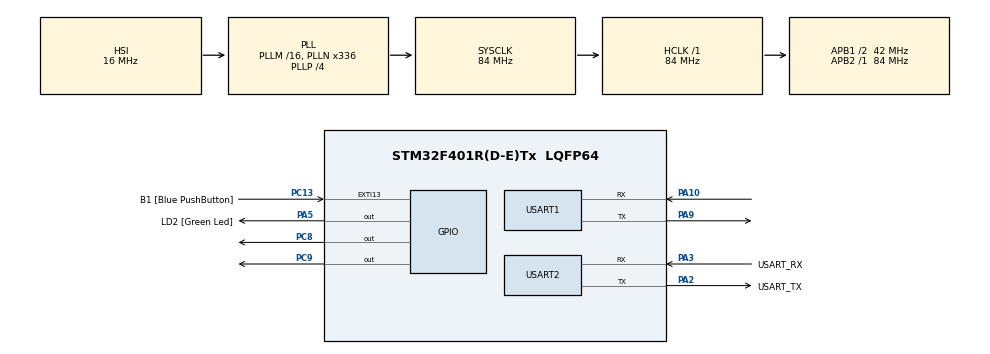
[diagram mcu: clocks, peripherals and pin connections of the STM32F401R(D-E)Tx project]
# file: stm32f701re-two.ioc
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Mcu.Family=STM32F4
Mcu.Name=STM32F401R(D-E)Tx
Mcu.Package=LQFP64
NVIC.PriorityGroup=NVIC_PRIORITYGROUP_0
PA10.Mode=Asynchronous
PA10.Signal=USART1_RX
PA13.GPIO_Label=TMS
PA13.Signal=SYS_JTMS-SWDIO
PA14.GPIO_Label=TCK
PA14.Signal=SYS_JTCK-SWCLK
PA2.GPIO_Label=USART_TX
PA2.GPIO_Mode=GPIO_MODE_AF_PP
PA2.GPIO_PuPd=GPIO_NOPULL
PA2.GPIO_Speed=GPIO_SPEED_FREQ_LOW
PA2.Mode=Asynchronous
PA2.Signal=USART2_TX
PA3.GPIO_Label=USART_RX
PA3.GPIO_Mode=GPIO_MODE_AF_PP
PA3.GPIO_PuPd=GPIO_NOPULL
PA3.GPIO_Speed=GPIO_SPEED_FREQ_LOW
PA3.Mode=Asynchronous
PA3.Signal=USART2_RX
PA5.GPIO_Label=LD2 [Green Led]
PA5.GPIO_Mode=GPIO_MODE_OUTPUT_PP
PA5.GPIO_PuPd=GPIO_NOPULL
PA5.GPIO_Speed=GPIO_SPEED_FREQ_LOW
PA5.Signal=GPIO_Output
PA9.Mode=Asynchronous
PA9.Signal=USART1_TX
PB3.GPIO_Label=SWO
PB3.Signal=SYS_JTDO-SWO
PC13-ANTI_TAMP.GPIO_Label=B1 [Blue PushButton]
PC13-ANTI_TAMP.GPIO_ModeDefaultEXTI=GPIO_MODE_IT_FALLING
PC13-ANTI_TAMP.GPIO_PuPd=GPIO_NOPULL
PC13-ANTI_TAMP.Signal=GPXTI13
PC14-OSC32_IN.Signal=RCC_OSC32_IN
PC15-OSC32_OUT.Signal=RCC_OSC32_OUT
PC8.Signal=GPIO_Output
PC9.Signal=GPIO_Output
PH0\ -\ OSC_IN.Signal=RCC_OSC_IN
PH1\ -\ OSC_OUT.Signal=RCC_OSC_OUT
ProjectManager.HeapSize=0x200
ProjectManager.StackSize=0x400
ProjectManager.TargetToolchain=STM32CubeIDE
RCC.AHBFreq_Value=84000000
RCC.APB1CLKDivider=RCC_HCLK_DIV2
RCC.APB1Freq_Value=42000000
RCC.APB1TimFreq_Value=84000000
RCC.APB2Freq_Value=84000000
RCC.APB2TimFreq_Value=84000000
RCC.CortexFreq_Value=84000000
RCC.HCLKFreq_Value=84000000
RCC.HSE_VALUE=8000000
RCC.HSI_VALUE=16000000
RCC.LSE_VALUE=32768
RCC.PLLN=336
RCC.PLLP=RCC_PLLP_DIV4
RCC.PLLQ=7
RCC.SYSCLKFreq_VALUE=84000000
RCC.SYSCLKSource=RCC_SYSCLKSOURCE_PLLCLK
RCC.VCOOutputFreq_Value=336000000
USART1.Parity=PARITY_EVEN
USART1.VirtualMode=VM_ASYNC
USART1.WordLength=WORDLENGTH_9B
USART2.VirtualMode=VM_ASYNC
board=NUCLEO-F401RE

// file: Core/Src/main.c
/* USER CODE BEGIN Header */
/**
  ******************************************************************************
  * @file           : main.c
  * @brief          : Main program body
  ******************************************************************************
  * @attention
  *
  * Copyright (c) 2022 STMicroelectronics.
  * All rights reserved.
  *
  * This software is licensed under terms that can be found in the LICENSE file
  * in the root directory of this software component.
  * If no LICENSE file comes with this software, it is provided AS-IS.
  *
  ******************************************************************************
  */
/* USER CODE END Header */
#include "main.h"

/* USER CODE BEGIN Includes */
#include "bootloader.h"
#include <string.h>
/* USER CODE END Includes */

UART_HandleTypeDef huart1;
UART_HandleTypeDef huart2;

/* USER CODE BEGIN PV */
uint8_t rcv_mul[10] = {0};
uint8_t receive_cmd_response_main = {0};
uint8_t it_response = {0};
//uint8_t invoke_uart = 0x7f;
uint8_t get_cmd[2] = {0x00, 0x00^0xff};
uint8_t bl_ver[2] = {0x01, 0x01^0xff};
uint8_t get_id_cmd[2] = {0x02, 0x02^0xff};
uint8_t read_memory_cmd[2] = {0x11, 0x11^0xff};
uint8_t write_memory_cmd[2] = {0x31, 0x31^0xff};
uint8_t clear_memory_cmd[2] = {0x44, 0x44^0xff};
uint8_t go_cmd[2] = {0x21, 0x21^0xff};

//binary(hex) to flash to target device
uint8_t bin_to_flash[] = {0x00, 0x00, 0x10, 0x24, 0x1D, 0x0C, 0x00, 0x08, 0xD9, 0x0A, 0x00, 0x08, 0xDF, 0x0A, 0x00, 0x08,
		  0xE5, 0x0A, 0x00, 0x08, 0xEB, 0x0A, 0x00, 0x08, 0xF1, 0x0A, 0x00, 0x08, 0x00, 0x00, 0x00, 0x00,
		  0x00, 0x00, 0x00, 0x00, 0x00, 0x00, 0x00, 0x00, 0x00, 0x00, 0x00, 0x00, 0xF7, 0x0A, 0x00, 0x08,
		  0x05, 0x0B, 0x00, 0x08, 0x00, 0x00, 0x00, 0x00, 0x13, 0x0B, 0x00, 0x08, 0x21, 0x0B, 0x00, 0x08,
		  0x6D, 0x0C, 0x00, 0x08, 0x6D, 0x0C, 0x00, 0x08, 0x6D, 0x0C, 0x00, 0x08, 0x6D, 0x0C, 0x00, 0x08,
		  0x6D, 0x0C, 0x00, 0x08, 0x6D, 0x0C, 0x00, 0x08, 0x6D, 0x0C, 0x00, 0x08, 0x6D, 0x0C, 0x00, 0x08,
		  0x6D, 0x0C, 0x00, 0x08, 0x6D, 0x0C, 0x00, 0x08, 0x6D, 0x0C, 0x00, 0x08, 0x6D, 0x0C, 0x00, 0x08,
		  0x6D, 0x0C, 0x00, 0x08, 0x6D, 0x0C, 0x00, 0x08, 0x6D, 0x0C, 0x00, 0x08, 0x6D, 0x0C, 0x00, 0x08,
		  0x6D, 0x0C, 0x00, 0x08, 0x6D, 0x0C, 0x00, 0x08, 0x6D, 0x0C, 0x00, 0x08, 0x6D, 0x0C, 0x00, 0x08,
		  0x6D, 0x0C, 0x00, 0x08, 0x6D, 0x0C, 0x00, 0x08, 0x6D, 0x0C, 0x00, 0x08, 0x6D, 0x0C, 0x00, 0x08,
		  0x6D, 0x0C, 0x00, 0x08, 0x6D, 0x0C, 0x00, 0x08, 0x6D, 0x0C, 0x00, 0x08, 0x6D, 0x0C, 0x00, 0x08,
		  0x6D, 0x0C, 0x00, 0x08, 0x6D, 0x0C, 0x00, 0x08, 0x6D, 0x0C, 0x00, 0x08, 0x6D, 0x0C, 0x00, 0x08,
		  0x6D, 0x0C, 0x00, 0x08, 0x6D, 0x0C, 0x00, 0x08, 0x6D, 0x0C, 0x00, 0x08, 0x6D, 0x0C, 0x00, 0x08,
		  0x6D, 0x0C, 0x00, 0x08, 0x6D, 0x0C, 0x00, 0x08, 0x6D, 0x0C, 0x00, 0x08, 0x6D, 0x0C, 0x00, 0x08,
		  0x6D, 0x0C, 0x00, 0x08, 0x6D, 0x0C, 0x00, 0x08, 0x6D, 0x0C, 0x00, 0x08, 0x6D, 0x0C, 0x00, 0x08,
		  0x6D, 0x0C, 0x00, 0x08, 0x6D, 0x0C, 0x00, 0x08, 0x6D, 0x0C, 0x00, 0x08, 0x6D, 0x0C, 0x00, 0x08,
		  0x6D, 0x0C, 0x00, 0x08, 0x6D, 0x0C, 0x00, 0x08, 0x6D, 0x0C, 0x00, 0x08, 0x6D, 0x0C, 0x00, 0x08,
		  0x6D, 0x0C, 0x00, 0x08, 0x6D, 0x0C, 0x00, 0x08, 0x6D, 0x0C, 0x00, 0x08, 0x6D, 0x0C, 0x00, 0x08,
		  0x6D, 0x0C, 0x00, 0x08, 0x6D, 0x0C, 0x00, 0x08, 0x6D, 0x0C, 0x00, 0x08, 0x6D, 0x0C, 0x00, 0x08,
		  0x6D, 0x0C, 0x00, 0x08, 0x00, 0x00, 0x00, 0x00, 0x00, 0x00, 0x00, 0x00, 0x6D, 0x0C, 0x00, 0x08,
		  0x6D, 0x0C, 0x00, 0x08, 0x6D, 0x0C, 0x00, 0x08, 0x6D, 0x0C, 0x00, 0x08, 0x6D, 0x0C, 0x00, 0x08,
		  0x6D, 0x0C, 0x00, 0x08, 0x6D, 0x0C, 0x00, 0x08, 0x6D, 0x0C, 0x00, 0x08, 0x6D, 0x0C, 0x00, 0x08,
		  0x6D, 0x0C, 0x00, 0x08, 0x6D, 0x0C, 0x00, 0x08, 0x6D, 0x0C, 0x00, 0x08, 0x6D, 0x0C, 0x00, 0x08,
		  0x6D, 0x0C, 0x00, 0x08, 0x6D, 0x0C, 0x00, 0x08, 0x6D, 0x0C, 0x00, 0x08, 0x00, 0x00, 0x00, 0x00,
		  0x6D, 0x0C, 0x00, 0x08, 0x6D, 0x0C, 0x00, 0x08, 0x6D, 0x0C, 0x00, 0x08, 0x6D, 0x0C, 0x00, 0x08,
		  0x6D, 0x0C, 0x00, 0x08, 0x6D, 0x0C, 0x00, 0x08, 0x6D, 0x0C, 0x00, 0x08, 0x6D, 0x0C, 0x00, 0x08,
		  0x6D, 0x0C, 0x00, 0x08, 0x6D, 0x0C, 0x00, 0x08, 0x6D, 0x0C, 0x00, 0x08, 0x6D, 0x0C, 0x00, 0x08,
		  0x6D, 0x0C, 0x00, 0x08, 0x6D, 0x0C, 0x00, 0x08, 0x6D, 0x0C, 0x00, 0x08, 0x6D, 0x0C, 0x00, 0x08,
		  0x6D, 0x0C, 0x00, 0x08, 0x6D, 0x0C, 0x00, 0x08, 0x00, 0x00, 0x00, 0x00, 0x00, 0x00, 0x00, 0x00,
		  0x00, 0x00, 0x00, 0x00, 0x00, 0x00, 0x00, 0x00, 0x6D, 0x0C, 0x00, 0x08, 0x00, 0x00, 0x00, 0x00,
		  0x00, 0x00, 0x00, 0x00, 0x00, 0x00, 0x00, 0x00, 0x00, 0x00, 0x00, 0x00, 0x00, 0x00, 0x00, 0x00,
		  0x00, 0x00, 0x00, 0x00, 0x00, 0x00, 0x00, 0x00, 0x6D, 0x0C, 0x00, 0x08, 0x6D, 0x0C, 0x00, 0x08,
		  0x6D, 0x0C, 0x00, 0x08, 0x6D, 0x0C, 0x00, 0x08, 0x00, 0x00, 0x00, 0x00, 0x6D, 0x0C, 0x00, 0x08,
		  0x6D, 0x0C, 0x00, 0x08, 0x6D, 0x0C, 0x00, 0x08, 0x6D, 0x0C, 0x00, 0x08, 0x6D, 0x0C, 0x00, 0x08,
		  0x6D, 0x0C, 0x00, 0x08, 0x6D, 0x0C, 0x00, 0x08, 0x6D, 0x0C, 0x00, 0x08, 0x00, 0x00, 0x00, 0x00,
		  0x6D, 0x0C, 0x00, 0x08, 0x6D, 0x0C, 0x00, 0x08, 0x00, 0x00, 0x00, 0x00, 0x6D, 0x0C, 0x00, 0x08,
		  0x6D, 0x0C, 0x00, 0x08, 0x6D, 0x0C, 0x00, 0x08, 0x6D, 0x0C, 0x00, 0x08, 0x6D, 0x0C, 0x00, 0x08,
		  0x6D, 0x0C, 0x00, 0x08, 0x6D, 0x0C, 0x00, 0x08, 0x6D, 0x0C, 0x00, 0x08, 0x6D, 0x0C, 0x00, 0x08,
		  0x6D, 0x0C, 0x00, 0x08, 0x6D, 0x0C, 0x00, 0x08, 0x6D, 0x0C, 0x00, 0x08, 0x6D, 0x0C, 0x00, 0x08,
		  0x6D, 0x0C, 0x00, 0x08, 0x6D, 0x0C, 0x00, 0x08, 0x6D, 0x0C, 0x00, 0x08, 0x00, 0x00, 0x00, 0x00,
		  0x6D, 0x0C, 0x00, 0x08, 0x6D, 0x0C, 0x00, 0x08, 0x00, 0x00, 0x00, 0x00, 0x6D, 0x0C, 0x00, 0x08,
		  0x00, 0x00, 0x00, 0x00, 0x6D, 0x0C, 0x00, 0x08, 0x6D, 0x0C, 0x00, 0x08, 0x00, 0x00, 0x00, 0x00,
		  0x00, 0x00, 0x00, 0x00, 0x6D, 0x0C, 0x00, 0x08, 0x6D, 0x0C, 0x00, 0x08, 0x10, 0xB5, 0x05, 0x4C,
		  0x23, 0x78, 0x33, 0xB9, 0x04, 0x4B, 0x13, 0xB1, 0x04, 0x48, 0xAF, 0xF3, 0x00, 0x80, 0x01, 0x23,
		  0x23, 0x70, 0x10, 0xBD, 0x10, 0x00, 0x00, 0x24, 0x00, 0x00, 0x00, 0x00, 0xC0, 0x4C, 0x00, 0x08,
		  0x08, 0xB5, 0x03, 0x4B, 0x1B, 0xB1, 0x03, 0x49, 0x03, 0x48, 0xAF, 0xF3, 0x00, 0x80, 0x08, 0xBD,
		  0x00, 0x00, 0x00, 0x00, 0x14, 0x00, 0x00, 0x24, 0xC0, 0x4C, 0x00, 0x08, 0x53, 0xB9, 0x4A, 0xB9,
		  0x00, 0x29, 0x08, 0xBF, 0x00, 0x28, 0x1C, 0xBF, 0x4F, 0xF0, 0xFF, 0x31, 0x4F, 0xF0, 0xFF, 0x30,
		  0x00, 0xF0, 0x6E, 0xB9, 0xAD, 0xF1, 0x08, 0x0C, 0x6D, 0xE9, 0x04, 0xCE, 0x00, 0xF0, 0x06, 0xF8,
		  0xDD, 0xF8, 0x04, 0xE0, 0xDD, 0xE9, 0x02, 0x23, 0x04, 0xB0, 0x70, 0x47, 0x2D, 0xE9, 0xF0, 0x47,
		  0x08, 0x9D, 0x04, 0x46, 0x8C, 0x46, 0x00, 0x2B, 0x40, 0xF0, 0x83, 0x80, 0x8A, 0x42, 0x17, 0x46,
		  0x47, 0xD9, 0xB2, 0xFA, 0x82, 0xF2, 0x42, 0xB1, 0xC2, 0xF1, 0x20, 0x00, 0x24, 0xFA, 0x00, 0xF0,
		  0x91, 0x40, 0x97, 0x40, 0x40, 0xEA, 0x01, 0x0C, 0x94, 0x40, 0x4F, 0xEA, 0x17, 0x48, 0x23, 0x0C,
		  0xBC, 0xFB, 0xF8, 0xF6, 0x1F, 0xFA, 0x87, 0xFE, 0x08, 0xFB, 0x16, 0xC1, 0x43, 0xEA, 0x01, 0x43,
		  0x06, 0xFB, 0x0E, 0xF1, 0x99, 0x42, 0x09, 0xD9, 0xFB, 0x18, 0x06, 0xF1, 0xFF, 0x30, 0x80, 0xF0,
		  0x19, 0x81, 0x99, 0x42, 0x40, 0xF2, 0x16, 0x81, 0x02, 0x3E, 0x3B, 0x44, 0x5B, 0x1A, 0xA4, 0xB2,
		  0xB3, 0xFB, 0xF8, 0xF0, 0x08, 0xFB, 0x10, 0x33, 0x44, 0xEA, 0x03, 0x44, 0x00, 0xFB, 0x0E, 0xFE,
		  0xA6, 0x45, 0x09, 0xD9, 0x3C, 0x19, 0x00, 0xF1, 0xFF, 0x33, 0x80, 0xF0, 0x05, 0x81, 0xA6, 0x45,
		  0x40, 0xF2, 0x02, 0x81, 0x02, 0x38, 0x3C, 0x44, 0x40, 0xEA, 0x06, 0x40, 0xA4, 0xEB, 0x0E, 0x04,
		  0x00, 0x26, 0x1D, 0xB1, 0xD4, 0x40, 0x00, 0x23, 0xC5, 0xE9, 0x00, 0x43, 0x31, 0x46, 0xBD, 0xE8,
		  0xF0, 0x87, 0x02, 0xB9, 0xFF, 0xDE, 0xB2, 0xFA, 0x82, 0xF2, 0x00, 0x2A, 0x50, 0xD1, 0xCB, 0x1B,
		  0x4F, 0xEA, 0x17, 0x4E, 0x1F, 0xFA, 0x87, 0xF8, 0x01, 0x26, 0xB3, 0xFB, 0xFE, 0xFC, 0x21, 0x0C,
		  0x0E, 0xFB, 0x1C, 0x33, 0x41, 0xEA, 0x03, 0x41, 0x08, 0xFB, 0x0C, 0xF3, 0x8B, 0x42, 0x07, 0xD9,
		  0x79, 0x18, 0x0C, 0xF1, 0xFF, 0x30, 0x02, 0xD2, 0x8B, 0x42, 0x00, 0xF2, 0xE9, 0x80, 0x84, 0x46,
		  0xC9, 0x1A, 0xA3, 0xB2, 0xB1, 0xFB, 0xFE, 0xF0, 0x0E, 0xFB, 0x10, 0x11, 0x43, 0xEA, 0x01, 0x44,
		  0x08, 0xFB, 0x00, 0xF8, 0xA0, 0x45, 0x07, 0xD9, 0x3C, 0x19, 0x00, 0xF1, 0xFF, 0x33, 0x02, 0xD2,
		  0xA0, 0x45, 0x00, 0xF2, 0xD9, 0x80, 0x18, 0x46, 0xA4, 0xEB, 0x08, 0x04, 0x40, 0xEA, 0x0C, 0x40,
		  0xBF, 0xE7, 0x8B, 0x42, 0x09, 0xD9, 0x00, 0x2D, 0x00, 0xF0, 0xB1, 0x80, 0x00, 0x26, 0xC5, 0xE9,
		  0x00, 0x01, 0x30, 0x46, 0x31, 0x46, 0xBD, 0xE8, 0xF0, 0x87, 0xB3, 0xFA, 0x83, 0xF6, 0x00, 0x2E,
		  0x4A, 0xD1, 0x8B, 0x42, 0x02, 0xD3, 0x82, 0x42, 0x00, 0xF2, 0xB8, 0x80, 0x84, 0x1A, 0x61, 0xEB,
		  0x03, 0x01, 0x01, 0x20, 0x8C, 0x46, 0x00, 0x2D, 0xA8, 0xD0, 0xC5, 0xE9, 0x00, 0x4C, 0xA5, 0xE7,
		  0xC2, 0xF1, 0x20, 0x03, 0x20, 0xFA, 0x03, 0xF6, 0x97, 0x40, 0x01, 0xFA, 0x02, 0xF0, 0x4F, 0xEA,
		  0x17, 0x4E, 0xD9, 0x40, 0x30, 0x43, 0x03, 0x0C, 0xB1, 0xFB, 0xFE, 0xF6, 0x1F, 0xFA, 0x87, 0xF8,
		  0x0E, 0xFB, 0x16, 0x11, 0x43, 0xEA, 0x01, 0x43, 0x06, 0xFB, 0x08, 0xF1, 0x99, 0x42, 0x04, 0xFA,
		  0x02, 0xF4, 0x09, 0xD9, 0xFB, 0x18, 0x06, 0xF1, 0xFF, 0x3C, 0x80, 0xF0, 0x8D, 0x80, 0x99, 0x42,
		  0x40, 0xF2, 0x8A, 0x80, 0x02, 0x3E, 0x3B, 0x44, 0x5B, 0x1A, 0x81, 0xB2, 0xB3, 0xFB, 0xFE, 0xF0,
		  0x0E, 0xFB, 0x10, 0x33, 0x41, 0xEA, 0x03, 0x41, 0x00, 0xFB, 0x08, 0xF3, 0x8B, 0x42, 0x07, 0xD9,
		  0x79, 0x18, 0x00, 0xF1, 0xFF, 0x3C, 0x73, 0xD2, 0x8B, 0x42, 0x71, 0xD9, 0x02, 0x38, 0x39, 0x44,
		  0xCB, 0x1A, 0x40, 0xEA, 0x06, 0x46, 0x78, 0xE7, 0xC6, 0xF1, 0x20, 0x0C, 0x03, 0xFA, 0x06, 0xF4,
		  0x22, 0xFA, 0x0C, 0xF3, 0x1C, 0x43, 0x20, 0xFA, 0x0C, 0xF7, 0x01, 0xFA, 0x06, 0xF3, 0x4F, 0xEA,
		  0x14, 0x4E, 0x21, 0xFA, 0x0C, 0xF1, 0x1F, 0x43, 0x3B, 0x0C, 0xB1, 0xFB, 0xFE, 0xF9, 0x1F, 0xFA,
		  0x84, 0xF8, 0x0E, 0xFB, 0x19, 0x11, 0x43, 0xEA, 0x01, 0x41, 0x09, 0xFB, 0x08, 0xFA, 0x8A, 0x45,
		  0x02, 0xFA, 0x06, 0xF2, 0x00, 0xFA, 0x06, 0xF3, 0x08, 0xD9, 0x61, 0x18, 0x09, 0xF1, 0xFF, 0x30,
		  0x48, 0xD2, 0x8A, 0x45, 0x46, 0xD9, 0xA9, 0xF1, 0x02, 0x09, 0x21, 0x44, 0xA1, 0xEB, 0x0A, 0x01,
		  0xBF, 0xB2, 0xB1, 0xFB, 0xFE, 0xF0, 0x0E, 0xFB, 0x10, 0x11, 0x47, 0xEA, 0x01, 0x47, 0x00, 0xFB,
		  0x08, 0xF8, 0xB8, 0x45, 0x07, 0xD9, 0xE7, 0x19, 0x00, 0xF1, 0xFF, 0x31, 0x2E, 0xD2, 0xB8, 0x45,
		  0x2C, 0xD9, 0x02, 0x38, 0x27, 0x44, 0x40, 0xEA, 0x09, 0x40, 0xA7, 0xEB, 0x08, 0x07, 0xA0, 0xFB,
		  0x02, 0x89, 0x4F, 0x45, 0xC6, 0x46, 0x49, 0x46, 0x1A, 0xD3, 0x17, 0xD0, 0x5D, 0xB1, 0xB3, 0xEB,
		  0x0E, 0x02, 0x67, 0xEB, 0x01, 0x07, 0x07, 0xFA, 0x0C, 0xFC, 0xF2, 0x40, 0x4C, 0xEA, 0x02, 0x02,
		  0xF7, 0x40, 0xC5, 0xE9, 0x00, 0x27, 0x00, 0x26, 0x31, 0x46, 0xBD, 0xE8, 0xF0, 0x87, 0x2E, 0x46,
		  0x28, 0x46, 0x0B, 0xE7, 0x06, 0x46, 0xE9, 0xE6, 0x18, 0x46, 0xFD, 0xE6, 0x43, 0x45, 0xE5, 0xD2,
		  0xB8, 0xEB, 0x02, 0x0E, 0x69, 0xEB, 0x04, 0x01, 0x01, 0x38, 0xDF, 0xE7, 0x08, 0x46, 0xD2, 0xE7,
		  0x60, 0x46, 0x8D, 0xE7, 0x81, 0x46, 0xB9, 0xE7, 0x66, 0x46, 0x75, 0xE7, 0x30, 0x46, 0x4A, 0xE7,
		  0xAC, 0xF1, 0x02, 0x0C, 0x39, 0x44, 0x13, 0xE7, 0x02, 0x38, 0x3C, 0x44, 0x24, 0xE7, 0x00, 0xBF,
		  0x70, 0x47, 0x00, 0xBF, 0x80, 0xB5, 0x00, 0xAF, 0x00, 0xF0, 0x42, 0xFB, 0x00, 0xF0, 0x10, 0xF8,
		  0x00, 0xF0, 0xCE, 0xF8, 0x00, 0xF0, 0x80, 0xF8, 0x4F, 0xF4, 0x80, 0x41, 0x03, 0x48, 0x00, 0xF0,
		  0x9A, 0xFE, 0x4F, 0xF4, 0x7A, 0x70, 0x00, 0xF0, 0xC5, 0xFB, 0xF5, 0xE7, 0x00, 0x04, 0x02, 0x58,
		  0x80, 0xB5, 0x9C, 0xB0, 0x00, 0xAF, 0x07, 0xF1, 0x24, 0x03, 0x4C, 0x22, 0x00, 0x21, 0x18, 0x46,
		  0x04, 0xF0, 0x46, 0xFB, 0x3B, 0x1D, 0x20, 0x22, 0x00, 0x21, 0x18, 0x46, 0x04, 0xF0, 0x40, 0xFB,
		  0x2F, 0x4B, 0x4F, 0xF0, 0xFF, 0x32, 0xC3, 0xF8, 0xB0, 0x20, 0x04, 0x20, 0x00, 0xF0, 0x96, 0xFE,
		  0x00, 0x23, 0x3B, 0x60, 0x2B, 0x4B, 0x9B, 0x69, 0x2A, 0x4A, 0x43, 0xF4, 0x40, 0x43, 0x93, 0x61,
		  0x28, 0x4B, 0x9B, 0x69, 0x03, 0xF4, 0x40, 0x43, 0x3B, 0x60, 0x3B, 0x68, 0x00, 0xBF, 0x25, 0x4B,
		  0x9B, 0x69, 0x03, 0xF4, 0x00, 0x53, 0xB3, 0xF5, 0x00, 0x5F, 0xF8, 0xD1, 0x02, 0x23, 0x7B, 0x62,
		  0x01, 0x23, 0x3B, 0x63, 0x40, 0x23, 0x7B, 0x63, 0x02, 0x23, 0xBB, 0x64, 0x00, 0x23, 0xFB, 0x64,
		  0x04, 0x23, 0x3B, 0x65, 0x08, 0x23, 0x7B, 0x65, 0x02, 0x23, 0xBB, 0x65, 0x04, 0x23, 0xFB, 0x65,
		  0x02, 0x23, 0x3B, 0x66, 0x0C, 0x23, 0x7B, 0x66, 0x00, 0x23, 0xBB, 0x66, 0x00, 0x23, 0xFB, 0x66,
		  0x07, 0xF1, 0x24, 0x03, 0x18, 0x46, 0x00, 0xF0, 0xBB, 0xFE, 0x03, 0x46, 0x00, 0x2B, 0x01, 0xD0,
		  0x00, 0xF0, 0x8E, 0xF9, 0x3F, 0x23, 0x7B, 0x60, 0x03, 0x23, 0xBB, 0x60, 0x00, 0x23, 0xFB, 0x60,
		  0x00, 0x23, 0x3B, 0x61, 0x00, 0x23, 0x7B, 0x61, 0x00, 0x23, 0xBB, 0x61, 0x00, 0x23, 0xFB, 0x61,
		  0x00, 0x23, 0x3B, 0x62, 0x3B, 0x1D, 0x01, 0x21, 0x18, 0x46, 0x01, 0xF0, 0xA5, 0xFA, 0x03, 0x46,
		  0x00, 0x2B, 0x01, 0xD0, 0x00, 0xF0, 0x74, 0xF9, 0x00, 0xBF, 0x70, 0x37, 0xBD, 0x46, 0x80, 0xBD,
		  0x00, 0x44, 0x02, 0x58, 0x00, 0x48, 0x02, 0x58, 0x80, 0xB5, 0x00, 0xAF, 0x22, 0x4B, 0x23, 0x4A,
		  0x1A, 0x60, 0x21, 0x4B, 0x4F, 0xF4, 0xE1, 0x32, 0x5A, 0x60, 0x1F, 0x4B, 0x00, 0x22, 0x9A, 0x60,
		  0x1D, 0x4B, 0x00, 0x22, 0xDA, 0x60, 0x1C, 0x4B, 0x00, 0x22, 0x1A, 0x61, 0x1A, 0x4B, 0x0C, 0x22,
		  0x5A, 0x61, 0x19, 0x4B, 0x00, 0x22, 0x9A, 0x61, 0x17, 0x4B, 0x00, 0x22, 0xDA, 0x61, 0x16, 0x4B,
		  0x00, 0x22, 0x1A, 0x62, 0x14, 0x4B, 0x00, 0x22, 0x5A, 0x62, 0x13, 0x4B, 0x00, 0x22, 0x9A, 0x62,
		  0x11, 0x48, 0x03, 0xF0, 0x2B, 0xF9, 0x03, 0x46, 0x00, 0x2B, 0x01, 0xD0, 0x00, 0xF0, 0x40, 0xF9,
		  0x00, 0x21, 0x0D, 0x48, 0x04, 0xF0, 0xBE, 0xF9, 0x03, 0x46, 0x00, 0x2B, 0x01, 0xD0, 0x00, 0xF0,
		  0x37, 0xF9, 0x00, 0x21, 0x08, 0x48, 0x04, 0xF0, 0xF3, 0xF9, 0x03, 0x46, 0x00, 0x2B, 0x01, 0xD0,
		  0x00, 0xF0, 0x2E, 0xF9, 0x04, 0x48, 0x04, 0xF0, 0x74, 0xF9, 0x03, 0x46, 0x00, 0x2B, 0x01, 0xD0,
		  0x00, 0xF0, 0x26, 0xF9, 0x00, 0xBF, 0x80, 0xBD, 0x2C, 0x00, 0x00, 0x24, 0x00, 0x4C, 0x00, 0x40,
		  0x80, 0xB5, 0x8E, 0xB0, 0x00, 0xAF, 0x07, 0xF1, 0x24, 0x03, 0x00, 0x22, 0x1A, 0x60, 0x5A, 0x60,
		  0x9A, 0x60, 0xDA, 0x60, 0x1A, 0x61, 0x82, 0x4B, 0xD3, 0xF8, 0x40, 0x31, 0x80, 0x4A, 0x43, 0xF0,
		  0x04, 0x03, 0xC2, 0xF8, 0x40, 0x31, 0x7E, 0x4B, 0xD3, 0xF8, 0x40, 0x31, 0x03, 0xF0, 0x04, 0x03,
		  0x3B, 0x62, 0x3B, 0x6A, 0x7A, 0x4B, 0xD3, 0xF8, 0x40, 0x31, 0x79, 0x4A, 0x43, 0xF0, 0x20, 0x03,
		  0xC2, 0xF8, 0x40, 0x31, 0x76, 0x4B, 0xD3, 0xF8, 0x40, 0x31, 0x03, 0xF0, 0x20, 0x03, 0xFB, 0x61,
		  0xFB, 0x69, 0x73, 0x4B, 0xD3, 0xF8, 0x40, 0x31, 0x71, 0x4A, 0x43, 0xF0, 0x80, 0x03, 0xC2, 0xF8,
		  0x40, 0x31, 0x6F, 0x4B, 0xD3, 0xF8, 0x40, 0x31, 0x03, 0xF0, 0x80, 0x03, 0xBB, 0x61, 0xBB, 0x69,
		  0x6B, 0x4B, 0xD3, 0xF8, 0x40, 0x31, 0x6A, 0x4A, 0x43, 0xF0, 0x01, 0x03, 0xC2, 0xF8, 0x40, 0x31,
		  0x67, 0x4B, 0xD3, 0xF8, 0x40, 0x31, 0x03, 0xF0, 0x01, 0x03, 0x7B, 0x61, 0x7B, 0x69, 0x64, 0x4B,
		  0xD3, 0xF8, 0x40, 0x31, 0x62, 0x4A, 0x43, 0xF0, 0x02, 0x03, 0xC2, 0xF8, 0x40, 0x31, 0x60, 0x4B,
		  0xD3, 0xF8, 0x40, 0x31, 0x03, 0xF0, 0x02, 0x03, 0x3B, 0x61, 0x3B, 0x69, 0x5C, 0x4B, 0xD3, 0xF8,
		  0x40, 0x31, 0x5B, 0x4A, 0x43, 0xF0, 0x08, 0x03, 0xC2, 0xF8, 0x40, 0x31, 0x58, 0x4B, 0xD3, 0xF8,
		  0x40, 0x31, 0x03, 0xF0, 0x08, 0x03, 0xFB, 0x60, 0xFB, 0x68, 0x55, 0x4B, 0xD3, 0xF8, 0x40, 0x31,
		  0x53, 0x4A, 0x43, 0xF0, 0x40, 0x03, 0xC2, 0xF8, 0x40, 0x31, 0x51, 0x4B, 0xD3, 0xF8, 0x40, 0x31,
		  0x03, 0xF0, 0x40, 0x03, 0xBB, 0x60, 0xBB, 0x68, 0x4D, 0x4B, 0xD3, 0xF8, 0x40, 0x31, 0x4C, 0x4A,
		  0x43, 0xF0, 0x10, 0x03, 0xC2, 0xF8, 0x40, 0x31, 0x49, 0x4B, 0xD3, 0xF8, 0x40, 0x31, 0x03, 0xF0,
		  0x10, 0x03, 0x7B, 0x60, 0x7B, 0x68, 0x00, 0x22, 0x4F, 0xF4, 0x80, 0x61, 0x45, 0x48, 0x00, 0xF0,
		  0x31, 0xFD, 0x00, 0x22, 0x44, 0xF2, 0x01, 0x01, 0x43, 0x48, 0x00, 0xF0, 0x2B, 0xFD, 0x00, 0x22,
		  0x02, 0x21, 0x42, 0x48, 0x00, 0xF0, 0x26, 0xFD, 0x4F, 0xF4, 0x00, 0x53, 0x7B, 0x62, 0x00, 0x23,
		  0xBB, 0x62, 0x00, 0x23, 0xFB, 0x62, 0x07, 0xF1, 0x24, 0x03, 0x19, 0x46, 0x3C, 0x48, 0x00, 0xF0,
		  0x69, 0xFB, 0x4F, 0xF4, 0x80, 0x63, 0x7B, 0x62, 0x01, 0x23, 0xBB, 0x62, 0x00, 0x23, 0xFB, 0x62,
		  0x00, 0x23, 0x3B, 0x63, 0x07, 0xF1, 0x24, 0x03, 0x19, 0x46, 0x32, 0x48, 0x00, 0xF0, 0x5A, 0xFB,
		  0x44, 0xF2, 0x01, 0x03, 0x7B, 0x62, 0x01, 0x23, 0xBB, 0x62, 0x00, 0x23, 0xFB, 0x62, 0x00, 0x23,
		  0x3B, 0x63, 0x07, 0xF1, 0x24, 0x03, 0x19, 0x46, 0x2B, 0x48, 0x00, 0xF0, 0x4B, 0xFB, 0x4F, 0xF4,
		  0x40, 0x73, 0x7B, 0x62, 0x02, 0x23, 0xBB, 0x62, 0x00, 0x23, 0xFB, 0x62, 0x00, 0x23, 0x3B, 0x63,
		  0x07, 0x23, 0x7B, 0x63, 0x07, 0xF1, 0x24, 0x03, 0x19, 0x46, 0x26, 0x48, 0x00, 0xF0, 0x3A, 0xFB,
		  0x80, 0x23, 0x7B, 0x62, 0x4F, 0xF4, 0x88, 0x13, 0xBB, 0x62, 0x00, 0x23, 0xFB, 0x62, 0x07, 0xF1,
		  0x24, 0x03, 0x19, 0x46, 0x20, 0x48, 0x00, 0xF0, 0x2D, 0xFB, 0x4F, 0xF4, 0x80, 0x63, 0x7B, 0x62,
		  0x02, 0x23, 0xBB, 0x62, 0x00, 0x23, 0xFB, 0x62, 0x00, 0x23, 0x3B, 0x63, 0x0A, 0x23, 0x7B, 0x63,
		  0x07, 0xF1, 0x24, 0x03, 0x19, 0x46, 0x19, 0x48, 0x00, 0xF0, 0x1C, 0xFB, 0x4F, 0xF4, 0xC0, 0x53,
		  0x7B, 0x62, 0x02, 0x23, 0xBB, 0x62, 0x00, 0x23, 0xFB, 0x62, 0x00, 0x23, 0x3B, 0x63, 0x07, 0xF1,
		  0x24, 0x03, 0x19, 0x46, 0x11, 0x48, 0x00, 0xF0, 0x0D, 0xFB, 0x02, 0x23, 0x7B, 0x62, 0x01, 0x23,
		  0xBB, 0x62, 0x00, 0x23, 0xFB, 0x62, 0x00, 0x23, 0x3B, 0x63, 0x07, 0xF1, 0x24, 0x03, 0x19, 0x46,
		  0x06, 0x48, 0x00, 0xF0, 0xFF, 0xFA, 0x00, 0xBF, 0x38, 0x37, 0xBD, 0x46, 0x80, 0xBD, 0x00, 0xBF,
		  0x00, 0x44, 0x02, 0x58, 0x00, 0x14, 0x02, 0x58, 0x00, 0x04, 0x02, 0x58, 0x00, 0x10, 0x02, 0x58,
		  0x00, 0x08, 0x02, 0x58, 0x00, 0x0C, 0x02, 0x58, 0x00, 0x18, 0x02, 0x58, 0x00, 0x00, 0x02, 0x58,
		  0x80, 0xB4, 0x00, 0xAF, 0x72, 0xB6, 0x00, 0xBF, 0xFE, 0xE7, 0x00, 0x00, 0x80, 0xB4, 0x83, 0xB0,
		  0x00, 0xAF, 0x0A, 0x4B, 0xD3, 0xF8, 0x54, 0x31, 0x08, 0x4A, 0x43, 0xF0, 0x02, 0x03, 0xC2, 0xF8,
		  0x54, 0x31, 0x06, 0x4B, 0xD3, 0xF8, 0x54, 0x31, 0x03, 0xF0, 0x02, 0x03, 0x7B, 0x60, 0x7B, 0x68,
		  0x00, 0xBF, 0x0C, 0x37, 0xBD, 0x46, 0x5D, 0xF8, 0x04, 0x7B, 0x70, 0x47, 0x00, 0x44, 0x02, 0x58,
		  0x80, 0xB5, 0xB8, 0xB0, 0x00, 0xAF, 0x78, 0x60, 0x07, 0xF1, 0xCC, 0x03, 0x00, 0x22, 0x1A, 0x60,
		  0x5A, 0x60, 0x9A, 0x60, 0xDA, 0x60, 0x1A, 0x61, 0x07, 0xF1, 0x14, 0x03, 0xB8, 0x22, 0x00, 0x21,
		  0x18, 0x46, 0x04, 0xF0, 0x3D, 0xF9, 0x7B, 0x68, 0x1B, 0x68, 0x24, 0x4A, 0x93, 0x42, 0x41, 0xD1,
		  0x02, 0x23, 0x7B, 0x61, 0x00, 0x23, 0xC7, 0xF8, 0x90, 0x30, 0x07, 0xF1, 0x14, 0x03, 0x18, 0x46,
		  0x01, 0xF0, 0x76, 0xFC, 0x03, 0x46, 0x00, 0x2B, 0x01, 0xD0, 0xFF, 0xF7, 0xB9, 0xFF, 0x1C, 0x4B,
		  0xD3, 0xF8, 0x48, 0x31, 0x1A, 0x4A, 0x43, 0xF4, 0x00, 0x23, 0xC2, 0xF8, 0x48, 0x31, 0x18, 0x4B,
		  0xD3, 0xF8, 0x48, 0x31, 0x03, 0xF4, 0x00, 0x23, 0x3B, 0x61, 0x3B, 0x69, 0x14, 0x4B, 0xD3, 0xF8,
		  0x40, 0x31, 0x13, 0x4A, 0x43, 0xF0, 0x01, 0x03, 0xC2, 0xF8, 0x40, 0x31, 0x10, 0x4B, 0xD3, 0xF8,
		  0x40, 0x31, 0x03, 0xF0, 0x01, 0x03, 0xFB, 0x60, 0xFB, 0x68, 0x03, 0x23, 0xC7, 0xF8, 0xCC, 0x30,
		  0x02, 0x23, 0xC7, 0xF8, 0xD0, 0x30, 0x00, 0x23, 0xC7, 0xF8, 0xD4, 0x30, 0x00, 0x23, 0xC7, 0xF8,
		  0xD8, 0x30, 0x08, 0x23, 0xC7, 0xF8, 0xDC, 0x30, 0x07, 0xF1, 0xCC, 0x03, 0x19, 0x46, 0x05, 0x48,
		  0x00, 0xF0, 0x70, 0xFA, 0x00, 0xBF, 0xE0, 0x37, 0xBD, 0x46, 0x80, 0xBD, 0x00, 0x4C, 0x00, 0x40,
		  0x00, 0x44, 0x02, 0x58, 0x00, 0x00, 0x02, 0x58, 0x80, 0xB4, 0x00, 0xAF, 0xFE, 0xE7, 0x80, 0xB4,
		  0x00, 0xAF, 0xFE, 0xE7, 0x80, 0xB4, 0x00, 0xAF, 0xFE, 0xE7, 0x80, 0xB4, 0x00, 0xAF, 0xFE, 0xE7,
		  0x80, 0xB4, 0x00, 0xAF, 0xFE, 0xE7, 0x80, 0xB4, 0x00, 0xAF, 0x00, 0xBF, 0xBD, 0x46, 0x5D, 0xF8,
		  0x04, 0x7B, 0x70, 0x47, 0x80, 0xB4, 0x00, 0xAF, 0x00, 0xBF, 0xBD, 0x46, 0x5D, 0xF8, 0x04, 0x7B,
		  0x70, 0x47, 0x80, 0xB4, 0x00, 0xAF, 0x00, 0xBF, 0xBD, 0x46, 0x5D, 0xF8, 0x04, 0x7B, 0x70, 0x47,
		  0x80, 0xB5, 0x00, 0xAF, 0x00, 0xF0, 0x16, 0xF9, 0x00, 0xBF, 0x80, 0xBD, 0x80, 0xB4, 0x00, 0xAF,
		  0x32, 0x4B, 0xD3, 0xF8, 0x88, 0x30, 0x31, 0x4A, 0x43, 0xF4, 0x70, 0x03, 0xC2, 0xF8, 0x88, 0x30,
		  0x2F, 0x4B, 0x1B, 0x68, 0x03, 0xF0, 0x0F, 0x03, 0x02, 0x2B, 0x07, 0xD8, 0x2C, 0x4B, 0x1B, 0x68,
		  0x23, 0xF0, 0x0F, 0x03, 0x2A, 0x4A, 0x43, 0xF0, 0x03, 0x03, 0x13, 0x60, 0x29, 0x4B, 0x1B, 0x68,
		  0x28, 0x4A, 0x43, 0xF0, 0x01, 0x03, 0x13, 0x60, 0x26, 0x4B, 0x00, 0x22, 0x1A, 0x61, 0x25, 0x4B,
		  0x1A, 0x68, 0x24, 0x49, 0x24, 0x4B, 0x13, 0x40, 0x0B, 0x60, 0x21, 0x4B, 0x1B, 0x68, 0x03, 0xF0,
		  0x0C, 0x03, 0x00, 0x2B, 0x07, 0xD0, 0x1E, 0x4B, 0x1B, 0x68, 0x23, 0xF0, 0x0F, 0x03, 0x1C, 0x4A,
		  0x43, 0xF0, 0x03, 0x03, 0x13, 0x60, 0x1B, 0x4B, 0x00, 0x22, 0x9A, 0x61, 0x19, 0x4B, 0x00, 0x22,
		  0xDA, 0x61, 0x18, 0x4B, 0x00, 0x22, 0x1A, 0x62, 0x16, 0x4B, 0x18, 0x4A, 0x9A, 0x62, 0x15, 0x4B,
		  0x17, 0x4A, 0xDA, 0x62, 0x13, 0x4B, 0x17, 0x4A, 0x1A, 0x63, 0x12, 0x4B, 0x00, 0x22, 0x5A, 0x63,
		  0x10, 0x4B, 0x14, 0x4A, 0x9A, 0x63, 0x0F, 0x4B, 0x00, 0x22, 0xDA, 0x63, 0x0D, 0x4B, 0x11, 0x4A,
		  0x1A, 0x64, 0x0C, 0x4B, 0x00, 0x22, 0x5A, 0x64, 0x0A, 0x4B, 0x1B, 0x68, 0x09, 0x4A, 0x23, 0xF4,
		  0x80, 0x23, 0x13, 0x60, 0x07, 0x4B, 0x00, 0x22, 0x1A, 0x66, 0x0B, 0x4B, 0x43, 0xF2, 0xD2, 0x02,
		  0x1A, 0x60, 0x00, 0xBF, 0xBD, 0x46, 0x5D, 0xF8, 0x04, 0x7B, 0x70, 0x47, 0x00, 0xED, 0x00, 0xE0,
		  0x00, 0x20, 0x00, 0x52, 0x00, 0x44, 0x02, 0x58, 0x7F, 0xED, 0xF6, 0xEA, 0x00, 0x02, 0x02, 0x02,
		  0x00, 0x00, 0xFF, 0x01, 0x80, 0x02, 0x01, 0x01, 0x00, 0x40, 0x00, 0x52, 0xDF, 0xF8, 0x34, 0xD0,
		  0xFF, 0xF7, 0x84, 0xFF, 0x0C, 0x48, 0x0D, 0x49, 0x0D, 0x4A, 0x00, 0x23, 0x02, 0xE0, 0xD4, 0x58,
		  0xC4, 0x50, 0x04, 0x33, 0xC4, 0x18, 0x8C, 0x42, 0xF9, 0xD3, 0x0A, 0x4A, 0x0A, 0x4C, 0x00, 0x23,
		  0x01, 0xE0, 0x13, 0x60, 0x04, 0x32, 0xA2, 0x42, 0xFB, 0xD3, 0x04, 0xF0, 0x0D, 0xF8, 0xFF, 0xF7,
		  0xC9, 0xFC, 0x70, 0x47, 0x00, 0x00, 0x10, 0x24, 0x00, 0x00, 0x00, 0x24, 0x10, 0x00, 0x00, 0x24,
		  0x20, 0x4D, 0x00, 0x08, 0x10, 0x00, 0x00, 0x24, 0xC0, 0x00, 0x00, 0x24, 0xFE, 0xE7, 0x00, 0x00,
		  0x80, 0xB5, 0x82, 0xB0, 0x00, 0xAF, 0x03, 0x20, 0x00, 0xF0, 0x62, 0xF9, 0x01, 0xF0, 0x8A, 0xF9,
		  0x02, 0x46, 0x15, 0x4B, 0x9B, 0x69, 0x1B, 0x0A, 0x03, 0xF0, 0x0F, 0x03, 0x13, 0x49, 0xCB, 0x5C,
		  0x03, 0xF0, 0x1F, 0x03, 0x22, 0xFA, 0x03, 0xF3, 0x7B, 0x60, 0x0F, 0x4B, 0x9B, 0x69, 0x03, 0xF0,
		  0x0F, 0x03, 0x0E, 0x4A, 0xD3, 0x5C, 0x03, 0xF0, 0x1F, 0x03, 0x7A, 0x68, 0x22, 0xFA, 0x03, 0xF3,
		  0x0B, 0x4A, 0x13, 0x60, 0x0B, 0x4A, 0x7B, 0x68, 0x13, 0x60, 0x00, 0x20, 0x00, 0xF0, 0x14, 0xF8,
		  0x03, 0x46, 0x00, 0x2B, 0x01, 0xD0, 0x01, 0x23, 0x02, 0xE0, 0xFF, 0xF7, 0x87, 0xFE, 0x00, 0x23,
		  0x18, 0x46, 0x08, 0x37, 0xBD, 0x46, 0x80, 0xBD, 0x00, 0x44, 0x02, 0x58, 0xD8, 0x4C, 0x00, 0x08,
		  0x04, 0x00, 0x00, 0x24, 0x00, 0x00, 0x00, 0x24, 0x80, 0xB5, 0x82, 0xB0, 0x00, 0xAF, 0x78, 0x60,
		  0x15, 0x4B, 0x1B, 0x78, 0x00, 0x2B, 0x01, 0xD1, 0x01, 0x23, 0x21, 0xE0, 0x13, 0x4B, 0x1A, 0x68,
		  0x11, 0x4B, 0x1B, 0x78, 0x19, 0x46, 0x4F, 0xF4, 0x7A, 0x73, 0xB3, 0xFB, 0xF1, 0xF3, 0xB2, 0xFB,
		  0xF3, 0xF3, 0x18, 0x46, 0x00, 0xF0, 0x39, 0xF9, 0x03, 0x46, 0x00, 0x2B, 0x01, 0xD0, 0x01, 0x23,
		  0x0E, 0xE0, 0x7B, 0x68, 0x0F, 0x2B, 0x0A, 0xD8, 0x00, 0x22, 0x79, 0x68, 0x4F, 0xF0, 0xFF, 0x30,
		  0x00, 0xF0, 0x11, 0xF9, 0x06, 0x4A, 0x7B, 0x68, 0x13, 0x60, 0x00, 0x23, 0x00, 0xE0, 0x01, 0x23,
		  0x18, 0x46, 0x08, 0x37, 0xBD, 0x46, 0x80, 0xBD, 0x0C, 0x00, 0x00, 0x24, 0x00, 0x00, 0x00, 0x24,
		  0x08, 0x00, 0x00, 0x24, 0x80, 0xB4, 0x00, 0xAF, 0x06, 0x4B, 0x1B, 0x78, 0x1A, 0x46, 0x06, 0x4B,
		  0x1B, 0x68, 0x13, 0x44, 0x04, 0x4A, 0x13, 0x60, 0x00, 0xBF, 0xBD, 0x46, 0x5D, 0xF8, 0x04, 0x7B,
		  0x70, 0x47, 0x00, 0xBF, 0x0C, 0x00, 0x00, 0x24, 0xBC, 0x00, 0x00, 0x24, 0x80, 0xB4, 0x00, 0xAF,
		  0x03, 0x4B, 0x1B, 0x68, 0x18, 0x46, 0xBD, 0x46, 0x5D, 0xF8, 0x04, 0x7B, 0x70, 0x47, 0x00, 0xBF,
		  0xBC, 0x00, 0x00, 0x24, 0x80, 0xB5, 0x84, 0xB0, 0x00, 0xAF, 0x78, 0x60, 0xFF, 0xF7, 0xEE, 0xFF,
		  0xB8, 0x60, 0x7B, 0x68, 0xFB, 0x60, 0xFB, 0x68, 0xB3, 0xF1, 0xFF, 0x3F, 0x05, 0xD0, 0x0A, 0x4B,
		  0x1B, 0x78, 0x1A, 0x46, 0xFB, 0x68, 0x13, 0x44, 0xFB, 0x60, 0x00, 0xBF, 0xFF, 0xF7, 0xDE, 0xFF,
		  0x02, 0x46, 0xBB, 0x68, 0xD3, 0x1A, 0xFA, 0x68, 0x9A, 0x42, 0xF7, 0xD8, 0x00, 0xBF, 0x00, 0xBF,
		  0x10, 0x37, 0xBD, 0x46, 0x80, 0xBD, 0x00, 0xBF, 0x0C, 0x00, 0x00, 0x24, 0x80, 0xB4, 0x85, 0xB0,
		  0x00, 0xAF, 0x78, 0x60, 0x7B, 0x68, 0x03, 0xF0, 0x07, 0x03, 0xFB, 0x60, 0x0B, 0x4B, 0xDB, 0x68,
		  0xBB, 0x60, 0xBA, 0x68, 0x4F, 0xF6, 0xFF, 0x03, 0x13, 0x40, 0xBB, 0x60, 0xFB, 0x68, 0x1A, 0x02,
		  0xBB, 0x68, 0x1A, 0x43, 0x06, 0x4B, 0x13, 0x43, 0xBB, 0x60, 0x04, 0x4A, 0xBB, 0x68, 0xD3, 0x60,
		  0x00, 0xBF, 0x14, 0x37, 0xBD, 0x46, 0x5D, 0xF8, 0x04, 0x7B, 0x70, 0x47, 0x00, 0xED, 0x00, 0xE0,
		  0x00, 0x00, 0xFA, 0x05, 0x80, 0xB4, 0x00, 0xAF, 0x04, 0x4B, 0xDB, 0x68, 0x1B, 0x0A, 0x03, 0xF0,
		  0x07, 0x03, 0x18, 0x46, 0xBD, 0x46, 0x5D, 0xF8, 0x04, 0x7B, 0x70, 0x47, 0x00, 0xED, 0x00, 0xE0,
		  0x80, 0xB4, 0x83, 0xB0, 0x00, 0xAF, 0x03, 0x46, 0x39, 0x60, 0xFB, 0x80, 0xB7, 0xF9, 0x06, 0x30,
		  0x00, 0x2B, 0x0A, 0xDB, 0x3B, 0x68, 0xDA, 0xB2, 0x0C, 0x49, 0xB7, 0xF9, 0x06, 0x30, 0x12, 0x01,
		  0xD2, 0xB2, 0x0B, 0x44, 0x83, 0xF8, 0x00, 0x23, 0x0A, 0xE0, 0x3B, 0x68, 0xDA, 0xB2, 0x08, 0x49,
		  0xFB, 0x88, 0x03, 0xF0, 0x0F, 0x03, 0x04, 0x3B, 0x12, 0x01, 0xD2, 0xB2, 0x0B, 0x44, 0x1A, 0x76,
		  0x00, 0xBF, 0x0C, 0x37, 0xBD, 0x46, 0x5D, 0xF8, 0x04, 0x7B, 0x70, 0x47, 0x00, 0xE1, 0x00, 0xE0,
		  0x00, 0xED, 0x00, 0xE0, 0x80, 0xB4, 0x89, 0xB0, 0x00, 0xAF, 0xF8, 0x60, 0xB9, 0x60, 0x7A, 0x60,
		  0xFB, 0x68, 0x03, 0xF0, 0x07, 0x03, 0xFB, 0x61, 0xFB, 0x69, 0xC3, 0xF1, 0x07, 0x03, 0x04, 0x2B,
		  0x28, 0xBF, 0x04, 0x23, 0xBB, 0x61, 0xFB, 0x69, 0x04, 0x33, 0x06, 0x2B, 0x02, 0xD9, 0xFB, 0x69,
		  0x03, 0x3B, 0x00, 0xE0, 0x00, 0x23, 0x7B, 0x61, 0x4F, 0xF0, 0xFF, 0x32, 0xBB, 0x69, 0x02, 0xFA,
		  0x03, 0xF3, 0xDA, 0x43, 0xBB, 0x68, 0x1A, 0x40, 0x7B, 0x69, 0x9A, 0x40, 0x4F, 0xF0, 0xFF, 0x31,
		  0x7B, 0x69, 0x01, 0xFA, 0x03, 0xF3, 0xD9, 0x43, 0x7B, 0x68, 0x0B, 0x40, 0x13, 0x43, 0x18, 0x46,
		  0x24, 0x37, 0xBD, 0x46, 0x5D, 0xF8, 0x04, 0x7B, 0x70, 0x47, 0x00, 0x00, 0x80, 0xB5, 0x82, 0xB0,
		  0x00, 0xAF, 0x78, 0x60, 0x7B, 0x68, 0x01, 0x3B, 0xB3, 0xF1, 0x80, 0x7F, 0x01, 0xD3, 0x01, 0x23,
		  0x0F, 0xE0, 0x0A, 0x4A, 0x7B, 0x68, 0x01, 0x3B, 0x53, 0x60, 0x0F, 0x21, 0x4F, 0xF0, 0xFF, 0x30,
		  0xFF, 0xF7, 0x8E, 0xFF, 0x05, 0x4B, 0x00, 0x22, 0x9A, 0x60, 0x04, 0x4B, 0x07, 0x22, 0x1A, 0x60,
		  0x00, 0x23, 0x18, 0x46, 0x08, 0x37, 0xBD, 0x46, 0x80, 0xBD, 0x00, 0xBF, 0x10, 0xE0, 0x00, 0xE0,
		  0x80, 0xB5, 0x82, 0xB0, 0x00, 0xAF, 0x78, 0x60, 0x78, 0x68, 0xFF, 0xF7, 0x47, 0xFF, 0x00, 0xBF,
		  0x08, 0x37, 0xBD, 0x46, 0x80, 0xBD, 0x80, 0xB5, 0x86, 0xB0, 0x00, 0xAF, 0x03, 0x46, 0xB9, 0x60,
		  0x7A, 0x60, 0xFB, 0x81, 0xFF, 0xF7, 0x5E, 0xFF, 0x78, 0x61, 0x7A, 0x68, 0xB9, 0x68, 0x78, 0x69,
		  0xFF, 0xF7, 0x90, 0xFF, 0x02, 0x46, 0xB7, 0xF9, 0x0E, 0x30, 0x11, 0x46, 0x18, 0x46, 0xFF, 0xF7,
		  0x5F, 0xFF, 0x00, 0xBF, 0x18, 0x37, 0xBD, 0x46, 0x80, 0xBD, 0x80, 0xB5, 0x82, 0xB0, 0x00, 0xAF,
		  0x78, 0x60, 0x78, 0x68, 0xFF, 0xF7, 0xB2, 0xFF, 0x03, 0x46, 0x18, 0x46, 0x08, 0x37, 0xBD, 0x46,
		  0x80, 0xBD, 0x00, 0x00, 0x80, 0xB4, 0x89, 0xB0, 0x00, 0xAF, 0x78, 0x60, 0x39, 0x60, 0x00, 0x23,
		  0xFB, 0x61, 0x89, 0x4B, 0x7B, 0x61, 0x94, 0xE1, 0x3B, 0x68, 0x1A, 0x68, 0x01, 0x21, 0xFB, 0x69,
		  0x01, 0xFA, 0x03, 0xF3, 0x13, 0x40, 0x3B, 0x61, 0x3B, 0x69, 0x00, 0x2B, 0x00, 0xF0, 0x86, 0x81,
		  0x3B, 0x68, 0x5B, 0x68, 0x03, 0xF0, 0x03, 0x03, 0x01, 0x2B, 0x05, 0xD0, 0x3B, 0x68, 0x5B, 0x68,
		  0x03, 0xF0, 0x03, 0x03, 0x02, 0x2B, 0x30, 0xD1, 0x7B, 0x68, 0x9B, 0x68, 0xBB, 0x61, 0xFB, 0x69,
		  0x5B, 0x00, 0x03, 0x22, 0x02, 0xFA, 0x03, 0xF3, 0xDB, 0x43, 0xBA, 0x69, 0x13, 0x40, 0xBB, 0x61,
		  0x3B, 0x68, 0xDA, 0x68, 0xFB, 0x69, 0x5B, 0x00, 0x02, 0xFA, 0x03, 0xF3, 0xBA, 0x69, 0x13, 0x43,
		  0xBB, 0x61, 0x7B, 0x68, 0xBA, 0x69, 0x9A, 0x60, 0x7B, 0x68, 0x5B, 0x68, 0xBB, 0x61, 0x01, 0x22,
		  0xFB, 0x69, 0x02, 0xFA, 0x03, 0xF3, 0xDB, 0x43, 0xBA, 0x69, 0x13, 0x40, 0xBB, 0x61, 0x3B, 0x68,
		  0x5B, 0x68, 0x1B, 0x09, 0x03, 0xF0, 0x01, 0x02, 0xFB, 0x69, 0x02, 0xFA, 0x03, 0xF3, 0xBA, 0x69,
		  0x13, 0x43, 0xBB, 0x61, 0x7B, 0x68, 0xBA, 0x69, 0x5A, 0x60, 0x3B, 0x68, 0x5B, 0x68, 0x03, 0xF0,
		  0x03, 0x03, 0x03, 0x2B, 0x17, 0xD0, 0x7B, 0x68, 0xDB, 0x68, 0xBB, 0x61, 0xFB, 0x69, 0x5B, 0x00,
		  0x03, 0x22, 0x02, 0xFA, 0x03, 0xF3, 0xDB, 0x43, 0xBA, 0x69, 0x13, 0x40, 0xBB, 0x61, 0x3B, 0x68,
		  0x9A, 0x68, 0xFB, 0x69, 0x5B, 0x00, 0x02, 0xFA, 0x03, 0xF3, 0xBA, 0x69, 0x13, 0x43, 0xBB, 0x61,
		  0x7B, 0x68, 0xBA, 0x69, 0xDA, 0x60, 0x3B, 0x68, 0x5B, 0x68, 0x03, 0xF0, 0x03, 0x03, 0x02, 0x2B,
		  0x23, 0xD1, 0xFB, 0x69, 0xDA, 0x08, 0x7B, 0x68, 0x08, 0x32, 0x53, 0xF8, 0x22, 0x30, 0xBB, 0x61,
		  0xFB, 0x69, 0x03, 0xF0, 0x07, 0x03, 0x9B, 0x00, 0x0F, 0x22, 0x02, 0xFA, 0x03, 0xF3, 0xDB, 0x43,
		  0xBA, 0x69, 0x13, 0x40, 0xBB, 0x61, 0x3B, 0x68, 0x1A, 0x69, 0xFB, 0x69, 0x03, 0xF0, 0x07, 0x03,
		  0x9B, 0x00, 0x02, 0xFA, 0x03, 0xF3, 0xBA, 0x69, 0x13, 0x43, 0xBB, 0x61, 0xFB, 0x69, 0xDA, 0x08,
		  0x7B, 0x68, 0x08, 0x32, 0xB9, 0x69, 0x43, 0xF8, 0x22, 0x10, 0x7B, 0x68, 0x1B, 0x68, 0xBB, 0x61,
		  0xFB, 0x69, 0x5B, 0x00, 0x03, 0x22, 0x02, 0xFA, 0x03, 0xF3, 0xDB, 0x43, 0xBA, 0x69, 0x13, 0x40,
		  0xBB, 0x61, 0x3B, 0x68, 0x5B, 0x68, 0x03, 0xF0, 0x03, 0x02, 0xFB, 0x69, 0x5B, 0x00, 0x02, 0xFA,
		  0x03, 0xF3, 0xBA, 0x69, 0x13, 0x43, 0xBB, 0x61, 0x7B, 0x68, 0xBA, 0x69, 0x1A, 0x60, 0x3B, 0x68,
		  0x5B, 0x68, 0x03, 0xF4, 0x40, 0x33, 0x00, 0x2B, 0x00, 0xF0, 0xE0, 0x80, 0x2F, 0x4B, 0xD3, 0xF8,
		  0x54, 0x31, 0x2E, 0x4A, 0x43, 0xF0, 0x02, 0x03, 0xC2, 0xF8, 0x54, 0x31, 0x2B, 0x4B, 0xD3, 0xF8,
		  0x54, 0x31, 0x03, 0xF0, 0x02, 0x03, 0xFB, 0x60, 0xFB, 0x68, 0x29, 0x4A, 0xFB, 0x69, 0x9B, 0x08,
		  0x02, 0x33, 0x52, 0xF8, 0x23, 0x30, 0xBB, 0x61, 0xFB, 0x69, 0x03, 0xF0, 0x03, 0x03, 0x9B, 0x00,
		  0x0F, 0x22, 0x02, 0xFA, 0x03, 0xF3, 0xDB, 0x43, 0xBA, 0x69, 0x13, 0x40, 0xBB, 0x61, 0x7B, 0x68,
		  0x20, 0x4A, 0x93, 0x42, 0x52, 0xD0, 0x7B, 0x68, 0x1F, 0x4A, 0x93, 0x42, 0x31, 0xD0, 0x7B, 0x68,
		  0x1E, 0x4A, 0x93, 0x42, 0x2B, 0xD0, 0x7B, 0x68, 0x1D, 0x4A, 0x93, 0x42, 0x25, 0xD0, 0x7B, 0x68,
		  0x1C, 0x4A, 0x93, 0x42, 0x1F, 0xD0, 0x7B, 0x68, 0x1B, 0x4A, 0x93, 0x42, 0x19, 0xD0, 0x7B, 0x68,
		  0x1A, 0x4A, 0x93, 0x42, 0x13, 0xD0, 0x7B, 0x68, 0x19, 0x4A, 0x93, 0x42, 0x0D, 0xD0, 0x7B, 0x68,
		  0x18, 0x4A, 0x93, 0x42, 0x07, 0xD0, 0x7B, 0x68, 0x17, 0x4A, 0x93, 0x42, 0x01, 0xD1, 0x09, 0x23,
		  0x2D, 0xE0, 0x0A, 0x23, 0x2B, 0xE0, 0x08, 0x23, 0x29, 0xE0, 0x07, 0x23, 0x27, 0xE0, 0x06, 0x23,
		  0x25, 0xE0, 0x05, 0x23, 0x23, 0xE0, 0x04, 0x23, 0x21, 0xE0, 0x03, 0x23, 0x1F, 0xE0, 0x02, 0x23,
		  0x1D, 0xE0, 0x01, 0x23, 0x1B, 0xE0, 0x00, 0xBF, 0x80, 0x00, 0x00, 0x58, 0x00, 0x44, 0x02, 0x58,
		  0x00, 0x04, 0x00, 0x58, 0x00, 0x00, 0x02, 0x58, 0x00, 0x04, 0x02, 0x58, 0x00, 0x08, 0x02, 0x58,
		  0x00, 0x0C, 0x02, 0x58, 0x00, 0x10, 0x02, 0x58, 0x00, 0x14, 0x02, 0x58, 0x00, 0x18, 0x02, 0x58,
		  0x00, 0x1C, 0x02, 0x58, 0x00, 0x20, 0x02, 0x58, 0x00, 0x24, 0x02, 0x58, 0x00, 0x23, 0xFA, 0x69,
		  0x02, 0xF0, 0x03, 0x02, 0x92, 0x00, 0x93, 0x40, 0xBA, 0x69, 0x13, 0x43, 0xBB, 0x61, 0x38, 0x49,
		  0xFB, 0x69, 0x9B, 0x08, 0x02, 0x33, 0xBA, 0x69, 0x41, 0xF8, 0x23, 0x20, 0x4F, 0xF0, 0xB0, 0x43,
		  0x1B, 0x68, 0xBB, 0x61, 0x3B, 0x69, 0xDB, 0x43, 0xBA, 0x69, 0x13, 0x40, 0xBB, 0x61, 0x3B, 0x68,
		  0x5B, 0x68, 0x03, 0xF4, 0x80, 0x13, 0x00, 0x2B, 0x03, 0xD0, 0xBA, 0x69, 0x3B, 0x69, 0x13, 0x43,
		  0xBB, 0x61, 0x4F, 0xF0, 0xB0, 0x42, 0xBB, 0x69, 0x13, 0x60, 0x4F, 0xF0, 0xB0, 0x43, 0x5B, 0x68,
		  0xBB, 0x61, 0x3B, 0x69, 0xDB, 0x43, 0xBA, 0x69, 0x13, 0x40, 0xBB, 0x61, 0x3B, 0x68, 0x5B, 0x68,
		  0x03, 0xF4, 0x00, 0x13, 0x00, 0x2B, 0x03, 0xD0, 0xBA, 0x69, 0x3B, 0x69, 0x13, 0x43, 0xBB, 0x61,
		  0x4F, 0xF0, 0xB0, 0x42, 0xBB, 0x69, 0x53, 0x60, 0x7B, 0x69, 0x5B, 0x68, 0xBB, 0x61, 0x3B, 0x69,
		  0xDB, 0x43, 0xBA, 0x69, 0x13, 0x40, 0xBB, 0x61, 0x3B, 0x68, 0x5B, 0x68, 0x03, 0xF4, 0x00, 0x33,
		  0x00, 0x2B, 0x03, 0xD0, 0xBA, 0x69, 0x3B, 0x69, 0x13, 0x43, 0xBB, 0x61, 0x7B, 0x69, 0xBA, 0x69,
		  0x5A, 0x60, 0x7B, 0x69, 0x1B, 0x68, 0xBB, 0x61, 0x3B, 0x69, 0xDB, 0x43, 0xBA, 0x69, 0x13, 0x40,
		  0xBB, 0x61, 0x3B, 0x68, 0x5B, 0x68, 0x03, 0xF4, 0x80, 0x33, 0x00, 0x2B, 0x03, 0xD0, 0xBA, 0x69,
		  0x3B, 0x69, 0x13, 0x43, 0xBB, 0x61, 0x7B, 0x69, 0xBA, 0x69, 0x1A, 0x60, 0xFB, 0x69, 0x01, 0x33,
		  0xFB, 0x61, 0x3B, 0x68, 0x1A, 0x68, 0xFB, 0x69, 0x22, 0xFA, 0x03, 0xF3, 0x00, 0x2B, 0x7F, 0xF4,
		  0x63, 0xAE, 0x00, 0xBF, 0x00, 0xBF, 0x24, 0x37, 0xBD, 0x46, 0x5D, 0xF8, 0x04, 0x7B, 0x70, 0x47,
		  0x00, 0x04, 0x00, 0x58, 0x80, 0xB4, 0x83, 0xB0, 0x00, 0xAF, 0x78, 0x60, 0x0B, 0x46, 0x7B, 0x80,
		  0x13, 0x46, 0x7B, 0x70, 0x7B, 0x78, 0x00, 0x2B, 0x03, 0xD0, 0x7A, 0x88, 0x7B, 0x68, 0x9A, 0x61,
		  0x03, 0xE0, 0x7B, 0x88, 0x1A, 0x04, 0x7B, 0x68, 0x9A, 0x61, 0x00, 0xBF, 0x0C, 0x37, 0xBD, 0x46,
		  0x5D, 0xF8, 0x04, 0x7B, 0x70, 0x47, 0x80, 0xB4, 0x85, 0xB0, 0x00, 0xAF, 0x78, 0x60, 0x0B, 0x46,
		  0x7B, 0x80, 0x7B, 0x68, 0x5B, 0x69, 0xFB, 0x60, 0x7A, 0x88, 0xFB, 0x68, 0x13, 0x40, 0x1A, 0x04,
		  0xFB, 0x68, 0xD9, 0x43, 0x7B, 0x88, 0x0B, 0x40, 0x1A, 0x43, 0x7B, 0x68, 0x9A, 0x61, 0x00, 0xBF,
		  0x14, 0x37, 0xBD, 0x46, 0x5D, 0xF8, 0x04, 0x7B, 0x70, 0x47, 0x00, 0x00, 0x80, 0xB5, 0x84, 0xB0,
		  0x00, 0xAF, 0x78, 0x60, 0x29, 0x4B, 0xDB, 0x68, 0x03, 0xF0, 0x07, 0x03, 0x06, 0x2B, 0x0A, 0xD0,
		  0x26, 0x4B, 0xDB, 0x68, 0x03, 0xF0, 0x3F, 0x03, 0x7A, 0x68, 0x9A, 0x42, 0x01, 0xD0, 0x01, 0x23,
		  0x40, 0xE0, 0x00, 0x23, 0x3E, 0xE0, 0x21, 0x4B, 0xDB, 0x68, 0x23, 0xF0, 0x3F, 0x02, 0x1F, 0x49,
		  0x7B, 0x68, 0x13, 0x43, 0xCB, 0x60, 0xFF, 0xF7, 0xE9, 0xFC, 0xF8, 0x60, 0x09, 0xE0, 0xFF, 0xF7,
		  0xE5, 0xFC, 0x02, 0x46, 0xFB, 0x68, 0xD3, 0x1A, 0xB3, 0xF5, 0x7A, 0x7F, 0x01, 0xD9, 0x01, 0x23,
		  0x28, 0xE0, 0x16, 0x4B, 0x5B, 0x68, 0x03, 0xF4, 0x00, 0x53, 0xB3, 0xF5, 0x00, 0x5F, 0xEE, 0xD1,
		  0x7B, 0x68, 0x1E, 0x2B, 0x08, 0xD0, 0x7B, 0x68, 0x2E, 0x2B, 0x05, 0xD0, 0x7B, 0x68, 0x1D, 0x2B,
		  0x02, 0xD0, 0x7B, 0x68, 0x2D, 0x2B, 0x14, 0xD1, 0xFF, 0xF7, 0xC8, 0xFC, 0xF8, 0x60, 0x09, 0xE0,
		  0xFF, 0xF7, 0xC4, 0xFC, 0x02, 0x46, 0xFB, 0x68, 0xD3, 0x1A, 0xB3, 0xF5, 0x7A, 0x7F, 0x01, 0xD9,
		  0x01, 0x23, 0x07, 0xE0, 0x05, 0x4B, 0xDB, 0x68, 0x03, 0xF4, 0x80, 0x33, 0xB3, 0xF5, 0x80, 0x3F,
		  0xEE, 0xD1, 0x00, 0x23, 0x18, 0x46, 0x10, 0x37, 0xBD, 0x46, 0x80, 0xBD, 0x00, 0x48, 0x02, 0x58,
		  0x80, 0xB5, 0x8C, 0xB0, 0x00, 0xAF, 0x78, 0x60, 0x7B, 0x68, 0x00, 0x2B, 0x01, 0xD1, 0x01, 0x23,
		  0xF3, 0xE3, 0x7B, 0x68, 0x1B, 0x68, 0x03, 0xF0, 0x01, 0x03, 0x00, 0x2B, 0x00, 0xF0, 0xB3, 0x80,
		  0x9E, 0x4B, 0x1B, 0x69, 0x03, 0xF0, 0x38, 0x03, 0xFB, 0x62, 0x9C, 0x4B, 0x9B, 0x6A, 0xBB, 0x62,
		  0xFB, 0x6A, 0x10, 0x2B, 0x07, 0xD0, 0xFB, 0x6A, 0x18, 0x2B, 0x12, 0xD1, 0xBB, 0x6A, 0x03, 0xF0,
		  0x03, 0x03, 0x02, 0x2B, 0x0D, 0xD1, 0x95, 0x4B, 0x1B, 0x68, 0x03, 0xF4, 0x00, 0x33, 0x00, 0x2B,
		  0x00, 0xF0, 0x98, 0x80, 0x7B, 0x68, 0x5B, 0x68, 0x00, 0x2B, 0x40, 0xF0, 0x93, 0x80, 0x01, 0x23,
		  0xCB, 0xE3, 0x7B, 0x68, 0x5B, 0x68, 0xB3, 0xF5, 0x80, 0x3F, 0x06, 0xD1, 0x8B, 0x4B, 0x1B, 0x68,
		  0x8A, 0x4A, 0x43, 0xF4, 0x80, 0x33, 0x13, 0x60, 0x58, 0xE0, 0x7B, 0x68, 0x5B, 0x68, 0x00, 0x2B,
		  0x12, 0xD1, 0x86, 0x4B, 0x1B, 0x68, 0x85, 0x4A, 0x23, 0xF4, 0x80, 0x33, 0x13, 0x60, 0x83, 0x4B,
		  0x1B, 0x68, 0x82, 0x4A, 0x23, 0xF4, 0x80, 0x13, 0x13, 0x60, 0x80, 0x4B, 0x1B, 0x68, 0x7F, 0x4A,
		  0x23, 0xF4, 0x80, 0x23, 0x13, 0x60, 0x41, 0xE0, 0x7B, 0x68, 0x5B, 0x68, 0xB3, 0xF5, 0xA0, 0x2F,
		  0x12, 0xD1, 0x7A, 0x4B, 0x1B, 0x68, 0x79, 0x4A, 0x43, 0xF4, 0x80, 0x23, 0x13, 0x60, 0x77, 0x4B,
		  0x1B, 0x68, 0x76, 0x4A, 0x23, 0xF4, 0x80, 0x13, 0x13, 0x60, 0x74, 0x4B, 0x1B, 0x68, 0x73, 0x4A,
		  0x43, 0xF4, 0x80, 0x33, 0x13, 0x60, 0x29, 0xE0, 0x7B, 0x68, 0x5B, 0x68, 0xB3, 0xF5, 0xA8, 0x1F,
		  0x12, 0xD1, 0x6E, 0x4B, 0x1B, 0x68, 0x6D, 0x4A, 0x43, 0xF4, 0x80, 0x23, 0x13, 0x60, 0x6B, 0x4B,
		  0x1B, 0x68, 0x6A, 0x4A, 0x43, 0xF4, 0x80, 0x13, 0x13, 0x60, 0x68, 0x4B, 0x1B, 0x68, 0x67, 0x4A,
		  0x43, 0xF4, 0x80, 0x33, 0x13, 0x60, 0x11, 0xE0, 0x64, 0x4B, 0x1B, 0x68, 0x63, 0x4A, 0x23, 0xF4,
		  0x80, 0x33, 0x13, 0x60, 0x61, 0x4B, 0x1B, 0x68, 0x60, 0x4A, 0x23, 0xF4, 0x80, 0x23, 0x13, 0x60,
		  0x5E, 0x4B, 0x1B, 0x68, 0x5D, 0x4A, 0x23, 0xF4, 0x80, 0x13, 0x13, 0x60, 0x7B, 0x68, 0x5B, 0x68,
		  0x00, 0x2B, 0x13, 0xD0, 0xFF, 0xF7, 0x12, 0xFC, 0x78, 0x62, 0x08, 0xE0, 0xFF, 0xF7, 0x0E, 0xFC,
		  0x02, 0x46, 0x7B, 0x6A, 0xD3, 0x1A, 0x64, 0x2B, 0x01, 0xD9, 0x03, 0x23, 0x55, 0xE3, 0x53, 0x4B,
		  0x1B, 0x68, 0x03, 0xF4, 0x00, 0x33, 0x00, 0x2B, 0xF0, 0xD0, 0x14, 0xE0, 0xFF, 0xF7, 0xFE, 0xFB,
		  0x78, 0x62, 0x08, 0xE0, 0xFF, 0xF7, 0xFA, 0xFB, 0x02, 0x46, 0x7B, 0x6A, 0xD3, 0x1A, 0x64, 0x2B,
		  0x01, 0xD9, 0x03, 0x23, 0x41, 0xE3, 0x49, 0x4B, 0x1B, 0x68, 0x03, 0xF4, 0x00, 0x33, 0x00, 0x2B,
		  0xF0, 0xD1, 0x00, 0xE0, 0x00, 0xBF, 0x7B, 0x68, 0x1B, 0x68, 0x03, 0xF0, 0x02, 0x03, 0x00, 0x2B,
		  0x00, 0xF0, 0x8C, 0x80, 0x41, 0x4B, 0x1B, 0x69, 0x03, 0xF0, 0x38, 0x03, 0x3B, 0x62, 0x3F, 0x4B,
		  0x9B, 0x6A, 0xFB, 0x61, 0x3B, 0x6A, 0x00, 0x2B, 0x07, 0xD0, 0x3B, 0x6A, 0x18, 0x2B, 0x37, 0xD1,
		  0xFB, 0x69, 0x03, 0xF0, 0x03, 0x03, 0x00, 0x2B, 0x32, 0xD1, 0x38, 0x4B, 0x1B, 0x68, 0x03, 0xF0,
		  0x04, 0x03, 0x00, 0x2B, 0x05, 0xD0, 0x7B, 0x68, 0xDB, 0x68, 0x00, 0x2B, 0x01, 0xD1, 0x01, 0x23,
		  0x13, 0xE3, 0x32, 0x4B, 0x1B, 0x68, 0x23, 0xF0, 0x19, 0x02, 0x7B, 0x68, 0xDB, 0x68, 0x2F, 0x49,
		  0x13, 0x43, 0x0B, 0x60, 0xFF, 0xF7, 0xBA, 0xFB, 0x78, 0x62, 0x08, 0xE0, 0xFF, 0xF7, 0xB6, 0xFB,
		  0x02, 0x46, 0x7B, 0x6A, 0xD3, 0x1A, 0x02, 0x2B, 0x01, 0xD9, 0x03, 0x23, 0xFD, 0xE2, 0x27, 0x4B,
		  0x1B, 0x68, 0x03, 0xF0, 0x04, 0x03, 0x00, 0x2B, 0xF0, 0xD0, 0x24, 0x4B, 0x5B, 0x68, 0x23, 0xF0,
		  0xFE, 0x42, 0x7B, 0x68, 0x1B, 0x69, 0x1B, 0x06, 0x20, 0x49, 0x13, 0x43, 0x4B, 0x60, 0x45, 0xE0,
		  0x7B, 0x68, 0xDB, 0x68, 0x00, 0x2B, 0x26, 0xD0, 0x1C, 0x4B, 0x1B, 0x68, 0x23, 0xF0, 0x19, 0x02,
		  0x7B, 0x68, 0xDB, 0x68, 0x19, 0x49, 0x13, 0x43, 0x0B, 0x60, 0xFF, 0xF7, 0x8F, 0xFB, 0x78, 0x62,
		  0x08, 0xE0, 0xFF, 0xF7, 0x8B, 0xFB, 0x02, 0x46, 0x7B, 0x6A, 0xD3, 0x1A, 0x02, 0x2B, 0x01, 0xD9,
		  0x03, 0x23, 0xD2, 0xE2, 0x11, 0x4B, 0x1B, 0x68, 0x03, 0xF0, 0x04, 0x03, 0x00, 0x2B, 0xF0, 0xD0,
		  0x0E, 0x4B, 0x5B, 0x68, 0x23, 0xF0, 0xFE, 0x42, 0x7B, 0x68, 0x1B, 0x69, 0x1B, 0x06, 0x0B, 0x49,
		  0x13, 0x43, 0x4B, 0x60, 0x1A, 0xE0, 0x09, 0x4B, 0x1B, 0x68, 0x08, 0x4A, 0x23, 0xF0, 0x01, 0x03,
		  0x13, 0x60, 0xFF, 0xF7, 0x6B, 0xFB, 0x78, 0x62, 0x0A, 0xE0, 0xFF, 0xF7, 0x67, 0xFB, 0x02, 0x46,
		  0x7B, 0x6A, 0xD3, 0x1A, 0x02, 0x2B, 0x03, 0xD9, 0x03, 0x23, 0xAE, 0xE2, 0x00, 0x44, 0x02, 0x58,
		  0x99, 0x4B, 0x1B, 0x68, 0x03, 0xF0, 0x04, 0x03, 0x00, 0x2B, 0xEE, 0xD1, 0x7B, 0x68, 0x1B, 0x68,
		  0x03, 0xF0, 0x10, 0x03, 0x00, 0x2B, 0x6A, 0xD0, 0x93, 0x4B, 0x1B, 0x69, 0x03, 0xF0, 0x38, 0x03,
		  0xBB, 0x61, 0x91, 0x4B, 0x9B, 0x6A, 0x7B, 0x61, 0xBB, 0x69, 0x08, 0x2B, 0x07, 0xD0, 0xBB, 0x69,
		  0x18, 0x2B, 0x1B, 0xD1, 0x7B, 0x69, 0x03, 0xF0, 0x03, 0x03, 0x01, 0x2B, 0x16, 0xD1, 0x8A, 0x4B,
		  0x1B, 0x68, 0x03, 0xF4, 0x80, 0x73, 0x00, 0x2B, 0x05, 0xD0, 0x7B, 0x68, 0xDB, 0x69, 0x80, 0x2B,
		  0x01, 0xD0, 0x01, 0x23, 0x81, 0xE2, 0x84, 0x4B, 0xDB, 0x68, 0x23, 0xF0, 0x7C, 0x52, 0x7B, 0x68,
		  0x1B, 0x6A, 0x1B, 0x06, 0x80, 0x49, 0x13, 0x43, 0xCB, 0x60, 0x40, 0xE0, 0x7B, 0x68, 0xDB, 0x69,
		  0x00, 0x2B, 0x23, 0xD0, 0x7C, 0x4B, 0x1B, 0x68, 0x7B, 0x4A, 0x43, 0xF0, 0x80, 0x03, 0x13, 0x60,
		  0xFF, 0xF7, 0x1C, 0xFB, 0x78, 0x62, 0x08, 0xE0, 0xFF, 0xF7, 0x18, 0xFB, 0x02, 0x46, 0x7B, 0x6A,
		  0xD3, 0x1A, 0x02, 0x2B, 0x01, 0xD9, 0x03, 0x23, 0x5F, 0xE2, 0x73, 0x4B, 0x1B, 0x68, 0x03, 0xF4,
		  0x80, 0x73, 0x00, 0x2B, 0xF0, 0xD0, 0x70, 0x4B, 0xDB, 0x68, 0x23, 0xF0, 0x7C, 0x52, 0x7B, 0x68,
		  0x1B, 0x6A, 0x1B, 0x06, 0x6C, 0x49, 0x13, 0x43, 0xCB, 0x60, 0x18, 0xE0, 0x6A, 0x4B, 0x1B, 0x68,
		  0x69, 0x4A, 0x23, 0xF0, 0x80, 0x03, 0x13, 0x60, 0xFF, 0xF7, 0xF8, 0xFA, 0x78, 0x62, 0x08, 0xE0,
		  0xFF, 0xF7, 0xF4, 0xFA, 0x02, 0x46, 0x7B, 0x6A, 0xD3, 0x1A, 0x02, 0x2B, 0x01, 0xD9, 0x03, 0x23,
		  0x3B, 0xE2, 0x61, 0x4B, 0x1B, 0x68, 0x03, 0xF4, 0x80, 0x73, 0x00, 0x2B, 0xF0, 0xD1, 0x7B, 0x68,
		  0x1B, 0x68, 0x03, 0xF0, 0x08, 0x03, 0x00, 0x2B, 0x36, 0xD0, 0x7B, 0x68, 0x5B, 0x69, 0x00, 0x2B,
		  0x19, 0xD0, 0x59, 0x4B, 0x5B, 0x6F, 0x58, 0x4A, 0x43, 0xF0, 0x01, 0x03, 0x53, 0x67, 0xFF, 0xF7,
		  0xD5, 0xFA, 0x78, 0x62, 0x08, 0xE0, 0xFF, 0xF7, 0xD1, 0xFA, 0x02, 0x46, 0x7B, 0x6A, 0xD3, 0x1A,
		  0x02, 0x2B, 0x01, 0xD9, 0x03, 0x23, 0x18, 0xE2, 0x4F, 0x4B, 0x5B, 0x6F, 0x03, 0xF0, 0x02, 0x03,
		  0x00, 0x2B, 0xF0, 0xD0, 0x18, 0xE0, 0x4C, 0x4B, 0x5B, 0x6F, 0x4B, 0x4A, 0x23, 0xF0, 0x01, 0x03,
		  0x53, 0x67, 0xFF, 0xF7, 0xBB, 0xFA, 0x78, 0x62, 0x08, 0xE0, 0xFF, 0xF7, 0xB7, 0xFA, 0x02, 0x46,
		  0x7B, 0x6A, 0xD3, 0x1A, 0x02, 0x2B, 0x01, 0xD9, 0x03, 0x23, 0xFE, 0xE1, 0x42, 0x4B, 0x5B, 0x6F,
		  0x03, 0xF0, 0x02, 0x03, 0x00, 0x2B, 0xF0, 0xD1, 0x7B, 0x68, 0x1B, 0x68, 0x03, 0xF0, 0x20, 0x03,
		  0x00, 0x2B, 0x36, 0xD0, 0x7B, 0x68, 0x9B, 0x69, 0x00, 0x2B, 0x19, 0xD0, 0x3A, 0x4B, 0x1B, 0x68,
		  0x39, 0x4A, 0x43, 0xF4, 0x80, 0x53, 0x13, 0x60, 0xFF, 0xF7, 0x98, 0xFA, 0x78, 0x62, 0x08, 0xE0,
		  0xFF, 0xF7, 0x94, 0xFA, 0x02, 0x46, 0x7B, 0x6A, 0xD3, 0x1A, 0x02, 0x2B, 0x01, 0xD9, 0x03, 0x23,
		  0xDB, 0xE1, 0x31, 0x4B, 0x1B, 0x68, 0x03, 0xF4, 0x00, 0x53, 0x00, 0x2B, 0xF0, 0xD0, 0x18, 0xE0,
		  0x2D, 0x4B, 0x1B, 0x68, 0x2C, 0x4A, 0x23, 0xF4, 0x80, 0x53, 0x13, 0x60, 0xFF, 0xF7, 0x7E, 0xFA,
		  0x78, 0x62, 0x08, 0xE0, 0xFF, 0xF7, 0x7A, 0xFA, 0x02, 0x46, 0x7B, 0x6A, 0xD3, 0x1A, 0x02, 0x2B,
		  0x01, 0xD9, 0x03, 0x23, 0xC1, 0xE1, 0x24, 0x4B, 0x1B, 0x68, 0x03, 0xF4, 0x00, 0x53, 0x00, 0x2B,
		  0xF0, 0xD1, 0x7B, 0x68, 0x1B, 0x68, 0x03, 0xF0, 0x04, 0x03, 0x00, 0x2B, 0x00, 0xF0, 0xAF, 0x80,
		  0x1E, 0x4B, 0x1B, 0x68, 0x1D, 0x4A, 0x43, 0xF4, 0x80, 0x73, 0x13, 0x60, 0xFF, 0xF7, 0x5E, 0xFA,
		  0x78, 0x62, 0x08, 0xE0, 0xFF, 0xF7, 0x5A, 0xFA, 0x02, 0x46, 0x7B, 0x6A, 0xD3, 0x1A, 0x64, 0x2B,
		  0x01, 0xD9, 0x03, 0x23, 0xA1, 0xE1, 0x15, 0x4B, 0x1B, 0x68, 0x03, 0xF4, 0x80, 0x73, 0x00, 0x2B,
		  0xF0, 0xD0, 0x7B, 0x68, 0x9B, 0x68, 0x01, 0x2B, 0x06, 0xD1, 0x0F, 0x4B, 0x1B, 0x6F, 0x0E, 0x4A,
		  0x43, 0xF0, 0x01, 0x03, 0x13, 0x67, 0x5B, 0xE0, 0x7B, 0x68, 0x9B, 0x68, 0x00, 0x2B, 0x17, 0xD1,
		  0x09, 0x4B, 0x1B, 0x6F, 0x08, 0x4A, 0x23, 0xF0, 0x01, 0x03, 0x13, 0x67, 0x06, 0x4B, 0x1B, 0x6F,
		  0x05, 0x4A, 0x23, 0xF0, 0x80, 0x03, 0x13, 0x67, 0x03, 0x4B, 0x1B, 0x6F, 0x02, 0x4A, 0x23, 0xF0,
		  0x04, 0x03, 0x13, 0x67, 0x44, 0xE0, 0x00, 0xBF, 0x00, 0x44, 0x02, 0x58, 0x00, 0x48, 0x02, 0x58,
		  0x7B, 0x68, 0x9B, 0x68, 0x05, 0x2B, 0x12, 0xD1, 0x95, 0x4B, 0x1B, 0x6F, 0x94, 0x4A, 0x43, 0xF0,
		  0x04, 0x03, 0x13, 0x67, 0x92, 0x4B, 0x1B, 0x6F, 0x91, 0x4A, 0x23, 0xF0, 0x80, 0x03, 0x13, 0x67,
		  0x8F, 0x4B, 0x1B, 0x6F, 0x8E, 0x4A, 0x43, 0xF0, 0x01, 0x03, 0x13, 0x67, 0x28, 0xE0, 0x7B, 0x68,
		  0x9B, 0x68, 0x85, 0x2B, 0x12, 0xD1, 0x8A, 0x4B, 0x1B, 0x6F, 0x89, 0x4A, 0x43, 0xF0, 0x04, 0x03,
		  0x13, 0x67, 0x87, 0x4B, 0x1B, 0x6F, 0x86, 0x4A, 0x43, 0xF0, 0x80, 0x03, 0x13, 0x67, 0x84, 0x4B,
		  0x1B, 0x6F, 0x83, 0x4A, 0x43, 0xF0, 0x01, 0x03, 0x13, 0x67, 0x11, 0xE0, 0x80, 0x4B, 0x1B, 0x6F,
		  0x7F, 0x4A, 0x23, 0xF0, 0x01, 0x03, 0x13, 0x67, 0x7D, 0x4B, 0x1B, 0x6F, 0x7C, 0x4A, 0x23, 0xF0,
		  0x04, 0x03, 0x13, 0x67, 0x7A, 0x4B, 0x1B, 0x6F, 0x79, 0x4A, 0x23, 0xF0, 0x80, 0x03, 0x13, 0x67,
		  0x7B, 0x68, 0x9B, 0x68, 0x00, 0x2B, 0x15, 0xD0, 0xFF, 0xF7, 0xE0, 0xF9, 0x78, 0x62, 0x0A, 0xE0,
		  0xFF, 0xF7, 0xDC, 0xF9, 0x02, 0x46, 0x7B, 0x6A, 0xD3, 0x1A, 0x41, 0xF2, 0x88, 0x32, 0x93, 0x42,
		  0x01, 0xD9, 0x03, 0x23, 0x21, 0xE1, 0x6E, 0x4B, 0x1B, 0x6F, 0x03, 0xF0, 0x02, 0x03, 0x00, 0x2B,
		  0xEE, 0xD0, 0x14, 0xE0, 0xFF, 0xF7, 0xCA, 0xF9, 0x78, 0x62, 0x0A, 0xE0, 0xFF, 0xF7, 0xC6, 0xF9,
		  0x02, 0x46, 0x7B, 0x6A, 0xD3, 0x1A, 0x41, 0xF2, 0x88, 0x32, 0x93, 0x42, 0x01, 0xD9, 0x03, 0x23,
		  0x0B, 0xE1, 0x63, 0x4B, 0x1B, 0x6F, 0x03, 0xF0, 0x02, 0x03, 0x00, 0x2B, 0xEE, 0xD1, 0x7B, 0x68,
		  0x5B, 0x6A, 0x00, 0x2B, 0x00, 0xF0, 0x00, 0x81, 0x5D, 0x4B, 0x1B, 0x69, 0x03, 0xF0, 0x38, 0x03,
		  0x18, 0x2B, 0x00, 0xF0, 0xBB, 0x80, 0x7B, 0x68, 0x5B, 0x6A, 0x02, 0x2B, 0x40, 0xF0, 0x95, 0x80,
		  0x57, 0x4B, 0x1B, 0x68, 0x56, 0x4A, 0x23, 0xF0, 0x80, 0x73, 0x13, 0x60, 0xFF, 0xF7, 0x9E, 0xF9,
		  0x78, 0x62, 0x08, 0xE0, 0xFF, 0xF7, 0x9A, 0xF9, 0x02, 0x46, 0x7B, 0x6A, 0xD3, 0x1A, 0x02, 0x2B,
		  0x01, 0xD9, 0x03, 0x23, 0xE1, 0xE0, 0x4E, 0x4B, 0x1B, 0x68, 0x03, 0xF0, 0x00, 0x73, 0x00, 0x2B,
		  0xF0, 0xD1, 0x4B, 0x4B, 0x9A, 0x6A, 0x4B, 0x4B, 0x13, 0x40, 0x7A, 0x68, 0x91, 0x6A, 0x7A, 0x68,
		  0xD2, 0x6A, 0x12, 0x01, 0x0A, 0x43, 0x46, 0x49, 0x13, 0x43, 0x8B, 0x62, 0x7B, 0x68, 0x1B, 0x6B,
		  0x01, 0x3B, 0xC3, 0xF3, 0x08, 0x02, 0x7B, 0x68, 0x5B, 0x6B, 0x01, 0x3B, 0x5B, 0x02, 0x9B, 0xB2,
		  0x1A, 0x43, 0x7B, 0x68, 0x9B, 0x6B, 0x01, 0x3B, 0x1B, 0x04, 0x03, 0xF4, 0xFE, 0x03, 0x1A, 0x43,
		  0x7B, 0x68, 0xDB, 0x6B, 0x01, 0x3B, 0x1B, 0x06, 0x03, 0xF0, 0xFE, 0x43, 0x38, 0x49, 0x13, 0x43,
		  0x0B, 0x63, 0x37, 0x4B, 0xDB, 0x6A, 0x36, 0x4A, 0x23, 0xF0, 0x01, 0x03, 0xD3, 0x62, 0x34, 0x4B,
		  0x5A, 0x6B, 0x35, 0x4B, 0x13, 0x40, 0x7A, 0x68, 0x92, 0x6C, 0xD2, 0x00, 0x30, 0x49, 0x13, 0x43,
		  0x4B, 0x63, 0x2F, 0x4B, 0xDB, 0x6A, 0x23, 0xF0, 0x0C, 0x02, 0x7B, 0x68, 0x1B, 0x6C, 0x2C, 0x49,
		  0x13, 0x43, 0xCB, 0x62, 0x2A, 0x4B, 0xDB, 0x6A, 0x23, 0xF0, 0x02, 0x02, 0x7B, 0x68, 0x5B, 0x6C,
		  0x27, 0x49, 0x13, 0x43, 0xCB, 0x62, 0x26, 0x4B, 0xDB, 0x6A, 0x25, 0x4A, 0x43, 0xF4, 0x80, 0x33,
		  0xD3, 0x62, 0x23, 0x4B, 0xDB, 0x6A, 0x22, 0x4A, 0x43, 0xF4, 0x00, 0x33, 0xD3, 0x62, 0x20, 0x4B,
		  0xDB, 0x6A, 0x1F, 0x4A, 0x43, 0xF4, 0x80, 0x23, 0xD3, 0x62, 0x1D, 0x4B, 0xDB, 0x6A, 0x1C, 0x4A,
		  0x43, 0xF0, 0x01, 0x03, 0xD3, 0x62, 0x1A, 0x4B, 0x1B, 0x68, 0x19, 0x4A, 0x43, 0xF0, 0x80, 0x73,
		  0x13, 0x60, 0xFF, 0xF7, 0x23, 0xF9, 0x78, 0x62, 0x08, 0xE0, 0xFF, 0xF7, 0x1F, 0xF9, 0x02, 0x46,
		  0x7B, 0x6A, 0xD3, 0x1A, 0x02, 0x2B, 0x01, 0xD9, 0x03, 0x23, 0x66, 0xE0, 0x10, 0x4B, 0x1B, 0x68,
		  0x03, 0xF0, 0x00, 0x73, 0x00, 0x2B, 0xF0, 0xD0, 0x5E, 0xE0, 0x0D, 0x4B, 0x1B, 0x68, 0x0C, 0x4A,
		  0x23, 0xF0, 0x80, 0x73, 0x13, 0x60, 0xFF, 0xF7, 0x09, 0xF9, 0x78, 0x62, 0x08, 0xE0, 0xFF, 0xF7,
		  0x05, 0xF9, 0x02, 0x46, 0x7B, 0x6A, 0xD3, 0x1A, 0x02, 0x2B, 0x01, 0xD9, 0x03, 0x23, 0x4C, 0xE0,
		  0x03, 0x4B, 0x1B, 0x68, 0x03, 0xF0, 0x00, 0x73, 0x00, 0x2B, 0xF0, 0xD1, 0x44, 0xE0, 0x00, 0xBF,
		  0x00, 0x44, 0x02, 0x58, 0x0C, 0xFC, 0xFF, 0xFF, 0x07, 0x00, 0xFF, 0xFF, 0x21, 0x4B, 0x9B, 0x6A,
		  0x3B, 0x61, 0x20, 0x4B, 0x1B, 0x6B, 0xFB, 0x60, 0x7B, 0x68, 0x5B, 0x6A, 0x01, 0x2B, 0x31, 0xD0,
		  0x3B, 0x69, 0x03, 0xF0, 0x03, 0x02, 0x7B, 0x68, 0x9B, 0x6A, 0x9A, 0x42, 0x2A, 0xD1, 0x3B, 0x69,
		  0x1B, 0x09, 0x03, 0xF0, 0x3F, 0x02, 0x7B, 0x68, 0xDB, 0x6A, 0x9A, 0x42, 0x22, 0xD1, 0xFB, 0x68,
		  0xC3, 0xF3, 0x08, 0x02, 0x7B, 0x68, 0x1B, 0x6B, 0x01, 0x3B, 0x9A, 0x42, 0x1A, 0xD1, 0xFB, 0x68,
		  0x5B, 0x0A, 0x03, 0xF0, 0x7F, 0x02, 0x7B, 0x68, 0x5B, 0x6B, 0x01, 0x3B, 0x9A, 0x42, 0x11, 0xD1,
		  0xFB, 0x68, 0x1B, 0x0C, 0x03, 0xF0, 0x7F, 0x02, 0x7B, 0x68, 0x9B, 0x6B, 0x01, 0x3B, 0x9A, 0x42,
		  0x08, 0xD1, 0xFB, 0x68, 0x1B, 0x0E, 0x03, 0xF0, 0x7F, 0x02, 0x7B, 0x68, 0xDB, 0x6B, 0x01, 0x3B,
		  0x9A, 0x42, 0x01, 0xD0, 0x01, 0x23, 0x00, 0xE0, 0x00, 0x23, 0x18, 0x46, 0x30, 0x37, 0xBD, 0x46,
		  0x80, 0xBD, 0x00, 0xBF, 0x00, 0x44, 0x02, 0x58, 0x80, 0xB5, 0x86, 0xB0, 0x00, 0xAF, 0x78, 0x60,
		  0x39, 0x60, 0x7B, 0x68, 0x00, 0x2B, 0x01, 0xD1, 0x01, 0x23, 0x9C, 0xE1, 0x8A, 0x4B, 0x1B, 0x68,
		  0x03, 0xF0, 0x0F, 0x03, 0x3A, 0x68, 0x9A, 0x42, 0x10, 0xD9, 0x87, 0x4B, 0x1B, 0x68, 0x23, 0xF0,
		  0x0F, 0x02, 0x85, 0x49, 0x3B, 0x68, 0x13, 0x43, 0x0B, 0x60, 0x83, 0x4B, 0x1B, 0x68, 0x03, 0xF0,
		  0x0F, 0x03, 0x3A, 0x68, 0x9A, 0x42, 0x01, 0xD0, 0x01, 0x23, 0x84, 0xE1, 0x7B, 0x68, 0x1B, 0x68,
		  0x03, 0xF0, 0x04, 0x03, 0x00, 0x2B, 0x10, 0xD0, 0x7B, 0x68, 0x1A, 0x69, 0x7B, 0x4B, 0x9B, 0x69,
		  0x03, 0xF0, 0x70, 0x03, 0x9A, 0x42, 0x08, 0xD9, 0x78, 0x4B, 0x9B, 0x69, 0x23, 0xF0, 0x70, 0x02,
		  0x7B, 0x68, 0x1B, 0x69, 0x75, 0x49, 0x13, 0x43, 0x8B, 0x61, 0x7B, 0x68, 0x1B, 0x68, 0x03, 0xF0,
		  0x08, 0x03, 0x00, 0x2B, 0x10, 0xD0, 0x7B, 0x68, 0x5A, 0x69, 0x70, 0x4B, 0xDB, 0x69, 0x03, 0xF0,
		  0x70, 0x03, 0x9A, 0x42, 0x08, 0xD9, 0x6D, 0x4B, 0xDB, 0x69, 0x23, 0xF0, 0x70, 0x02, 0x7B, 0x68,
		  0x5B, 0x69, 0x6A, 0x49, 0x13, 0x43, 0xCB, 0x61, 0x7B, 0x68, 0x1B, 0x68, 0x03, 0xF0, 0x10, 0x03,
		  0x00, 0x2B, 0x10, 0xD0, 0x7B, 0x68, 0x9A, 0x69, 0x64, 0x4B, 0xDB, 0x69, 0x03, 0xF4, 0xE0, 0x63,
		  0x9A, 0x42, 0x08, 0xD9, 0x61, 0x4B, 0xDB, 0x69, 0x23, 0xF4, 0xE0, 0x62, 0x7B, 0x68, 0x9B, 0x69,
		  0x5E, 0x49, 0x13, 0x43, 0xCB, 0x61, 0x7B, 0x68, 0x1B, 0x68, 0x03, 0xF0, 0x20, 0x03, 0x00, 0x2B,
		  0x10, 0xD0, 0x7B, 0x68, 0xDA, 0x69, 0x59, 0x4B, 0x1B, 0x6A, 0x03, 0xF0, 0x70, 0x03, 0x9A, 0x42,
		  0x08, 0xD9, 0x56, 0x4B, 0x1B, 0x6A, 0x23, 0xF0, 0x70, 0x02, 0x7B, 0x68, 0xDB, 0x69, 0x53, 0x49,
		  0x13, 0x43, 0x0B, 0x62, 0x7B, 0x68, 0x1B, 0x68, 0x03, 0xF0, 0x02, 0x03, 0x00, 0x2B, 0x10, 0xD0,
		  0x7B, 0x68, 0xDA, 0x68, 0x4D, 0x4B, 0x9B, 0x69, 0x03, 0xF0, 0x0F, 0x03, 0x9A, 0x42, 0x08, 0xD9,
		  0x4A, 0x4B, 0x9B, 0x69, 0x23, 0xF0, 0x0F, 0x02, 0x7B, 0x68, 0xDB, 0x68, 0x47, 0x49, 0x13, 0x43,
		  0x8B, 0x61, 0x7B, 0x68, 0x1B, 0x68, 0x03, 0xF0, 0x01, 0x03, 0x00, 0x2B, 0x55, 0xD0, 0x43, 0x4B,
		  0x9B, 0x69, 0x23, 0xF4, 0x70, 0x62, 0x7B, 0x68, 0x9B, 0x68, 0x40, 0x49, 0x13, 0x43, 0x8B, 0x61,
		  0x7B, 0x68, 0x5B, 0x68, 0x02, 0x2B, 0x07, 0xD1, 0x3C, 0x4B, 0x1B, 0x68, 0x03, 0xF4, 0x00, 0x33,
		  0x00, 0x2B, 0x21, 0xD1, 0x01, 0x23, 0xF6, 0xE0, 0x7B, 0x68, 0x5B, 0x68, 0x03, 0x2B, 0x07, 0xD1,
		  0x36, 0x4B, 0x1B, 0x68, 0x03, 0xF0, 0x00, 0x73, 0x00, 0x2B, 0x15, 0xD1, 0x01, 0x23, 0xEA, 0xE0,
		  0x7B, 0x68, 0x5B, 0x68, 0x01, 0x2B, 0x07, 0xD1, 0x30, 0x4B, 0x1B, 0x68, 0x03, 0xF4, 0x80, 0x73,
		  0x00, 0x2B, 0x09, 0xD1, 0x01, 0x23, 0xDE, 0xE0, 0x2C, 0x4B, 0x1B, 0x68, 0x03, 0xF0, 0x04, 0x03,
		  0x00, 0x2B, 0x01, 0xD1, 0x01, 0x23, 0xD6, 0xE0, 0x28, 0x4B, 0x1B, 0x69, 0x23, 0xF0, 0x07, 0x02,
		  0x7B, 0x68, 0x5B, 0x68, 0x25, 0x49, 0x13, 0x43, 0x0B, 0x61, 0xFE, 0xF7, 0xCF, 0xFF, 0x78, 0x61,
		  0x0A, 0xE0, 0xFE, 0xF7, 0xCB, 0xFF, 0x02, 0x46, 0x7B, 0x69, 0xD3, 0x1A, 0x41, 0xF2, 0x88, 0x32,
		  0x93, 0x42, 0x01, 0xD9, 0x03, 0x23, 0xBE, 0xE0, 0x1C, 0x4B, 0x1B, 0x69, 0x03, 0xF0, 0x38, 0x02,
		  0x7B, 0x68, 0x5B, 0x68, 0xDB, 0x00, 0x9A, 0x42, 0xEB, 0xD1, 0x7B, 0x68, 0x1B, 0x68, 0x03, 0xF0,
		  0x02, 0x03, 0x00, 0x2B, 0x10, 0xD0, 0x7B, 0x68, 0xDA, 0x68, 0x14, 0x4B, 0x9B, 0x69, 0x03, 0xF0,
		  0x0F, 0x03, 0x9A, 0x42, 0x08, 0xD2, 0x11, 0x4B, 0x9B, 0x69, 0x23, 0xF0, 0x0F, 0x02, 0x7B, 0x68,
		  0xDB, 0x68, 0x0E, 0x49, 0x13, 0x43, 0x8B, 0x61, 0x0B, 0x4B, 0x1B, 0x68, 0x03, 0xF0, 0x0F, 0x03,
		  0x3A, 0x68, 0x9A, 0x42, 0x14, 0xD2, 0x08, 0x4B, 0x1B, 0x68, 0x23, 0xF0, 0x0F, 0x02, 0x06, 0x49,
		  0x3B, 0x68, 0x13, 0x43, 0x0B, 0x60, 0x04, 0x4B, 0x1B, 0x68, 0x03, 0xF0, 0x0F, 0x03, 0x3A, 0x68,
		  0x9A, 0x42, 0x05, 0xD0, 0x01, 0x23, 0x86, 0xE0, 0x00, 0x20, 0x00, 0x52, 0x00, 0x44, 0x02, 0x58,
		  0x7B, 0x68, 0x1B, 0x68, 0x03, 0xF0, 0x04, 0x03, 0x00, 0x2B, 0x10, 0xD0, 0x7B, 0x68, 0x1A, 0x69,
		  0x3F, 0x4B, 0x9B, 0x69, 0x03, 0xF0, 0x70, 0x03, 0x9A, 0x42, 0x08, 0xD2, 0x3C, 0x4B, 0x9B, 0x69,
		  0x23, 0xF0, 0x70, 0x02, 0x7B, 0x68, 0x1B, 0x69, 0x39, 0x49, 0x13, 0x43, 0x8B, 0x61, 0x7B, 0x68,
		  0x1B, 0x68, 0x03, 0xF0, 0x08, 0x03, 0x00, 0x2B, 0x10, 0xD0, 0x7B, 0x68, 0x5A, 0x69, 0x34, 0x4B,
		  0xDB, 0x69, 0x03, 0xF0, 0x70, 0x03, 0x9A, 0x42, 0x08, 0xD2, 0x31, 0x4B, 0xDB, 0x69, 0x23, 0xF0,
		  0x70, 0x02, 0x7B, 0x68, 0x5B, 0x69, 0x2E, 0x49, 0x13, 0x43, 0xCB, 0x61, 0x7B, 0x68, 0x1B, 0x68,
		  0x03, 0xF0, 0x10, 0x03, 0x00, 0x2B, 0x10, 0xD0, 0x7B, 0x68, 0x9A, 0x69, 0x28, 0x4B, 0xDB, 0x69,
		  0x03, 0xF4, 0xE0, 0x63, 0x9A, 0x42, 0x08, 0xD2, 0x25, 0x4B, 0xDB, 0x69, 0x23, 0xF4, 0xE0, 0x62,
		  0x7B, 0x68, 0x9B, 0x69, 0x22, 0x49, 0x13, 0x43, 0xCB, 0x61, 0x7B, 0x68, 0x1B, 0x68, 0x03, 0xF0,
		  0x20, 0x03, 0x00, 0x2B, 0x10, 0xD0, 0x7B, 0x68, 0xDA, 0x69, 0x1D, 0x4B, 0x1B, 0x6A, 0x03, 0xF0,
		  0x70, 0x03, 0x9A, 0x42, 0x08, 0xD2, 0x1A, 0x4B, 0x1B, 0x6A, 0x23, 0xF0, 0x70, 0x02, 0x7B, 0x68,
		  0xDB, 0x69, 0x17, 0x49, 0x13, 0x43, 0x0B, 0x62, 0x00, 0xF0, 0x34, 0xF8, 0x02, 0x46, 0x14, 0x4B,
		  0x9B, 0x69, 0x1B, 0x0A, 0x03, 0xF0, 0x0F, 0x03, 0x12, 0x49, 0xCB, 0x5C, 0x03, 0xF0, 0x1F, 0x03,
		  0x22, 0xFA, 0x03, 0xF3, 0x3B, 0x61, 0x0E, 0x4B, 0x9B, 0x69, 0x03, 0xF0, 0x0F, 0x03, 0x0D, 0x4A,
		  0xD3, 0x5C, 0x03, 0xF0, 0x1F, 0x03, 0x3A, 0x69, 0x22, 0xFA, 0x03, 0xF3, 0x0A, 0x4A, 0x13, 0x60,
		  0x0A, 0x4A, 0x3B, 0x69, 0x13, 0x60, 0x0A, 0x4B, 0x1B, 0x68, 0x18, 0x46, 0xFE, 0xF7, 0xBC, 0xFE,
		  0x03, 0x46, 0xFB, 0x73, 0xFB, 0x7B, 0x18, 0x46, 0x18, 0x37, 0xBD, 0x46, 0x80, 0xBD, 0x00, 0xBF,
		  0x00, 0x44, 0x02, 0x58, 0xD8, 0x4C, 0x00, 0x08, 0x04, 0x00, 0x00, 0x24, 0x00, 0x00, 0x00, 0x24,
		  0x08, 0x00, 0x00, 0x24, 0x80, 0xB4, 0x89, 0xB0, 0x00, 0xAF, 0xB3, 0x4B, 0x1B, 0x69, 0x03, 0xF0,
		  0x38, 0x03, 0x18, 0x2B, 0x00, 0xF2, 0x55, 0x81, 0x01, 0xA2, 0x52, 0xF8, 0x23, 0xF0, 0x00, 0xBF,
		  0x15, 0x20, 0x00, 0x08, 0x53, 0x22, 0x00, 0x08, 0x53, 0x22, 0x00, 0x08, 0x53, 0x22, 0x00, 0x08,
		  0x53, 0x22, 0x00, 0x08, 0x53, 0x22, 0x00, 0x08, 0x53, 0x22, 0x00, 0x08, 0x53, 0x22, 0x00, 0x08,
		  0x3B, 0x20, 0x00, 0x08, 0x53, 0x22, 0x00, 0x08, 0x53, 0x22, 0x00, 0x08, 0x53, 0x22, 0x00, 0x08,
		  0x53, 0x22, 0x00, 0x08, 0x53, 0x22, 0x00, 0x08, 0x53, 0x22, 0x00, 0x08, 0x53, 0x22, 0x00, 0x08,
		  0x41, 0x20, 0x00, 0x08, 0x53, 0x22, 0x00, 0x08, 0x53, 0x22, 0x00, 0x08, 0x53, 0x22, 0x00, 0x08,
		  0x53, 0x22, 0x00, 0x08, 0x53, 0x22, 0x00, 0x08, 0x53, 0x22, 0x00, 0x08, 0x53, 0x22, 0x00, 0x08,
		  0x47, 0x20, 0x00, 0x08, 0x94, 0x4B, 0x1B, 0x68, 0x03, 0xF0, 0x20, 0x03, 0x00, 0x2B, 0x09, 0xD0,
		  0x91, 0x4B, 0x1B, 0x68, 0xDB, 0x08, 0x03, 0xF0, 0x03, 0x03, 0x90, 0x4A, 0x22, 0xFA, 0x03, 0xF3,
		  0xBB, 0x61, 0x11, 0xE1, 0x8D, 0x4B, 0xBB, 0x61, 0x0E, 0xE1, 0x8D, 0x4B, 0xBB, 0x61, 0x0B, 0xE1,
		  0x8C, 0x4B, 0xBB, 0x61, 0x08, 0xE1, 0x88, 0x4B, 0x9B, 0x6A, 0x03, 0xF0, 0x03, 0x03, 0x7B, 0x61,
		  0x85, 0x4B, 0x9B, 0x6A, 0x1B, 0x09, 0x03, 0xF0, 0x3F, 0x03, 0x3B, 0x61, 0x82, 0x4B, 0xDB, 0x6A,
		  0x03, 0xF0, 0x01, 0x03, 0xFB, 0x60, 0x80, 0x4B, 0x5B, 0x6B, 0xDB, 0x08, 0xC3, 0xF3, 0x0C, 0x03,
		  0xFA, 0x68, 0x02, 0xFB, 0x03, 0xF3, 0x07, 0xEE, 0x90, 0x3A, 0xF8, 0xEE, 0x67, 0x7A, 0xC7, 0xED,
		  0x02, 0x7A, 0x3B, 0x69, 0x00, 0x2B, 0x00, 0xF0, 0xE1, 0x80, 0x7B, 0x69, 0x02, 0x2B, 0x00, 0xF0,
		  0x83, 0x80, 0x7B, 0x69, 0x02, 0x2B, 0x00, 0xF2, 0xA1, 0x80, 0x7B, 0x69, 0x00, 0x2B, 0x03, 0xD0,
		  0x7B, 0x69, 0x01, 0x2B, 0x56, 0xD0, 0x99, 0xE0, 0x6F, 0x4B, 0x1B, 0x68, 0x03, 0xF0, 0x20, 0x03,
		  0x00, 0x2B, 0x2D, 0xD0, 0x6C, 0x4B, 0x1B, 0x68, 0xDB, 0x08, 0x03, 0xF0, 0x03, 0x03, 0x6B, 0x4A,
		  0x22, 0xFA, 0x03, 0xF3, 0x7B, 0x60, 0x7B, 0x68, 0x07, 0xEE, 0x90, 0x3A, 0xF8, 0xEE, 0x67, 0x6A,
		  0x3B, 0x69, 0x07, 0xEE, 0x90, 0x3A, 0xF8, 0xEE, 0x67, 0x7A, 0x86, 0xEE, 0xA7, 0x7A, 0x62, 0x4B,
		  0x1B, 0x6B, 0xC3, 0xF3, 0x08, 0x03, 0x07, 0xEE, 0x90, 0x3A, 0xF8, 0xEE, 0x67, 0x6A, 0x97, 0xED,
		  0x02, 0x6A, 0xDF, 0xED, 0x61, 0x5A, 0xC6, 0xEE, 0x25, 0x7A, 0x76, 0xEE, 0xA7, 0x7A, 0xF7, 0xEE,
		  0x00, 0x6A, 0x77, 0xEE, 0xA6, 0x7A, 0x67, 0xEE, 0x27, 0x7A, 0xC7, 0xED, 0x07, 0x7A, 0x87, 0xE0,
		  0x3B, 0x69, 0x07, 0xEE, 0x90, 0x3A, 0xF8, 0xEE, 0x67, 0x7A, 0xDF, 0xED, 0x58, 0x6A, 0x86, 0xEE,
		  0xA7, 0x7A, 0x51, 0x4B, 0x1B, 0x6B, 0xC3, 0xF3, 0x08, 0x03, 0x07, 0xEE, 0x90, 0x3A, 0xF8, 0xEE,
		  0x67, 0x6A, 0x97, 0xED, 0x02, 0x6A, 0xDF, 0xED, 0x50, 0x5A, 0xC6, 0xEE, 0x25, 0x7A, 0x76, 0xEE,
		  0xA7, 0x7A, 0xF7, 0xEE, 0x00, 0x6A, 0x77, 0xEE, 0xA6, 0x7A, 0x67, 0xEE, 0x27, 0x7A, 0xC7, 0xED,
		  0x07, 0x7A, 0x65, 0xE0, 0x3B, 0x69, 0x07, 0xEE, 0x90, 0x3A, 0xF8, 0xEE, 0x67, 0x7A, 0xDF, 0xED,
		  0x48, 0x6A, 0x86, 0xEE, 0xA7, 0x7A, 0x40, 0x4B, 0x1B, 0x6B, 0xC3, 0xF3, 0x08, 0x03, 0x07, 0xEE,
		  0x90, 0x3A, 0xF8, 0xEE, 0x67, 0x6A, 0x97, 0xED, 0x02, 0x6A, 0xDF, 0xED, 0x3F, 0x5A, 0xC6, 0xEE,
		  0x25, 0x7A, 0x76, 0xEE, 0xA7, 0x7A, 0xF7, 0xEE, 0x00, 0x6A, 0x77, 0xEE, 0xA6, 0x7A, 0x67, 0xEE,
		  0x27, 0x7A, 0xC7, 0xED, 0x07, 0x7A, 0x43, 0xE0, 0x3B, 0x69, 0x07, 0xEE, 0x90, 0x3A, 0xF8, 0xEE,
		  0x67, 0x7A, 0xDF, 0xED, 0x38, 0x6A, 0x86, 0xEE, 0xA7, 0x7A, 0x2F, 0x4B, 0x1B, 0x6B, 0xC3, 0xF3,
		  0x08, 0x03, 0x07, 0xEE, 0x90, 0x3A, 0xF8, 0xEE, 0x67, 0x6A, 0x97, 0xED, 0x02, 0x6A, 0xDF, 0xED,
		  0x2E, 0x5A, 0xC6, 0xEE, 0x25, 0x7A, 0x76, 0xEE, 0xA7, 0x7A, 0xF7, 0xEE, 0x00, 0x6A, 0x77, 0xEE,
		  0xA6, 0x7A, 0x67, 0xEE, 0x27, 0x7A, 0xC7, 0xED, 0x07, 0x7A, 0x21, 0xE0, 0x3B, 0x69, 0x07, 0xEE,
		  0x90, 0x3A, 0xF8, 0xEE, 0x67, 0x7A, 0xDF, 0xED, 0x26, 0x6A, 0x86, 0xEE, 0xA7, 0x7A, 0x1E, 0x4B,
		  0x1B, 0x6B, 0xC3, 0xF3, 0x08, 0x03, 0x07, 0xEE, 0x90, 0x3A, 0xF8, 0xEE, 0x67, 0x6A, 0x97, 0xED,
		  0x02, 0x6A, 0xDF, 0xED, 0x1D, 0x5A, 0xC6, 0xEE, 0x25, 0x7A, 0x76, 0xEE, 0xA7, 0x7A, 0xF7, 0xEE,
		  0x00, 0x6A, 0x77, 0xEE, 0xA6, 0x7A, 0x67, 0xEE, 0x27, 0x7A, 0xC7, 0xED, 0x07, 0x7A, 0x00, 0xBF,
		  0x11, 0x4B, 0x1B, 0x6B, 0x5B, 0x0A, 0x03, 0xF0, 0x7F, 0x03, 0x01, 0x33, 0x3B, 0x60, 0x3B, 0x68,
		  0x07, 0xEE, 0x90, 0x3A, 0xB8, 0xEE, 0x67, 0x7A, 0xD7, 0xED, 0x07, 0x6A, 0xC6, 0xEE, 0x87, 0x7A,
		  0xFC, 0xEE, 0xE7, 0x7A, 0x17, 0xEE, 0x90, 0x3A, 0xBB, 0x61, 0x05, 0xE0, 0x00, 0x23, 0xBB, 0x61,
		  0x02, 0xE0, 0x07, 0x4B, 0xBB, 0x61, 0x00, 0xBF, 0xBB, 0x69, 0x18, 0x46, 0x24, 0x37, 0xBD, 0x46,
		  0x5D, 0xF8, 0x04, 0x7B, 0x70, 0x47, 0x00, 0xBF, 0x00, 0x44, 0x02, 0x58, 0x00, 0x90, 0xD0, 0x03,
		  0x00, 0x09, 0x3D, 0x00, 0x00, 0x12, 0x7A, 0x00, 0x00, 0x00, 0x00, 0x46, 0x00, 0x24, 0x74, 0x4C,
		  0x00, 0x24, 0x74, 0x4A, 0x00, 0x24, 0xF4, 0x4A, 0x80, 0xB5, 0x82, 0xB0, 0x00, 0xAF, 0xFF, 0xF7,
		  0x81, 0xFE, 0x02, 0x46, 0x10, 0x4B, 0x9B, 0x69, 0x1B, 0x0A, 0x03, 0xF0, 0x0F, 0x03, 0x0F, 0x49,
		  0xCB, 0x5C, 0x03, 0xF0, 0x1F, 0x03, 0x22, 0xFA, 0x03, 0xF3, 0x7B, 0x60, 0x0A, 0x4B, 0x9B, 0x69,
		  0x03, 0xF0, 0x0F, 0x03, 0x09, 0x4A, 0xD3, 0x5C, 0x03, 0xF0, 0x1F, 0x03, 0x7A, 0x68, 0x22, 0xFA,
		  0x03, 0xF3, 0x07, 0x4A, 0x13, 0x60, 0x07, 0x4A, 0x7B, 0x68, 0x13, 0x60, 0x04, 0x4B, 0x1B, 0x68,
		  0x18, 0x46, 0x08, 0x37, 0xBD, 0x46, 0x80, 0xBD, 0x00, 0x44, 0x02, 0x58, 0xD8, 0x4C, 0x00, 0x08,
		  0x04, 0x00, 0x00, 0x24, 0x00, 0x00, 0x00, 0x24, 0x80, 0xB5, 0x00, 0xAF, 0xFF, 0xF7, 0xCC, 0xFF,
		  0x02, 0x46, 0x06, 0x4B, 0xDB, 0x69, 0x1B, 0x09, 0x03, 0xF0, 0x07, 0x03, 0x04, 0x49, 0xCB, 0x5C,
		  0x03, 0xF0, 0x1F, 0x03, 0x22, 0xFA, 0x03, 0xF3, 0x18, 0x46, 0x80, 0xBD, 0x00, 0x44, 0x02, 0x58,
		  0xD8, 0x4C, 0x00, 0x08, 0x80, 0xB5, 0x00, 0xAF, 0xFF, 0xF7, 0xB6, 0xFF, 0x02, 0x46, 0x06, 0x4B,
		  0xDB, 0x69, 0x1B, 0x0A, 0x03, 0xF0, 0x07, 0x03, 0x04, 0x49, 0xCB, 0x5C, 0x03, 0xF0, 0x1F, 0x03,
		  0x22, 0xFA, 0x03, 0xF3, 0x18, 0x46, 0x80, 0xBD, 0x00, 0x44, 0x02, 0x58, 0xD8, 0x4C, 0x00, 0x08,
		  0x80, 0xB5, 0x86, 0xB0, 0x00, 0xAF, 0x78, 0x60, 0x00, 0x23, 0xFB, 0x75, 0x00, 0x23, 0xBB, 0x75,
		  0x7B, 0x68, 0x1B, 0x68, 0x03, 0xF0, 0x00, 0x63, 0x00, 0x2B, 0x3F, 0xD0, 0x7B, 0x68, 0x9B, 0x6E,
		  0xB3, 0xF5, 0x40, 0x1F, 0x2A, 0xD0, 0xB3, 0xF5, 0x40, 0x1F, 0x24, 0xD8, 0xB3, 0xF5, 0x00, 0x1F,
		  0x18, 0xD0, 0xB3, 0xF5, 0x00, 0x1F, 0x1E, 0xD8, 0x00, 0x2B, 0x03, 0xD0, 0xB3, 0xF5, 0x80, 0x1F,
		  0x07, 0xD0, 0x18, 0xE0, 0xA6, 0x4B, 0xDB, 0x6A, 0xA5, 0x4A, 0x43, 0xF4, 0x00, 0x33, 0xD3, 0x62,
		  0x15, 0xE0, 0x7B, 0x68, 0x04, 0x33, 0x02, 0x21, 0x18, 0x46, 0x01, 0xF0, 0x9B, 0xF9, 0x03, 0x46,
		  0xFB, 0x75, 0x0C, 0xE0, 0x7B, 0x68, 0x24, 0x33, 0x02, 0x21, 0x18, 0x46, 0x01, 0xF0, 0x44, 0xFA,
		  0x03, 0x46, 0xFB, 0x75, 0x03, 0xE0, 0x01, 0x23, 0xFB, 0x75, 0x00, 0xE0, 0x00, 0xBF, 0xFB, 0x7D,
		  0x00, 0x2B, 0x09, 0xD1, 0x96, 0x4B, 0x1B, 0x6D, 0x23, 0xF4, 0x40, 0x12, 0x7B, 0x68, 0x9B, 0x6E,
		  0x93, 0x49, 0x13, 0x43, 0x0B, 0x65, 0x01, 0xE0, 0xFB, 0x7D, 0xBB, 0x75, 0x7B, 0x68, 0x1B, 0x68,
		  0x03, 0xF4, 0x80, 0x73, 0x00, 0x2B, 0x3D, 0xD0, 0x7B, 0x68, 0x5B, 0x6D, 0x04, 0x2B, 0x26, 0xD8,
		  0x01, 0xA2, 0x52, 0xF8, 0x23, 0xF0, 0x00, 0xBF, 0x0D, 0x24, 0x00, 0x08, 0x1B, 0x24, 0x00, 0x08,
		  0x2D, 0x24, 0x00, 0x08, 0x45, 0x24, 0x00, 0x08, 0x45, 0x24, 0x00, 0x08, 0x84, 0x4B, 0xDB, 0x6A,
		  0x83, 0x4A, 0x43, 0xF4, 0x00, 0x33, 0xD3, 0x62, 0x15, 0xE0, 0x7B, 0x68, 0x04, 0x33, 0x00, 0x21,
		  0x18, 0x46, 0x01, 0xF0, 0x57, 0xF9, 0x03, 0x46, 0xFB, 0x75, 0x0C, 0xE0, 0x7B, 0x68, 0x24, 0x33,
		  0x00, 0x21, 0x18, 0x46, 0x01, 0xF0, 0x00, 0xFA, 0x03, 0x46, 0xFB, 0x75, 0x03, 0xE0, 0x01, 0x23,
		  0xFB, 0x75, 0x00, 0xE0, 0x00, 0xBF, 0xFB, 0x7D, 0x00, 0x2B, 0x09, 0xD1, 0x74, 0x4B, 0x1B, 0x6D,
		  0x23, 0xF0, 0x07, 0x02, 0x7B, 0x68, 0x5B, 0x6D, 0x71, 0x49, 0x13, 0x43, 0x0B, 0x65, 0x01, 0xE0,
		  0xFB, 0x7D, 0xBB, 0x75, 0x7B, 0x68, 0x1B, 0x68, 0x03, 0xF4, 0x00, 0x73, 0x00, 0x2B, 0x4A, 0xD0,
		  0x7B, 0x68, 0x9B, 0x6D, 0xB3, 0xF5, 0xA0, 0x7F, 0x31, 0xD0, 0xB3, 0xF5, 0xA0, 0x7F, 0x2B, 0xD8,
		  0xB3, 0xF5, 0x80, 0x7F, 0x2D, 0xD0, 0xB3, 0xF5, 0x80, 0x7F, 0x25, 0xD8, 0xC0, 0x2B, 0x2A, 0xD0,
		  0xC0, 0x2B, 0x21, 0xD8, 0x80, 0x2B, 0x16, 0xD0, 0x80, 0x2B, 0x1D, 0xD8, 0x00, 0x2B, 0x02, 0xD0,
		  0x40, 0x2B, 0x07, 0xD0, 0x18, 0xE0, 0x5E, 0x4B, 0xDB, 0x6A, 0x5D, 0x4A, 0x43, 0xF4, 0x00, 0x33,
		  0xD3, 0x62, 0x19, 0xE0, 0x7B, 0x68, 0x04, 0x33, 0x00, 0x21, 0x18, 0x46, 0x01, 0xF0, 0x0A, 0xF9,
		  0x03, 0x46, 0xFB, 0x75, 0x10, 0xE0, 0x7B, 0x68, 0x24, 0x33, 0x00, 0x21, 0x18, 0x46, 0x01, 0xF0,
		  0xB3, 0xF9, 0x03, 0x46, 0xFB, 0x75, 0x07, 0xE0, 0x01, 0x23, 0xFB, 0x75, 0x04, 0xE0, 0x00, 0xBF,
		  0x02, 0xE0, 0x00, 0xBF, 0x00, 0xE0, 0x00, 0xBF, 0xFB, 0x7D, 0x00, 0x2B, 0x09, 0xD1, 0x4C, 0x4B,
		  0x1B, 0x6D, 0x23, 0xF4, 0xE0, 0x72, 0x7B, 0x68, 0x9B, 0x6D, 0x49, 0x49, 0x13, 0x43, 0x0B, 0x65,
		  0x01, 0xE0, 0xFB, 0x7D, 0xBB, 0x75, 0x7B, 0x68, 0x1B, 0x68, 0x03, 0xF4, 0x80, 0x63, 0x00, 0x2B,
		  0x4F, 0xD0, 0x7B, 0x68, 0xDB, 0x6D, 0xB3, 0xF5, 0x20, 0x6F, 0x36, 0xD0, 0xB3, 0xF5, 0x20, 0x6F,
		  0x30, 0xD8, 0xB3, 0xF5, 0x00, 0x6F, 0x32, 0xD0, 0xB3, 0xF5, 0x00, 0x6F, 0x2A, 0xD8, 0xB3, 0xF5,
		  0xC0, 0x6F, 0x2E, 0xD0, 0xB3, 0xF5, 0xC0, 0x6F, 0x24, 0xD8, 0xB3, 0xF5, 0x80, 0x6F, 0x18, 0xD0,
		  0xB3, 0xF5, 0x80, 0x6F, 0x1E, 0xD8, 0x00, 0x2B, 0x03, 0xD0, 0xB3, 0xF5, 0x00, 0x7F, 0x07, 0xD0,
		  0x18, 0xE0, 0x33, 0x4B, 0xDB, 0x6A, 0x32, 0x4A, 0x43, 0xF4, 0x00, 0x33, 0xD3, 0x62, 0x19, 0xE0,
		  0x7B, 0x68, 0x04, 0x33, 0x00, 0x21, 0x18, 0x46, 0x01, 0xF0, 0xB4, 0xF8, 0x03, 0x46, 0xFB, 0x75,
		  0x10, 0xE0, 0x7B, 0x68, 0x24, 0x33, 0x00, 0x21, 0x18, 0x46, 0x01, 0xF0, 0x5D, 0xF9, 0x03, 0x46,
		  0xFB, 0x75, 0x07, 0xE0, 0x01, 0x23, 0xFB, 0x75, 0x04, 0xE0, 0x00, 0xBF, 0x02, 0xE0, 0x00, 0xBF,
		  0x00, 0xE0, 0x00, 0xBF, 0xFB, 0x7D, 0x00, 0x2B, 0x09, 0xD1, 0x21, 0x4B, 0x1B, 0x6D, 0x23, 0xF4,
		  0x60, 0x62, 0x7B, 0x68, 0xDB, 0x6D, 0x1E, 0x49, 0x13, 0x43, 0x0B, 0x65, 0x01, 0xE0, 0xFB, 0x7D,
		  0xBB, 0x75, 0x7B, 0x68, 0x1B, 0x68, 0x03, 0xF0, 0x00, 0x73, 0x00, 0x2B, 0x34, 0xD0, 0x7B, 0x68,
		  0x9B, 0x6C, 0x30, 0x2B, 0x1C, 0xD0, 0x30, 0x2B, 0x17, 0xD8, 0x20, 0x2B, 0x0C, 0xD0, 0x20, 0x2B,
		  0x13, 0xD8, 0x00, 0x2B, 0x16, 0xD0, 0x10, 0x2B, 0x0F, 0xD1, 0x11, 0x4B, 0xDB, 0x6A, 0x10, 0x4A,
		  0x43, 0xF4, 0x00, 0x33, 0xD3, 0x62, 0x0E, 0xE0, 0x7B, 0x68, 0x04, 0x33, 0x02, 0x21, 0x18, 0x46,
		  0x01, 0xF0, 0x70, 0xF8, 0x03, 0x46, 0xFB, 0x75, 0x05, 0xE0, 0x01, 0x23, 0xFB, 0x75, 0x02, 0xE0,
		  0x00, 0xBF, 0x00, 0xE0, 0x00, 0xBF, 0xFB, 0x7D, 0x00, 0x2B, 0x0B, 0xD1, 0x04, 0x4B, 0xDB, 0x6C,
		  0x23, 0xF0, 0x30, 0x02, 0x7B, 0x68, 0x9B, 0x6C, 0x01, 0x49, 0x13, 0x43, 0xCB, 0x64, 0x03, 0xE0,
		  0x00, 0x44, 0x02, 0x58, 0xFB, 0x7D, 0xBB, 0x75, 0x7B, 0x68, 0x1B, 0x68, 0x03, 0xF4, 0x80, 0x53,
		  0x00, 0x2B, 0x47, 0xD0, 0x7B, 0x68, 0x1B, 0x6E, 0xB3, 0xF5, 0x80, 0x4F, 0x30, 0xD0, 0xB3, 0xF5,
		  0x80, 0x4F, 0x2A, 0xD8, 0xB3, 0xF5, 0x40, 0x5F, 0x2C, 0xD0, 0xB3, 0xF5, 0x40, 0x5F, 0x24, 0xD8,
		  0xB3, 0xF5, 0x00, 0x5F, 0x18, 0xD0, 0xB3, 0xF5, 0x00, 0x5F, 0x1E, 0xD8, 0x00, 0x2B, 0x03, 0xD0,
		  0xB3, 0xF5, 0x80, 0x5F, 0x07, 0xD0, 0x18, 0xE0, 0xB0, 0x4B, 0xDB, 0x6A, 0xAF, 0x4A, 0x43, 0xF4,
		  0x00, 0x33, 0xD3, 0x62, 0x17, 0xE0, 0x7B, 0x68, 0x04, 0x33, 0x00, 0x21, 0x18, 0x46, 0x01, 0xF0,
		  0x29, 0xF8, 0x03, 0x46, 0xFB, 0x75, 0x0E, 0xE0, 0x7B, 0x68, 0x24, 0x33, 0x00, 0x21, 0x18, 0x46,
		  0x01, 0xF0, 0xD2, 0xF8, 0x03, 0x46, 0xFB, 0x75, 0x05, 0xE0, 0x01, 0x23, 0xFB, 0x75, 0x02, 0xE0,
		  0x00, 0xBF, 0x00, 0xE0, 0x00, 0xBF, 0xFB, 0x7D, 0x00, 0x2B, 0x09, 0xD1, 0x9F, 0x4B, 0x1B, 0x6D,
		  0x23, 0xF4, 0xE0, 0x42, 0x7B, 0x68, 0x1B, 0x6E, 0x9C, 0x49, 0x13, 0x43, 0x0B, 0x65, 0x01, 0xE0,
		  0xFB, 0x7D, 0xBB, 0x75, 0x7B, 0x68, 0x1B, 0x68, 0x03, 0xF4, 0x00, 0x53, 0x00, 0x2B, 0x49, 0xD0,
		  0x7B, 0x68, 0x5B, 0x6E, 0xB3, 0xF5, 0xA0, 0x2F, 0x2E, 0xD0, 0xB3, 0xF5, 0xA0, 0x2F, 0x28, 0xD8,
		  0xB3, 0xF5, 0x80, 0x2F, 0x2A, 0xD0, 0xB3, 0xF5, 0x80, 0x2F, 0x22, 0xD8, 0xB3, 0xF5, 0x40, 0x3F,
		  0x26, 0xD0, 0xB3, 0xF5, 0x40, 0x3F, 0x1C, 0xD8, 0xB3, 0xF5, 0x00, 0x3F, 0x10, 0xD0, 0xB3, 0xF5,
		  0x00, 0x3F, 0x16, 0xD8, 0x00, 0x2B, 0x1D, 0xD0, 0xB3, 0xF5, 0x80, 0x3F, 0x11, 0xD1, 0x7B, 0x68,
		  0x04, 0x33, 0x01, 0x21, 0x18, 0x46, 0x00, 0xF0, 0xDD, 0xFF, 0x03, 0x46, 0xFB, 0x75, 0x12, 0xE0,
		  0x7B, 0x68, 0x24, 0x33, 0x01, 0x21, 0x18, 0x46, 0x01, 0xF0, 0x86, 0xF8, 0x03, 0x46, 0xFB, 0x75,
		  0x09, 0xE0, 0x01, 0x23, 0xFB, 0x75, 0x06, 0xE0, 0x00, 0xBF, 0x04, 0xE0, 0x00, 0xBF, 0x02, 0xE0,
		  0x00, 0xBF, 0x00, 0xE0, 0x00, 0xBF, 0xFB, 0x7D, 0x00, 0x2B, 0x09, 0xD1, 0x77, 0x4B, 0x1B, 0x6D,
		  0x23, 0xF4, 0xE0, 0x22, 0x7B, 0x68, 0x5B, 0x6E, 0x74, 0x49, 0x13, 0x43, 0x0B, 0x65, 0x01, 0xE0,
		  0xFB, 0x7D, 0xBB, 0x75, 0x7B, 0x68, 0x1B, 0x68, 0x03, 0xF4, 0x80, 0x43, 0x00, 0x2B, 0x53, 0xD0,
		  0x7B, 0x68, 0xD3, 0xF8, 0xAC, 0x30, 0xB3, 0xF1, 0xC0, 0x4F, 0x34, 0xD0, 0xB3, 0xF1, 0xC0, 0x4F,
		  0x2E, 0xD8, 0xB3, 0xF1, 0xA0, 0x4F, 0x30, 0xD0, 0xB3, 0xF1, 0xA0, 0x4F, 0x28, 0xD8, 0xB3, 0xF1,
		  0x80, 0x4F, 0x2C, 0xD0, 0xB3, 0xF1, 0x80, 0x4F, 0x22, 0xD8, 0xB3, 0xF1, 0x40, 0x5F, 0x28, 0xD0,
		  0xB3, 0xF1, 0x40, 0x5F, 0x1C, 0xD8, 0xB3, 0xF1, 0x00, 0x5F, 0x10, 0xD0, 0xB3, 0xF1, 0x00, 0x5F,
		  0x16, 0xD8, 0x00, 0x2B, 0x1F, 0xD0, 0xB3, 0xF1, 0x80, 0x5F, 0x11, 0xD1, 0x7B, 0x68, 0x04, 0x33,
		  0x01, 0x21, 0x18, 0x46, 0x00, 0xF0, 0x86, 0xFF, 0x03, 0x46, 0xFB, 0x75, 0x14, 0xE0, 0x7B, 0x68,
		  0x24, 0x33, 0x01, 0x21, 0x18, 0x46, 0x01, 0xF0, 0x2F, 0xF8, 0x03, 0x46, 0xFB, 0x75, 0x0B, 0xE0,
		  0x01, 0x23, 0xFB, 0x75, 0x08, 0xE0, 0x00, 0xBF, 0x06, 0xE0, 0x00, 0xBF, 0x04, 0xE0, 0x00, 0xBF,
		  0x02, 0xE0, 0x00, 0xBF, 0x00, 0xE0, 0x00, 0xBF, 0xFB, 0x7D, 0x00, 0x2B, 0x0A, 0xD1, 0x4B, 0x4B,
		  0x9B, 0x6D, 0x23, 0xF0, 0xE0, 0x42, 0x7B, 0x68, 0xD3, 0xF8, 0xAC, 0x30, 0x47, 0x49, 0x13, 0x43,
		  0x8B, 0x65, 0x01, 0xE0, 0xFB, 0x7D, 0xBB, 0x75, 0x7B, 0x68, 0x1B, 0x68, 0x03, 0xF4, 0x00, 0x43,
		  0x00, 0x2B, 0x2F, 0xD0, 0x7B, 0x68, 0x5B, 0x6F, 0xB3, 0xF1, 0x00, 0x5F, 0x0E, 0xD0, 0xB3, 0xF1,
		  0x00, 0x5F, 0x14, 0xD8, 0x00, 0x2B, 0x15, 0xD0, 0xB3, 0xF1, 0x80, 0x5F, 0x0F, 0xD1, 0x3B, 0x4B,
		  0xDB, 0x6A, 0x3A, 0x4A, 0x43, 0xF4, 0x00, 0x33, 0xD3, 0x62, 0x0C, 0xE0, 0x7B, 0x68, 0x04, 0x33,
		  0x01, 0x21, 0x18, 0x46, 0x00, 0xF0, 0x3E, 0xFF, 0x03, 0x46, 0xFB, 0x75, 0x03, 0xE0, 0x01, 0x23,
		  0xFB, 0x75, 0x00, 0xE0, 0x00, 0xBF, 0xFB, 0x7D, 0x00, 0x2B, 0x09, 0xD1, 0x2F, 0x4B, 0x1B, 0x6D,
		  0x23, 0xF0, 0x40, 0x52, 0x7B, 0x68, 0x5B, 0x6F, 0x2C, 0x49, 0x13, 0x43, 0x0B, 0x65, 0x01, 0xE0,
		  0xFB, 0x7D, 0xBB, 0x75, 0x7B, 0x68, 0x1B, 0x68, 0x03, 0xF0, 0x80, 0x73, 0x00, 0x2B, 0x32, 0xD0,
		  0x7B, 0x68, 0x5B, 0x6C, 0x03, 0x2B, 0x1B, 0xD8, 0x01, 0xA2, 0x52, 0xF8, 0x23, 0xF0, 0x00, 0xBF,
		  0xD7, 0x28, 0x00, 0x08, 0xB1, 0x28, 0x00, 0x08, 0xBF, 0x28, 0x00, 0x08, 0xD7, 0x28, 0x00, 0x08,
		  0x1E, 0x4B, 0xDB, 0x6A, 0x1D, 0x4A, 0x43, 0xF4, 0x00, 0x33, 0xD3, 0x62, 0x0C, 0xE0, 0x7B, 0x68,
		  0x04, 0x33, 0x02, 0x21, 0x18, 0x46, 0x00, 0xF0, 0x05, 0xFF, 0x03, 0x46, 0xFB, 0x75, 0x03, 0xE0,
		  0x01, 0x23, 0xFB, 0x75, 0x00, 0xE0, 0x00, 0xBF, 0xFB, 0x7D, 0x00, 0x2B, 0x09, 0xD1, 0x13, 0x4B,
		  0xDB, 0x6C, 0x23, 0xF0, 0x03, 0x02, 0x7B, 0x68, 0x5B, 0x6C, 0x10, 0x49, 0x13, 0x43, 0xCB, 0x64,
		  0x01, 0xE0, 0xFB, 0x7D, 0xBB, 0x75, 0x7B, 0x68, 0x1B, 0x68, 0x03, 0xF4, 0x80, 0x03, 0x00, 0x2B,
		  0x00, 0xF0, 0x8A, 0x80, 0x0A, 0x4B, 0x1B, 0x68, 0x09, 0x4A, 0x43, 0xF4, 0x80, 0x73, 0x13, 0x60,
		  0xFE, 0xF7, 0x34, 0xFA, 0x38, 0x61, 0x0D, 0xE0, 0xFE, 0xF7, 0x30, 0xFA, 0x02, 0x46, 0x3B, 0x69,
		  0xD3, 0x1A, 0x64, 0x2B, 0x06, 0xD9, 0x03, 0x23, 0xFB, 0x75, 0x09, 0xE0, 0x00, 0x44, 0x02, 0x58,
		  0x00, 0x48, 0x02, 0x58, 0xBA, 0x4B, 0x1B, 0x68, 0x03, 0xF4, 0x80, 0x73, 0x00, 0x2B, 0xEB, 0xD0,
		  0xFB, 0x7D, 0x00, 0x2B, 0x66, 0xD1, 0xB7, 0x4B, 0x1A, 0x6F, 0x7B, 0x68, 0xD3, 0xF8, 0xB0, 0x30,
		  0x53, 0x40, 0x03, 0xF4, 0x40, 0x73, 0x00, 0x2B, 0x13, 0xD0, 0xB2, 0x4B, 0x1B, 0x6F, 0x23, 0xF4,
		  0x40, 0x73, 0xFB, 0x60, 0xAF, 0x4B, 0x1B, 0x6F, 0xAE, 0x4A, 0x43, 0xF4, 0x80, 0x33, 0x13, 0x67,
		  0xAC, 0x4B, 0x1B, 0x6F, 0xAB, 0x4A, 0x23, 0xF4, 0x80, 0x33, 0x13, 0x67, 0xA9, 0x4A, 0xFB, 0x68,
		  0x13, 0x67, 0x7B, 0x68, 0xD3, 0xF8, 0xB0, 0x30, 0xB3, 0xF5, 0x80, 0x7F, 0x15, 0xD1, 0xFE, 0xF7,
		  0xF5, 0xF9, 0x38, 0x61, 0x0B, 0xE0, 0xFE, 0xF7, 0xF1, 0xF9, 0x02, 0x46, 0x3B, 0x69, 0xD3, 0x1A,
		  0x41, 0xF2, 0x88, 0x32, 0x93, 0x42, 0x02, 0xD9, 0x03, 0x23, 0xFB, 0x75, 0x05, 0xE0, 0x9D, 0x4B,
		  0x1B, 0x6F, 0x03, 0xF0, 0x02, 0x03, 0x00, 0x2B, 0xED, 0xD0, 0xFB, 0x7D, 0x00, 0x2B, 0x26, 0xD1,
		  0x7B, 0x68, 0xD3, 0xF8, 0xB0, 0x30, 0x03, 0xF4, 0x40, 0x73, 0xB3, 0xF5, 0x40, 0x7F, 0x0D, 0xD1,
		  0x94, 0x4B, 0x1B, 0x69, 0x23, 0xF4, 0x7C, 0x52, 0x7B, 0x68, 0xD3, 0xF8, 0xB0, 0x30, 0x19, 0x09,
		  0x91, 0x4B, 0x0B, 0x40, 0x8F, 0x49, 0x13, 0x43, 0x0B, 0x61, 0x05, 0xE0, 0x8D, 0x4B, 0x1B, 0x69,
		  0x8C, 0x4A, 0x23, 0xF4, 0x7C, 0x53, 0x13, 0x61, 0x8A, 0x4B, 0x1A, 0x6F, 0x7B, 0x68, 0xD3, 0xF8,
		  0xB0, 0x30, 0xC3, 0xF3, 0x0B, 0x03, 0x87, 0x49, 0x13, 0x43, 0x0B, 0x67, 0x04, 0xE0, 0xFB, 0x7D,
		  0xBB, 0x75, 0x01, 0xE0, 0xFB, 0x7D, 0xBB, 0x75, 0x7B, 0x68, 0x1B, 0x68, 0x03, 0xF0, 0x01, 0x03,
		  0x00, 0x2B, 0x7F, 0xD0, 0x7B, 0x68, 0xD3, 0xF8, 0x80, 0x30, 0x28, 0x2B, 0x66, 0xD8, 0x01, 0xA2,
		  0x52, 0xF8, 0x23, 0xF0, 0x03, 0x2B, 0x00, 0x08, 0xFD, 0x2A, 0x00, 0x08, 0xFD, 0x2A, 0x00, 0x08,
		  0xFD, 0x2A, 0x00, 0x08, 0xFD, 0x2A, 0x00, 0x08, 0xFD, 0x2A, 0x00, 0x08, 0xFD, 0x2A, 0x00, 0x08,
		  0xFD, 0x2A, 0x00, 0x08, 0xD9, 0x2A, 0x00, 0x08, 0xFD, 0x2A, 0x00, 0x08, 0xFD, 0x2A, 0x00, 0x08,
		  0xFD, 0x2A, 0x00, 0x08, 0xFD, 0x2A, 0x00, 0x08, 0xFD, 0x2A, 0x00, 0x08, 0xFD, 0x2A, 0x00, 0x08,
		  0xFD, 0x2A, 0x00, 0x08, 0xEB, 0x2A, 0x00, 0x08, 0xFD, 0x2A, 0x00, 0x08, 0xFD, 0x2A, 0x00, 0x08,
		  0xFD, 0x2A, 0x00, 0x08, 0xFD, 0x2A, 0x00, 0x08, 0xFD, 0x2A, 0x00, 0x08, 0xFD, 0x2A, 0x00, 0x08,
		  0xFD, 0x2A, 0x00, 0x08, 0x03, 0x2B, 0x00, 0x08, 0xFD, 0x2A, 0x00, 0x08, 0xFD, 0x2A, 0x00, 0x08,
		  0xFD, 0x2A, 0x00, 0x08, 0xFD, 0x2A, 0x00, 0x08, 0xFD, 0x2A, 0x00, 0x08, 0xFD, 0x2A, 0x00, 0x08,
		  0xFD, 0x2A, 0x00, 0x08, 0x03, 0x2B, 0x00, 0x08, 0xFD, 0x2A, 0x00, 0x08, 0xFD, 0x2A, 0x00, 0x08,
		  0xFD, 0x2A, 0x00, 0x08, 0xFD, 0x2A, 0x00, 0x08, 0xFD, 0x2A, 0x00, 0x08, 0xFD, 0x2A, 0x00, 0x08,
		  0xFD, 0x2A, 0x00, 0x08, 0x03, 0x2B, 0x00, 0x08, 0x7B, 0x68, 0x04, 0x33, 0x01, 0x21, 0x18, 0x46,
		  0x00, 0xF0, 0xF8, 0xFD, 0x03, 0x46, 0xFB, 0x75, 0x0C, 0xE0, 0x7B, 0x68, 0x24, 0x33, 0x01, 0x21,
		  0x18, 0x46, 0x00, 0xF0, 0xA1, 0xFE, 0x03, 0x46, 0xFB, 0x75, 0x03, 0xE0, 0x01, 0x23, 0xFB, 0x75,
		  0x00, 0xE0, 0x00, 0xBF, 0xFB, 0x7D, 0x00, 0x2B, 0x0A, 0xD1, 0x46, 0x4B, 0x5B, 0x6D, 0x23, 0xF0,
		  0x38, 0x02, 0x7B, 0x68, 0xD3, 0xF8, 0x80, 0x30, 0x42, 0x49, 0x13, 0x43, 0x4B, 0x65, 0x01, 0xE0,
		  0xFB, 0x7D, 0xBB, 0x75, 0x7B, 0x68, 0x1B, 0x68, 0x03, 0xF0, 0x02, 0x03, 0x00, 0x2B, 0x38, 0xD0,
		  0x7B, 0x68, 0xDB, 0x6F, 0x05, 0x2B, 0x21, 0xD8, 0x01, 0xA2, 0x52, 0xF8, 0x23, 0xF0, 0x00, 0xBF,
		  0x83, 0x2B, 0x00, 0x08, 0x59, 0x2B, 0x00, 0x08, 0x6B, 0x2B, 0x00, 0x08, 0x83, 0x2B, 0x00, 0x08,
		  0x83, 0x2B, 0x00, 0x08, 0x83, 0x2B, 0x00, 0x08, 0x7B, 0x68, 0x04, 0x33, 0x01, 0x21, 0x18, 0x46,
		  0x00, 0xF0, 0xB8, 0xFD, 0x03, 0x46, 0xFB, 0x75, 0x0C, 0xE0, 0x7B, 0x68, 0x24, 0x33, 0x01, 0x21,
		  0x18, 0x46, 0x00, 0xF0, 0x61, 0xFE, 0x03, 0x46, 0xFB, 0x75, 0x03, 0xE0, 0x01, 0x23, 0xFB, 0x75,
		  0x00, 0xE0, 0x00, 0xBF, 0xFB, 0x7D, 0x00, 0x2B, 0x09, 0xD1, 0x26, 0x4B, 0x5B, 0x6D, 0x23, 0xF0,
		  0x07, 0x02, 0x7B, 0x68, 0xDB, 0x6F, 0x23, 0x49, 0x13, 0x43, 0x4B, 0x65, 0x01, 0xE0, 0xFB, 0x7D,
		  0xBB, 0x75, 0x7B, 0x68, 0x1B, 0x68, 0x03, 0xF0, 0x04, 0x03, 0x00, 0x2B, 0x40, 0xD0, 0x7B, 0x68,
		  0xD3, 0xF8, 0x98, 0x30, 0x05, 0x2B, 0x21, 0xD8, 0x01, 0xA2, 0x52, 0xF8, 0x23, 0xF0, 0x00, 0xBF,
		  0x03, 0x2C, 0x00, 0x08, 0xD9, 0x2B, 0x00, 0x08, 0xEB, 0x2B, 0x00, 0x08, 0x03, 0x2C, 0x00, 0x08,
		  0x03, 0x2C, 0x00, 0x08, 0x03, 0x2C, 0x00, 0x08, 0x7B, 0x68, 0x04, 0x33, 0x01, 0x21, 0x18, 0x46,
		  0x00, 0xF0, 0x78, 0xFD, 0x03, 0x46, 0xFB, 0x75, 0x0C, 0xE0, 0x7B, 0x68, 0x24, 0x33, 0x01, 0x21,
		  0x18, 0x46, 0x00, 0xF0, 0x21, 0xFE, 0x03, 0x46, 0xFB, 0x75, 0x03, 0xE0, 0x01, 0x23, 0xFB, 0x75,
		  0x00, 0xE0, 0x00, 0xBF, 0xFB, 0x7D, 0x00, 0x2B, 0x10, 0xD1, 0x06, 0x4B, 0x9B, 0x6D, 0x23, 0xF0,
		  0x07, 0x02, 0x7B, 0x68, 0xD3, 0xF8, 0x98, 0x30, 0x02, 0x49, 0x13, 0x43, 0x8B, 0x65, 0x07, 0xE0,
		  0x00, 0x48, 0x02, 0x58, 0x00, 0x44, 0x02, 0x58, 0xCF, 0xFF, 0xFF, 0x00, 0xFB, 0x7D, 0xBB, 0x75,
		  0x7B, 0x68, 0x1B, 0x68, 0x03, 0xF0, 0x20, 0x03, 0x00, 0x2B, 0x4B, 0xD0, 0x7B, 0x68, 0xD3, 0xF8,
		  0x94, 0x30, 0xB3, 0xF1, 0xA0, 0x4F, 0x2E, 0xD0, 0xB3, 0xF1, 0xA0, 0x4F, 0x28, 0xD8, 0xB3, 0xF1,
		  0x80, 0x4F, 0x2A, 0xD0, 0xB3, 0xF1, 0x80, 0x4F, 0x22, 0xD8, 0xB3, 0xF1, 0x40, 0x5F, 0x26, 0xD0,
		  0xB3, 0xF1, 0x40, 0x5F, 0x1C, 0xD8, 0xB3, 0xF1, 0x00, 0x5F, 0x10, 0xD0, 0xB3, 0xF1, 0x00, 0x5F,
		  0x16, 0xD8, 0x00, 0x2B, 0x1D, 0xD0, 0xB3, 0xF1, 0x80, 0x5F, 0x11, 0xD1, 0x7B, 0x68, 0x04, 0x33,
		  0x00, 0x21, 0x18, 0x46, 0x00, 0xF0, 0x26, 0xFD, 0x03, 0x46, 0xFB, 0x75, 0x12, 0xE0, 0x7B, 0x68,
		  0x24, 0x33, 0x02, 0x21, 0x18, 0x46, 0x00, 0xF0, 0xCF, 0xFD, 0x03, 0x46, 0xFB, 0x75, 0x09, 0xE0,
		  0x01, 0x23, 0xFB, 0x75, 0x06, 0xE0, 0x00, 0xBF, 0x04, 0xE0, 0x00, 0xBF, 0x02, 0xE0, 0x00, 0xBF,
		  0x00, 0xE0, 0x00, 0xBF, 0xFB, 0x7D, 0x00, 0x2B, 0x0A, 0xD1, 0xB3, 0x4B, 0x5B, 0x6D, 0x23, 0xF0,
		  0xE0, 0x42, 0x7B, 0x68, 0xD3, 0xF8, 0x94, 0x30, 0xAF, 0x49, 0x13, 0x43, 0x4B, 0x65, 0x01, 0xE0,
		  0xFB, 0x7D, 0xBB, 0x75, 0x7B, 0x68, 0x1B, 0x68, 0x03, 0xF0, 0x40, 0x03, 0x00, 0x2B, 0x4B, 0xD0,
		  0x7B, 0x68, 0xD3, 0xF8, 0xA0, 0x30, 0xB3, 0xF5, 0xA0, 0x5F, 0x2E, 0xD0, 0xB3, 0xF5, 0xA0, 0x5F,
		  0x28, 0xD8, 0xB3, 0xF5, 0x80, 0x5F, 0x2A, 0xD0, 0xB3, 0xF5, 0x80, 0x5F, 0x22, 0xD8, 0xB3, 0xF5,
		  0x40, 0x6F, 0x26, 0xD0, 0xB3, 0xF5, 0x40, 0x6F, 0x1C, 0xD8, 0xB3, 0xF5, 0x00, 0x6F, 0x10, 0xD0,
		  0xB3, 0xF5, 0x00, 0x6F, 0x16, 0xD8, 0x00, 0x2B, 0x1D, 0xD0, 0xB3, 0xF5, 0x80, 0x6F, 0x11, 0xD1,
		  0x7B, 0x68, 0x04, 0x33, 0x00, 0x21, 0x18, 0x46, 0x00, 0xF0, 0xD4, 0xFC, 0x03, 0x46, 0xFB, 0x75,
		  0x12, 0xE0, 0x7B, 0x68, 0x24, 0x33, 0x02, 0x21, 0x18, 0x46, 0x00, 0xF0, 0x7D, 0xFD, 0x03, 0x46,
		  0xFB, 0x75, 0x09, 0xE0, 0x01, 0x23, 0xFB, 0x75, 0x06, 0xE0, 0x00, 0xBF, 0x04, 0xE0, 0x00, 0xBF,
		  0x02, 0xE0, 0x00, 0xBF, 0x00, 0xE0, 0x00, 0xBF, 0xFB, 0x7D, 0x00, 0x2B, 0x0A, 0xD1, 0x8A, 0x4B,
		  0x9B, 0x6D, 0x23, 0xF4, 0xE0, 0x52, 0x7B, 0x68, 0xD3, 0xF8, 0xA0, 0x30, 0x86, 0x49, 0x13, 0x43,
		  0x8B, 0x65, 0x01, 0xE0, 0xFB, 0x7D, 0xBB, 0x75, 0x7B, 0x68, 0x1B, 0x68, 0x03, 0xF0, 0x80, 0x03,
		  0x00, 0x2B, 0x4B, 0xD0, 0x7B, 0x68, 0xD3, 0xF8, 0xA4, 0x30, 0xB3, 0xF5, 0x20, 0x4F, 0x2E, 0xD0,
		  0xB3, 0xF5, 0x20, 0x4F, 0x28, 0xD8, 0xB3, 0xF5, 0x00, 0x4F, 0x2A, 0xD0, 0xB3, 0xF5, 0x00, 0x4F,
		  0x22, 0xD8, 0xB3, 0xF5, 0xC0, 0x4F, 0x26, 0xD0, 0xB3, 0xF5, 0xC0, 0x4F, 0x1C, 0xD8, 0xB3, 0xF5,
		  0x80, 0x4F, 0x10, 0xD0, 0xB3, 0xF5, 0x80, 0x4F, 0x16, 0xD8, 0x00, 0x2B, 0x1D, 0xD0, 0xB3, 0xF5,
		  0x00, 0x5F, 0x11, 0xD1, 0x7B, 0x68, 0x04, 0x33, 0x00, 0x21, 0x18, 0x46, 0x00, 0xF0, 0x82, 0xFC,
		  0x03, 0x46, 0xFB, 0x75, 0x12, 0xE0, 0x7B, 0x68, 0x24, 0x33, 0x02, 0x21, 0x18, 0x46, 0x00, 0xF0,
		  0x2B, 0xFD, 0x03, 0x46, 0xFB, 0x75, 0x09, 0xE0, 0x01, 0x23, 0xFB, 0x75, 0x06, 0xE0, 0x00, 0xBF,
		  0x04, 0xE0, 0x00, 0xBF, 0x02, 0xE0, 0x00, 0xBF, 0x00, 0xE0, 0x00, 0xBF, 0xFB, 0x7D, 0x00, 0x2B,
		  0x0A, 0xD1, 0x61, 0x4B, 0x9B, 0x6D, 0x23, 0xF4, 0x60, 0x42, 0x7B, 0x68, 0xD3, 0xF8, 0xA4, 0x30,
		  0x5D, 0x49, 0x13, 0x43, 0x8B, 0x65, 0x01, 0xE0, 0xFB, 0x7D, 0xBB, 0x75, 0x7B, 0x68, 0x1B, 0x68,
		  0x03, 0xF0, 0x08, 0x03, 0x00, 0x2B, 0x1A, 0xD0, 0x7B, 0x68, 0xD3, 0xF8, 0x88, 0x30, 0xB3, 0xF5,
		  0x80, 0x5F, 0x0A, 0xD1, 0x7B, 0x68, 0x24, 0x33, 0x02, 0x21, 0x18, 0x46, 0x00, 0xF0, 0xFC, 0xFC,
		  0x03, 0x46, 0x00, 0x2B, 0x01, 0xD0, 0x01, 0x23, 0xBB, 0x75, 0x4F, 0x4B, 0x5B, 0x6D, 0x23, 0xF4,
		  0x40, 0x52, 0x7B, 0x68, 0xD3, 0xF8, 0x88, 0x30, 0x4B, 0x49, 0x13, 0x43, 0x4B, 0x65, 0x7B, 0x68,
		  0x1B, 0x68, 0x03, 0xF0, 0x10, 0x03, 0x00, 0x2B, 0x1A, 0xD0, 0x7B, 0x68, 0xD3, 0xF8, 0x9C, 0x30,
		  0xB3, 0xF5, 0x80, 0x7F, 0x0A, 0xD1, 0x7B, 0x68, 0x24, 0x33, 0x02, 0x21, 0x18, 0x46, 0x00, 0xF0,
		  0xDB, 0xFC, 0x03, 0x46, 0x00, 0x2B, 0x01, 0xD0, 0x01, 0x23, 0xBB, 0x75, 0x3E, 0x4B, 0x9B, 0x6D,
		  0x23, 0xF4, 0x40, 0x72, 0x7B, 0x68, 0xD3, 0xF8, 0x9C, 0x30, 0x3B, 0x49, 0x13, 0x43, 0x8B, 0x65,
		  0x7B, 0x68, 0x1B, 0x68, 0x03, 0xF4, 0x00, 0x23, 0x00, 0x2B, 0x34, 0xD0, 0x7B, 0x68, 0xD3, 0xF8,
		  0xA8, 0x30, 0xB3, 0xF5, 0x00, 0x3F, 0x1D, 0xD0, 0xB3, 0xF5, 0x00, 0x3F, 0x17, 0xD8, 0x00, 0x2B,
		  0x03, 0xD0, 0xB3, 0xF5, 0x80, 0x3F, 0x09, 0xD0, 0x11, 0xE0, 0x7B, 0x68, 0x04, 0x33, 0x00, 0x21,
		  0x18, 0x46, 0x00, 0xF0, 0xFF, 0xFB, 0x03, 0x46, 0xFB, 0x75, 0x0C, 0xE0, 0x7B, 0x68, 0x24, 0x33,
		  0x02, 0x21, 0x18, 0x46, 0x00, 0xF0, 0xA8, 0xFC, 0x03, 0x46, 0xFB, 0x75, 0x03, 0xE0, 0x01, 0x23,
		  0xFB, 0x75, 0x00, 0xE0, 0x00, 0xBF, 0xFB, 0x7D, 0x00, 0x2B, 0x0A, 0xD1, 0x22, 0x4B, 0x9B, 0x6D,
		  0x23, 0xF4, 0x40, 0x32, 0x7B, 0x68, 0xD3, 0xF8, 0xA8, 0x30, 0x1F, 0x49, 0x13, 0x43, 0x8B, 0x65,
		  0x01, 0xE0, 0xFB, 0x7D, 0xBB, 0x75, 0x7B, 0x68, 0x1B, 0x68, 0x03, 0xF4, 0x80, 0x23, 0x00, 0x2B,
		  0x36, 0xD0, 0x7B, 0x68, 0xD3, 0xF8, 0x8C, 0x30, 0xB3, 0xF5, 0x40, 0x1F, 0x1C, 0xD0, 0xB3, 0xF5,
		  0x40, 0x1F, 0x16, 0xD8, 0xB3, 0xF5, 0x80, 0x1F, 0x03, 0xD0, 0xB3, 0xF5, 0x00, 0x1F, 0x07, 0xD0,
		  0x0F, 0xE0, 0x11, 0x4B, 0xDB, 0x6A, 0x10, 0x4A, 0x43, 0xF4, 0x00, 0x33, 0xD3, 0x62, 0x0C, 0xE0,
		  0x7B, 0x68, 0x24, 0x33, 0x01, 0x21, 0x18, 0x46, 0x00, 0xF0, 0x6E, 0xFC, 0x03, 0x46, 0xFB, 0x75,
		  0x03, 0xE0, 0x01, 0x23, 0xFB, 0x75, 0x00, 0xE0, 0x00, 0xBF, 0xFB, 0x7D, 0x00, 0x2B, 0x0D, 0xD1,
		  0x05, 0x4B, 0x5B, 0x6D, 0x23, 0xF4, 0x40, 0x12, 0x7B, 0x68, 0xD3, 0xF8, 0x8C, 0x30, 0x02, 0x49,
		  0x13, 0x43, 0x4B, 0x65, 0x04, 0xE0, 0x00, 0xBF, 0x00, 0x44, 0x02, 0x58, 0xFB, 0x7D, 0xBB, 0x75,
		  0x7B, 0x68, 0x1B, 0x68, 0x03, 0xF4, 0x80, 0x33, 0x00, 0x2B, 0x29, 0xD0, 0x7B, 0x68, 0xDB, 0x6C,
		  0x00, 0x2B, 0x03, 0xD0, 0xB3, 0xF5, 0x80, 0x3F, 0x07, 0xD0, 0x0F, 0xE0, 0x69, 0x4B, 0xDB, 0x6A,
		  0x68, 0x4A, 0x43, 0xF4, 0x00, 0x33, 0xD3, 0x62, 0x0B, 0xE0, 0x7B, 0x68, 0x04, 0x33, 0x02, 0x21,
		  0x18, 0x46, 0x00, 0xF0, 0x87, 0xFB, 0x03, 0x46, 0xFB, 0x75, 0x02, 0xE0, 0x01, 0x23, 0xFB, 0x75,
		  0x00, 0xBF, 0xFB, 0x7D, 0x00, 0x2B, 0x09, 0xD1, 0x5E, 0x4B, 0xDB, 0x6C, 0x23, 0xF4, 0x80, 0x32,
		  0x7B, 0x68, 0xDB, 0x6C, 0x5B, 0x49, 0x13, 0x43, 0xCB, 0x64, 0x01, 0xE0, 0xFB, 0x7D, 0xBB, 0x75,
		  0x7B, 0x68, 0x1B, 0x68, 0x03, 0xF0, 0x00, 0x53, 0x00, 0x2B, 0x0A, 0xD0, 0x7B, 0x68, 0x24, 0x33,
		  0x02, 0x21, 0x18, 0x46, 0x00, 0xF0, 0x18, 0xFC, 0x03, 0x46, 0x00, 0x2B, 0x01, 0xD0, 0x01, 0x23,
		  0xBB, 0x75, 0x7B, 0x68, 0x1B, 0x68, 0x03, 0xF4, 0x00, 0x33, 0x00, 0x2B, 0x32, 0xD0, 0x7B, 0x68,
		  0xD3, 0xF8, 0x84, 0x30, 0xB3, 0xF5, 0x40, 0x7F, 0x17, 0xD0, 0xB3, 0xF5, 0x40, 0x7F, 0x11, 0xD8,
		  0xB3, 0xF5, 0x00, 0x7F, 0x13, 0xD0, 0xB3, 0xF5, 0x00, 0x7F, 0x0B, 0xD8, 0x00, 0x2B, 0x10, 0xD0,
		  0xB3, 0xF5, 0x80, 0x7F, 0x06, 0xD1, 0x43, 0x4B, 0xDB, 0x6A, 0x42, 0x4A, 0x43, 0xF4, 0x00, 0x33,
		  0xD3, 0x62, 0x07, 0xE0, 0x01, 0x23, 0xFB, 0x75, 0x04, 0xE0, 0x00, 0xBF, 0x02, 0xE0, 0x00, 0xBF,
		  0x00, 0xE0, 0x00, 0xBF, 0xFB, 0x7D, 0x00, 0x2B, 0x0A, 0xD1, 0x3A, 0x4B, 0x5B, 0x6D, 0x23, 0xF4,
		  0x40, 0x72, 0x7B, 0x68, 0xD3, 0xF8, 0x84, 0x30, 0x36, 0x49, 0x13, 0x43, 0x4B, 0x65, 0x01, 0xE0,
		  0xFB, 0x7D, 0xBB, 0x75, 0x7B, 0x68, 0x1B, 0x68, 0x03, 0xF4, 0x80, 0x13, 0x00, 0x2B, 0x08, 0xD0,
		  0x30, 0x4B, 0x1B, 0x6D, 0x23, 0xF0, 0x00, 0x42, 0x7B, 0x68, 0x9B, 0x6F, 0x2D, 0x49, 0x13, 0x43,
		  0x0B, 0x65, 0x7B, 0x68, 0x1B, 0x68, 0x03, 0xF4, 0x00, 0x13, 0x00, 0x2B, 0x08, 0xD0, 0x29, 0x4B,
		  0x1B, 0x6D, 0x23, 0xF0, 0x80, 0x72, 0x7B, 0x68, 0xDB, 0x6E, 0x26, 0x49, 0x13, 0x43, 0x0B, 0x65,
		  0x7B, 0x68, 0x1B, 0x68, 0x03, 0xF4, 0x00, 0x63, 0x00, 0x2B, 0x08, 0xD0, 0x21, 0x4B, 0x9B, 0x6D,
		  0x23, 0xF0, 0x00, 0x62, 0x7B, 0x68, 0x1B, 0x6F, 0x1E, 0x49, 0x13, 0x43, 0x8B, 0x65, 0x7B, 0x68,
		  0x1B, 0x68, 0x03, 0xF0, 0x80, 0x43, 0x00, 0x2B, 0x0D, 0xD0, 0x1A, 0x4B, 0x1B, 0x69, 0x19, 0x4A,
		  0x23, 0xF4, 0x00, 0x43, 0x13, 0x61, 0x17, 0x4B, 0x1A, 0x69, 0x7B, 0x68, 0xD3, 0xF8, 0xB4, 0x30,
		  0x14, 0x49, 0x13, 0x43, 0x0B, 0x61, 0x7B, 0x68, 0x1B, 0x68, 0x00, 0x2B, 0x08, 0xDA, 0x11, 0x4B,
		  0xDB, 0x6C, 0x23, 0xF0, 0x40, 0x52, 0x7B, 0x68, 0x1B, 0x6D, 0x0E, 0x49, 0x13, 0x43, 0xCB, 0x64,
		  0x7B, 0x68, 0x1B, 0x68, 0x03, 0xF4, 0x00, 0x03, 0x00, 0x2B, 0x09, 0xD0, 0x09, 0x4B, 0x5B, 0x6D,
		  0x23, 0xF4, 0x40, 0x02, 0x7B, 0x68, 0xD3, 0xF8, 0x90, 0x30, 0x06, 0x49, 0x13, 0x43, 0x4B, 0x65,
		  0xBB, 0x7D, 0x00, 0x2B, 0x01, 0xD1, 0x00, 0x23, 0x00, 0xE0, 0x01, 0x23, 0x18, 0x46, 0x18, 0x37,
		  0xBD, 0x46, 0x80, 0xBD, 0x00, 0x44, 0x02, 0x58, 0x80, 0xB5, 0x00, 0xAF, 0xFF, 0xF7, 0x94, 0xF8,
		  0x02, 0x46, 0x06, 0x4B, 0x1B, 0x6A, 0x1B, 0x09, 0x03, 0xF0, 0x07, 0x03, 0x04, 0x49, 0xCB, 0x5C,
		  0x03, 0xF0, 0x1F, 0x03, 0x22, 0xFA, 0x03, 0xF3, 0x18, 0x46, 0x80, 0xBD, 0x00, 0x44, 0x02, 0x58,
		  0xD8, 0x4C, 0x00, 0x08, 0x80, 0xB4, 0x89, 0xB0, 0x00, 0xAF, 0x78, 0x60, 0xA1, 0x4B, 0x9B, 0x6A,
		  0x03, 0xF0, 0x03, 0x03, 0xBB, 0x61, 0x9F, 0x4B, 0x9B, 0x6A, 0x1B, 0x0B, 0x03, 0xF0, 0x3F, 0x03,
		  0x7B, 0x61, 0x9C, 0x4B, 0xDB, 0x6A, 0x1B, 0x09, 0x03, 0xF0, 0x01, 0x03, 0x3B, 0x61, 0x99, 0x4B,
		  0xDB, 0x6B, 0xDB, 0x08, 0xC3, 0xF3, 0x0C, 0x03, 0x3A, 0x69, 0x02, 0xFB, 0x03, 0xF3, 0x07, 0xEE,
		  0x90, 0x3A, 0xF8, 0xEE, 0x67, 0x7A, 0xC7, 0xED, 0x03, 0x7A, 0x7B, 0x69, 0x00, 0x2B, 0x00, 0xF0,
		  0x11, 0x81, 0xBB, 0x69, 0x02, 0x2B, 0x00, 0xF0, 0x83, 0x80, 0xBB, 0x69, 0x02, 0x2B, 0x00, 0xF2,
		  0xA1, 0x80, 0xBB, 0x69, 0x00, 0x2B, 0x03, 0xD0, 0xBB, 0x69, 0x01, 0x2B, 0x56, 0xD0, 0x99, 0xE0,
		  0x88, 0x4B, 0x1B, 0x68, 0x03, 0xF0, 0x20, 0x03, 0x00, 0x2B, 0x2D, 0xD0, 0x85, 0x4B, 0x1B, 0x68,
		  0xDB, 0x08, 0x03, 0xF0, 0x03, 0x03, 0x84, 0x4A, 0x22, 0xFA, 0x03, 0xF3, 0xBB, 0x60, 0xBB, 0x68,
		  0x07, 0xEE, 0x90, 0x3A, 0xF8, 0xEE, 0x67, 0x6A, 0x7B, 0x69, 0x07, 0xEE, 0x90, 0x3A, 0xF8, 0xEE,
		  0x67, 0x7A, 0x86, 0xEE, 0xA7, 0x7A, 0x7B, 0x4B, 0x9B, 0x6B, 0xC3, 0xF3, 0x08, 0x03, 0x07, 0xEE,
		  0x90, 0x3A, 0xF8, 0xEE, 0x67, 0x6A, 0x97, 0xED, 0x03, 0x6A, 0xDF, 0xED, 0x78, 0x5A, 0xC6, 0xEE,
		  0x25, 0x7A, 0x76, 0xEE, 0xA7, 0x7A, 0xF7, 0xEE, 0x00, 0x6A, 0x77, 0xEE, 0xA6, 0x7A, 0x67, 0xEE,
		  0x27, 0x7A, 0xC7, 0xED, 0x07, 0x7A, 0x87, 0xE0, 0x7B, 0x69, 0x07, 0xEE, 0x90, 0x3A, 0xF8, 0xEE,
		  0x67, 0x7A, 0xDF, 0xED, 0x6F, 0x6A, 0x86, 0xEE, 0xA7, 0x7A, 0x6A, 0x4B, 0x9B, 0x6B, 0xC3, 0xF3,
		  0x08, 0x03, 0x07, 0xEE, 0x90, 0x3A, 0xF8, 0xEE, 0x67, 0x6A, 0x97, 0xED, 0x03, 0x6A, 0xDF, 0xED,
		  0x67, 0x5A, 0xC6, 0xEE, 0x25, 0x7A, 0x76, 0xEE, 0xA7, 0x7A, 0xF7, 0xEE, 0x00, 0x6A, 0x77, 0xEE,
		  0xA6, 0x7A, 0x67, 0xEE, 0x27, 0x7A, 0xC7, 0xED, 0x07, 0x7A, 0x65, 0xE0, 0x7B, 0x69, 0x07, 0xEE,
		  0x90, 0x3A, 0xF8, 0xEE, 0x67, 0x7A, 0xDF, 0xED, 0x5F, 0x6A, 0x86, 0xEE, 0xA7, 0x7A, 0x59, 0x4B,
		  0x9B, 0x6B, 0xC3, 0xF3, 0x08, 0x03, 0x07, 0xEE, 0x90, 0x3A, 0xF8, 0xEE, 0x67, 0x6A, 0x97, 0xED,
		  0x03, 0x6A, 0xDF, 0xED, 0x56, 0x5A, 0xC6, 0xEE, 0x25, 0x7A, 0x76, 0xEE, 0xA7, 0x7A, 0xF7, 0xEE,
		  0x00, 0x6A, 0x77, 0xEE, 0xA6, 0x7A, 0x67, 0xEE, 0x27, 0x7A, 0xC7, 0xED, 0x07, 0x7A, 0x43, 0xE0,
		  0x7B, 0x69, 0x07, 0xEE, 0x90, 0x3A, 0xF8, 0xEE, 0x67, 0x7A, 0xDF, 0xED, 0x4F, 0x6A, 0x86, 0xEE,
		  0xA7, 0x7A, 0x48, 0x4B, 0x9B, 0x6B, 0xC3, 0xF3, 0x08, 0x03, 0x07, 0xEE, 0x90, 0x3A, 0xF8, 0xEE,
		  0x67, 0x6A, 0x97, 0xED, 0x03, 0x6A, 0xDF, 0xED, 0x45, 0x5A, 0xC6, 0xEE, 0x25, 0x7A, 0x76, 0xEE,
		  0xA7, 0x7A, 0xF7, 0xEE, 0x00, 0x6A, 0x77, 0xEE, 0xA6, 0x7A, 0x67, 0xEE, 0x27, 0x7A, 0xC7, 0xED,
		  0x07, 0x7A, 0x21, 0xE0, 0x7B, 0x69, 0x07, 0xEE, 0x90, 0x3A, 0xF8, 0xEE, 0x67, 0x7A, 0xDF, 0xED,
		  0x3D, 0x6A, 0x86, 0xEE, 0xA7, 0x7A, 0x37, 0x4B, 0x9B, 0x6B, 0xC3, 0xF3, 0x08, 0x03, 0x07, 0xEE,
		  0x90, 0x3A, 0xF8, 0xEE, 0x67, 0x6A, 0x97, 0xED, 0x03, 0x6A, 0xDF, 0xED, 0x34, 0x5A, 0xC6, 0xEE,
		  0x25, 0x7A, 0x76, 0xEE, 0xA7, 0x7A, 0xF7, 0xEE, 0x00, 0x6A, 0x77, 0xEE, 0xA6, 0x7A, 0x67, 0xEE,
		  0x27, 0x7A, 0xC7, 0xED, 0x07, 0x7A, 0x00, 0xBF, 0x2A, 0x4B, 0x9B, 0x6B, 0x5B, 0x0A, 0x03, 0xF0,
		  0x7F, 0x03, 0x07, 0xEE, 0x90, 0x3A, 0xF8, 0xEE, 0x67, 0x7A, 0xB7, 0xEE, 0x00, 0x7A, 0x37, 0xEE,
		  0x87, 0x7A, 0xD7, 0xED, 0x07, 0x6A, 0xC6, 0xEE, 0x87, 0x7A, 0xFC, 0xEE, 0xE7, 0x7A, 0x17, 0xEE,
		  0x90, 0x2A, 0x7B, 0x68, 0x1A, 0x60, 0x1F, 0x4B, 0x9B, 0x6B, 0x1B, 0x0C, 0x03, 0xF0, 0x7F, 0x03,
		  0x07, 0xEE, 0x90, 0x3A, 0xF8, 0xEE, 0x67, 0x7A, 0xB7, 0xEE, 0x00, 0x7A, 0x37, 0xEE, 0x87, 0x7A,
		  0xD7, 0xED, 0x07, 0x6A, 0xC6, 0xEE, 0x87, 0x7A, 0xFC, 0xEE, 0xE7, 0x7A, 0x17, 0xEE, 0x90, 0x2A,
		  0x7B, 0x68, 0x5A, 0x60, 0x13, 0x4B, 0x9B, 0x6B, 0x1B, 0x0E, 0x03, 0xF0, 0x7F, 0x03, 0x07, 0xEE,
		  0x90, 0x3A, 0xF8, 0xEE, 0x67, 0x7A, 0xB7, 0xEE, 0x00, 0x7A, 0x37, 0xEE, 0x87, 0x7A, 0xD7, 0xED,
		  0x07, 0x6A, 0xC6, 0xEE, 0x87, 0x7A, 0xFC, 0xEE, 0xE7, 0x7A, 0x17, 0xEE, 0x90, 0x2A, 0x7B, 0x68,
		  0x9A, 0x60, 0x08, 0xE0, 0x7B, 0x68, 0x00, 0x22, 0x1A, 0x60, 0x7B, 0x68, 0x00, 0x22, 0x5A, 0x60,
		  0x7B, 0x68, 0x00, 0x22, 0x9A, 0x60, 0x00, 0xBF, 0x24, 0x37, 0xBD, 0x46, 0x5D, 0xF8, 0x04, 0x7B,
		  0x70, 0x47, 0x00, 0xBF, 0x00, 0x44, 0x02, 0x58, 0x00, 0x90, 0xD0, 0x03, 0x00, 0x00, 0x00, 0x46,
		  0x00, 0x24, 0x74, 0x4C, 0x00, 0x24, 0x74, 0x4A, 0x00, 0x24, 0xF4, 0x4A, 0x80, 0xB4, 0x89, 0xB0,
		  0x00, 0xAF, 0x78, 0x60, 0xA1, 0x4B, 0x9B, 0x6A, 0x03, 0xF0, 0x03, 0x03, 0xBB, 0x61, 0x9F, 0x4B,
		  0x9B, 0x6A, 0x1B, 0x0D, 0x03, 0xF0, 0x3F, 0x03, 0x7B, 0x61, 0x9C, 0x4B, 0xDB, 0x6A, 0x1B, 0x0A,
		  0x03, 0xF0, 0x01, 0x03, 0x3B, 0x61, 0x99, 0x4B, 0x5B, 0x6C, 0xDB, 0x08, 0xC3, 0xF3, 0x0C, 0x03,
		  0x3A, 0x69, 0x02, 0xFB, 0x03, 0xF3, 0x07, 0xEE, 0x90, 0x3A, 0xF8, 0xEE, 0x67, 0x7A, 0xC7, 0xED,
		  0x03, 0x7A, 0x7B, 0x69, 0x00, 0x2B, 0x00, 0xF0, 0x11, 0x81, 0xBB, 0x69, 0x02, 0x2B, 0x00, 0xF0,
		  0x83, 0x80, 0xBB, 0x69, 0x02, 0x2B, 0x00, 0xF2, 0xA1, 0x80, 0xBB, 0x69, 0x00, 0x2B, 0x03, 0xD0,
		  0xBB, 0x69, 0x01, 0x2B, 0x56, 0xD0, 0x99, 0xE0, 0x88, 0x4B, 0x1B, 0x68, 0x03, 0xF0, 0x20, 0x03,
		  0x00, 0x2B, 0x2D, 0xD0, 0x85, 0x4B, 0x1B, 0x68, 0xDB, 0x08, 0x03, 0xF0, 0x03, 0x03, 0x84, 0x4A,
		  0x22, 0xFA, 0x03, 0xF3, 0xBB, 0x60, 0xBB, 0x68, 0x07, 0xEE, 0x90, 0x3A, 0xF8, 0xEE, 0x67, 0x6A,
		  0x7B, 0x69, 0x07, 0xEE, 0x90, 0x3A, 0xF8, 0xEE, 0x67, 0x7A, 0x86, 0xEE, 0xA7, 0x7A, 0x7B, 0x4B,
		  0x1B, 0x6C, 0xC3, 0xF3, 0x08, 0x03, 0x07, 0xEE, 0x90, 0x3A, 0xF8, 0xEE, 0x67, 0x6A, 0x97, 0xED,
		  0x03, 0x6A, 0xDF, 0xED, 0x78, 0x5A, 0xC6, 0xEE, 0x25, 0x7A, 0x76, 0xEE, 0xA7, 0x7A, 0xF7, 0xEE,
		  0x00, 0x6A, 0x77, 0xEE, 0xA6, 0x7A, 0x67, 0xEE, 0x27, 0x7A, 0xC7, 0xED, 0x07, 0x7A, 0x87, 0xE0,
		  0x7B, 0x69, 0x07, 0xEE, 0x90, 0x3A, 0xF8, 0xEE, 0x67, 0x7A, 0xDF, 0xED, 0x6F, 0x6A, 0x86, 0xEE,
		  0xA7, 0x7A, 0x6A, 0x4B, 0x1B, 0x6C, 0xC3, 0xF3, 0x08, 0x03, 0x07, 0xEE, 0x90, 0x3A, 0xF8, 0xEE,
		  0x67, 0x6A, 0x97, 0xED, 0x03, 0x6A, 0xDF, 0xED, 0x67, 0x5A, 0xC6, 0xEE, 0x25, 0x7A, 0x76, 0xEE,
		  0xA7, 0x7A, 0xF7, 0xEE, 0x00, 0x6A, 0x77, 0xEE, 0xA6, 0x7A, 0x67, 0xEE, 0x27, 0x7A, 0xC7, 0xED,
		  0x07, 0x7A, 0x65, 0xE0, 0x7B, 0x69, 0x07, 0xEE, 0x90, 0x3A, 0xF8, 0xEE, 0x67, 0x7A, 0xDF, 0xED,
		  0x5F, 0x6A, 0x86, 0xEE, 0xA7, 0x7A, 0x59, 0x4B, 0x1B, 0x6C, 0xC3, 0xF3, 0x08, 0x03, 0x07, 0xEE,
		  0x90, 0x3A, 0xF8, 0xEE, 0x67, 0x6A, 0x97, 0xED, 0x03, 0x6A, 0xDF, 0xED, 0x56, 0x5A, 0xC6, 0xEE,
		  0x25, 0x7A, 0x76, 0xEE, 0xA7, 0x7A, 0xF7, 0xEE, 0x00, 0x6A, 0x77, 0xEE, 0xA6, 0x7A, 0x67, 0xEE,
		  0x27, 0x7A, 0xC7, 0xED, 0x07, 0x7A, 0x43, 0xE0, 0x7B, 0x69, 0x07, 0xEE, 0x90, 0x3A, 0xF8, 0xEE,
		  0x67, 0x7A, 0xDF, 0xED, 0x4F, 0x6A, 0x86, 0xEE, 0xA7, 0x7A, 0x48, 0x4B, 0x1B, 0x6C, 0xC3, 0xF3,
		  0x08, 0x03, 0x07, 0xEE, 0x90, 0x3A, 0xF8, 0xEE, 0x67, 0x6A, 0x97, 0xED, 0x03, 0x6A, 0xDF, 0xED,
		  0x45, 0x5A, 0xC6, 0xEE, 0x25, 0x7A, 0x76, 0xEE, 0xA7, 0x7A, 0xF7, 0xEE, 0x00, 0x6A, 0x77, 0xEE,
		  0xA6, 0x7A, 0x67, 0xEE, 0x27, 0x7A, 0xC7, 0xED, 0x07, 0x7A, 0x21, 0xE0, 0x7B, 0x69, 0x07, 0xEE,
		  0x90, 0x3A, 0xF8, 0xEE, 0x67, 0x7A, 0xDF, 0xED, 0x3D, 0x6A, 0x86, 0xEE, 0xA7, 0x7A, 0x37, 0x4B,
		  0x1B, 0x6C, 0xC3, 0xF3, 0x08, 0x03, 0x07, 0xEE, 0x90, 0x3A, 0xF8, 0xEE, 0x67, 0x6A, 0x97, 0xED,
		  0x03, 0x6A, 0xDF, 0xED, 0x34, 0x5A, 0xC6, 0xEE, 0x25, 0x7A, 0x76, 0xEE, 0xA7, 0x7A, 0xF7, 0xEE,
		  0x00, 0x6A, 0x77, 0xEE, 0xA6, 0x7A, 0x67, 0xEE, 0x27, 0x7A, 0xC7, 0xED, 0x07, 0x7A, 0x00, 0xBF,
		  0x2A, 0x4B, 0x1B, 0x6C, 0x5B, 0x0A, 0x03, 0xF0, 0x7F, 0x03, 0x07, 0xEE, 0x90, 0x3A, 0xF8, 0xEE,
		  0x67, 0x7A, 0xB7, 0xEE, 0x00, 0x7A, 0x37, 0xEE, 0x87, 0x7A, 0xD7, 0xED, 0x07, 0x6A, 0xC6, 0xEE,
		  0x87, 0x7A, 0xFC, 0xEE, 0xE7, 0x7A, 0x17, 0xEE, 0x90, 0x2A, 0x7B, 0x68, 0x1A, 0x60, 0x1F, 0x4B,
		  0x1B, 0x6C, 0x1B, 0x0C, 0x03, 0xF0, 0x7F, 0x03, 0x07, 0xEE, 0x90, 0x3A, 0xF8, 0xEE, 0x67, 0x7A,
		  0xB7, 0xEE, 0x00, 0x7A, 0x37, 0xEE, 0x87, 0x7A, 0xD7, 0xED, 0x07, 0x6A, 0xC6, 0xEE, 0x87, 0x7A,
		  0xFC, 0xEE, 0xE7, 0x7A, 0x17, 0xEE, 0x90, 0x2A, 0x7B, 0x68, 0x5A, 0x60, 0x13, 0x4B, 0x1B, 0x6C,
		  0x1B, 0x0E, 0x03, 0xF0, 0x7F, 0x03, 0x07, 0xEE, 0x90, 0x3A, 0xF8, 0xEE, 0x67, 0x7A, 0xB7, 0xEE,
		  0x00, 0x7A, 0x37, 0xEE, 0x87, 0x7A, 0xD7, 0xED, 0x07, 0x6A, 0xC6, 0xEE, 0x87, 0x7A, 0xFC, 0xEE,
		  0xE7, 0x7A, 0x17, 0xEE, 0x90, 0x2A, 0x7B, 0x68, 0x9A, 0x60, 0x08, 0xE0, 0x7B, 0x68, 0x00, 0x22,
		  0x1A, 0x60, 0x7B, 0x68, 0x00, 0x22, 0x5A, 0x60, 0x7B, 0x68, 0x00, 0x22, 0x9A, 0x60, 0x00, 0xBF,
		  0x24, 0x37, 0xBD, 0x46, 0x5D, 0xF8, 0x04, 0x7B, 0x70, 0x47, 0x00, 0xBF, 0x00, 0x44, 0x02, 0x58,
		  0x00, 0x90, 0xD0, 0x03, 0x00, 0x00, 0x00, 0x46, 0x00, 0x24, 0x74, 0x4C, 0x00, 0x24, 0x74, 0x4A,
		  0x00, 0x24, 0xF4, 0x4A, 0x80, 0xB5, 0x84, 0xB0, 0x00, 0xAF, 0x78, 0x60, 0x39, 0x60, 0x00, 0x23,
		  0xFB, 0x73, 0x53, 0x4B, 0x9B, 0x6A, 0x03, 0xF0, 0x03, 0x03, 0x03, 0x2B, 0x01, 0xD1, 0x01, 0x23,
		  0x99, 0xE0, 0x4F, 0x4B, 0x1B, 0x68, 0x4E, 0x4A, 0x23, 0xF0, 0x80, 0x63, 0x13, 0x60, 0xFD, 0xF7,
		  0x3D, 0xFB, 0xB8, 0x60, 0x08, 0xE0, 0xFD, 0xF7, 0x39, 0xFB, 0x02, 0x46, 0xBB, 0x68, 0xD3, 0x1A,
		  0x02, 0x2B, 0x01, 0xD9, 0x03, 0x23, 0x86, 0xE0, 0x45, 0x4B, 0x1B, 0x68, 0x03, 0xF0, 0x00, 0x63,
		  0x00, 0x2B, 0xF0, 0xD1, 0x42, 0x4B, 0x9B, 0x6A, 0x23, 0xF4, 0x7C, 0x32, 0x7B, 0x68, 0x1B, 0x68,
		  0x1B, 0x03, 0x3F, 0x49, 0x13, 0x43, 0x8B, 0x62, 0x7B, 0x68, 0x5B, 0x68, 0x01, 0x3B, 0xC3, 0xF3,
		  0x08, 0x02, 0x7B, 0x68, 0x9B, 0x68, 0x01, 0x3B, 0x5B, 0x02, 0x9B, 0xB2, 0x1A, 0x43, 0x7B, 0x68,
		  0xDB, 0x68, 0x01, 0x3B, 0x1B, 0x04, 0x03, 0xF4, 0xFE, 0x03, 0x1A, 0x43, 0x7B, 0x68, 0x1B, 0x69,
		  0x01, 0x3B, 0x1B, 0x06, 0x03, 0xF0, 0xFE, 0x43, 0x31, 0x49, 0x13, 0x43, 0x8B, 0x63, 0x30, 0x4B,
		  0xDB, 0x6A, 0x23, 0xF0, 0xC0, 0x02, 0x7B, 0x68, 0x5B, 0x69, 0x2D, 0x49, 0x13, 0x43, 0xCB, 0x62,
		  0x2B, 0x4B, 0xDB, 0x6A, 0x23, 0xF0, 0x20, 0x02, 0x7B, 0x68, 0x9B, 0x69, 0x28, 0x49, 0x13, 0x43,
		  0xCB, 0x62, 0x27, 0x4B, 0xDB, 0x6A, 0x26, 0x4A, 0x23, 0xF0, 0x10, 0x03, 0xD3, 0x62, 0x24, 0x4B,
		  0xDA, 0x6B, 0x24, 0x4B, 0x13, 0x40, 0x7A, 0x68, 0xD2, 0x69, 0xD2, 0x00, 0x20, 0x49, 0x13, 0x43,
		  0xCB, 0x63, 0x1F, 0x4B, 0xDB, 0x6A, 0x1E, 0x4A, 0x43, 0xF0, 0x10, 0x03, 0xD3, 0x62, 0x3B, 0x68,
		  0x00, 0x2B, 0x06, 0xD1, 0x1A, 0x4B, 0xDB, 0x6A, 0x19, 0x4A, 0x43, 0xF4, 0x00, 0x23, 0xD3, 0x62,
		  0x0F, 0xE0, 0x3B, 0x68, 0x01, 0x2B, 0x06, 0xD1, 0x15, 0x4B, 0xDB, 0x6A, 0x14, 0x4A, 0x43, 0xF4,
		  0x80, 0x13, 0xD3, 0x62, 0x05, 0xE0, 0x12, 0x4B, 0xDB, 0x6A, 0x11, 0x4A, 0x43, 0xF4, 0x00, 0x13,
		  0xD3, 0x62, 0x0F, 0x4B, 0x1B, 0x68, 0x0E, 0x4A, 0x43, 0xF0, 0x80, 0x63, 0x13, 0x60, 0xFD, 0xF7,
		  0xBD, 0xFA, 0xB8, 0x60, 0x08, 0xE0, 0xFD, 0xF7, 0xB9, 0xFA, 0x02, 0x46, 0xBB, 0x68, 0xD3, 0x1A,
		  0x02, 0x2B, 0x01, 0xD9, 0x03, 0x23, 0x06, 0xE0, 0x05, 0x4B, 0x1B, 0x68, 0x03, 0xF0, 0x00, 0x63,
		  0x00, 0x2B, 0xF0, 0xD0, 0xFB, 0x7B, 0x18, 0x46, 0x10, 0x37, 0xBD, 0x46, 0x80, 0xBD, 0x00, 0xBF,
		  0x00, 0x44, 0x02, 0x58, 0x07, 0x00, 0xFF, 0xFF, 0x80, 0xB5, 0x84, 0xB0, 0x00, 0xAF, 0x78, 0x60,
		  0x39, 0x60, 0x00, 0x23, 0xFB, 0x73, 0x53, 0x4B, 0x9B, 0x6A, 0x03, 0xF0, 0x03, 0x03, 0x03, 0x2B,
		  0x01, 0xD1, 0x01, 0x23, 0x99, 0xE0, 0x4F, 0x4B, 0x1B, 0x68, 0x4E, 0x4A, 0x23, 0xF0, 0x80, 0x53,
		  0x13, 0x60, 0xFD, 0xF7, 0x8B, 0xFA, 0xB8, 0x60, 0x08, 0xE0, 0xFD, 0xF7, 0x87, 0xFA, 0x02, 0x46,
		  0xBB, 0x68, 0xD3, 0x1A, 0x02, 0x2B, 0x01, 0xD9, 0x03, 0x23, 0x86, 0xE0, 0x45, 0x4B, 0x1B, 0x68,
		  0x03, 0xF0, 0x00, 0x53, 0x00, 0x2B, 0xF0, 0xD1, 0x42, 0x4B, 0x9B, 0x6A, 0x23, 0xF0, 0x7C, 0x72,
		  0x7B, 0x68, 0x1B, 0x68, 0x1B, 0x05, 0x3F, 0x49, 0x13, 0x43, 0x8B, 0x62, 0x7B, 0x68, 0x5B, 0x68,
		  0x01, 0x3B, 0xC3, 0xF3, 0x08, 0x02, 0x7B, 0x68, 0x9B, 0x68, 0x01, 0x3B, 0x5B, 0x02, 0x9B, 0xB2,
		  0x1A, 0x43, 0x7B, 0x68, 0xDB, 0x68, 0x01, 0x3B, 0x1B, 0x04, 0x03, 0xF4, 0xFE, 0x03, 0x1A, 0x43,
		  0x7B, 0x68, 0x1B, 0x69, 0x01, 0x3B, 0x1B, 0x06, 0x03, 0xF0, 0xFE, 0x43, 0x31, 0x49, 0x13, 0x43,
		  0x0B, 0x64, 0x30, 0x4B, 0xDB, 0x6A, 0x23, 0xF4, 0x40, 0x62, 0x7B, 0x68, 0x5B, 0x69, 0x2D, 0x49,
		  0x13, 0x43, 0xCB, 0x62, 0x2B, 0x4B, 0xDB, 0x6A, 0x23, 0xF4, 0x00, 0x72, 0x7B, 0x68, 0x9B, 0x69,
		  0x28, 0x49, 0x13, 0x43, 0xCB, 0x62, 0x27, 0x4B, 0xDB, 0x6A, 0x26, 0x4A, 0x23, 0xF4, 0x80, 0x73,
		  0xD3, 0x62, 0x24, 0x4B, 0x5A, 0x6C, 0x24, 0x4B, 0x13, 0x40, 0x7A, 0x68, 0xD2, 0x69, 0xD2, 0x00,
		  0x20, 0x49, 0x13, 0x43, 0x4B, 0x64, 0x1F, 0x4B, 0xDB, 0x6A, 0x1E, 0x4A, 0x43, 0xF4, 0x80, 0x73,
		  0xD3, 0x62, 0x3B, 0x68, 0x00, 0x2B, 0x06, 0xD1, 0x1A, 0x4B, 0xDB, 0x6A, 0x19, 0x4A, 0x43, 0xF4,
		  0x80, 0x03, 0xD3, 0x62, 0x0F, 0xE0, 0x3B, 0x68, 0x01, 0x2B, 0x06, 0xD1, 0x15, 0x4B, 0xDB, 0x6A,
		  0x14, 0x4A, 0x43, 0xF4, 0x00, 0x03, 0xD3, 0x62, 0x05, 0xE0, 0x12, 0x4B, 0xDB, 0x6A, 0x11, 0x4A,
		  0x43, 0xF0, 0x80, 0x73, 0xD3, 0x62, 0x0F, 0x4B, 0x1B, 0x68, 0x0E, 0x4A, 0x43, 0xF0, 0x80, 0x53,
		  0x13, 0x60, 0xFD, 0xF7, 0x0B, 0xFA, 0xB8, 0x60, 0x08, 0xE0, 0xFD, 0xF7, 0x07, 0xFA, 0x02, 0x46,
		  0xBB, 0x68, 0xD3, 0x1A, 0x02, 0x2B, 0x01, 0xD9, 0x03, 0x23, 0x06, 0xE0, 0x05, 0x4B, 0x1B, 0x68,
		  0x03, 0xF0, 0x00, 0x53, 0x00, 0x2B, 0xF0, 0xD0, 0xFB, 0x7B, 0x18, 0x46, 0x10, 0x37, 0xBD, 0x46,
		  0x80, 0xBD, 0x00, 0xBF, 0x00, 0x44, 0x02, 0x58, 0x07, 0x00, 0xFF, 0xFF, 0x80, 0xB5, 0x82, 0xB0,
		  0x00, 0xAF, 0x78, 0x60, 0x7B, 0x68, 0x00, 0x2B, 0x01, 0xD1, 0x01, 0x23, 0x42, 0xE0, 0x7B, 0x68,
		  0xD3, 0xF8, 0x84, 0x30, 0x00, 0x2B, 0x06, 0xD1, 0x7B, 0x68, 0x00, 0x22, 0x83, 0xF8, 0x80, 0x20,
		  0x78, 0x68, 0xFD, 0xF7, 0x25, 0xF8, 0x7B, 0x68, 0x24, 0x22, 0xC3, 0xF8, 0x84, 0x20, 0x7B, 0x68,
		  0x1B, 0x68, 0x1A, 0x68, 0x7B, 0x68, 0x1B, 0x68, 0x22, 0xF0, 0x01, 0x02, 0x1A, 0x60, 0x78, 0x68,
		  0x00, 0xF0, 0x2C, 0xF8, 0x03, 0x46, 0x01, 0x2B, 0x01, 0xD1, 0x01, 0x23, 0x22, 0xE0, 0x7B, 0x68,
		  0x9B, 0x6A, 0x00, 0x2B, 0x02, 0xD0, 0x78, 0x68, 0x00, 0xF0, 0x7E, 0xFE, 0x7B, 0x68, 0x1B, 0x68,
		  0x5A, 0x68, 0x7B, 0x68, 0x1B, 0x68, 0x22, 0xF4, 0x90, 0x42, 0x5A, 0x60, 0x7B, 0x68, 0x1B, 0x68,
		  0x9A, 0x68, 0x7B, 0x68, 0x1B, 0x68, 0x22, 0xF0, 0x2A, 0x02, 0x9A, 0x60, 0x7B, 0x68, 0x1B, 0x68,
		  0x1A, 0x68, 0x7B, 0x68, 0x1B, 0x68, 0x42, 0xF0, 0x01, 0x02, 0x1A, 0x60, 0x78, 0x68, 0x00, 0xF0,
		  0x05, 0xFF, 0x03, 0x46, 0x18, 0x46, 0x08, 0x37, 0xBD, 0x46, 0x80, 0xBD, 0xB0, 0xB5, 0x8E, 0xB0,
		  0x00, 0xAF, 0x78, 0x60, 0x00, 0x23, 0x87, 0xF8, 0x32, 0x30, 0x7B, 0x68, 0x9A, 0x68, 0x7B, 0x68,
		  0x1B, 0x69, 0x1A, 0x43, 0x7B, 0x68, 0x5B, 0x69, 0x1A, 0x43, 0x7B, 0x68, 0xDB, 0x69, 0x13, 0x43,
		  0x7B, 0x63, 0x7B, 0x68, 0x1B, 0x68, 0x1A, 0x68, 0xBF, 0x4B, 0x13, 0x40, 0x7A, 0x68, 0x12, 0x68,
		  0x79, 0x6B, 0x0B, 0x43, 0x13, 0x60, 0x7B, 0x68, 0x1B, 0x68, 0x5B, 0x68, 0x23, 0xF4, 0x40, 0x51,
		  0x7B, 0x68, 0xDA, 0x68, 0x7B, 0x68, 0x1B, 0x68, 0x0A, 0x43, 0x5A, 0x60, 0x7B, 0x68, 0x9B, 0x69,
		  0x7B, 0x63, 0x7B, 0x68, 0x1B, 0x68, 0xB5, 0x4A, 0x93, 0x42, 0x04, 0xD0, 0x7B, 0x68, 0x1B, 0x6A,
		  0x7A, 0x6B, 0x13, 0x43, 0x7B, 0x63, 0x7B, 0x68, 0x1B, 0x68, 0x9A, 0x68, 0xB0, 0x4B, 0x13, 0x40,
		  0x7A, 0x68, 0x12, 0x68, 0x79, 0x6B, 0x0B, 0x43, 0x93, 0x60, 0x7B, 0x68, 0x1B, 0x68, 0xDB, 0x6A,
		  0x23, 0xF0, 0x0F, 0x01, 0x7B, 0x68, 0x5A, 0x6A, 0x7B, 0x68, 0x1B, 0x68, 0x0A, 0x43, 0xDA, 0x62,
		  0x7B, 0x68, 0x1B, 0x68, 0xA7, 0x4A, 0x93, 0x42, 0x76, 0xD1, 0xA7, 0x4B, 0x5B, 0x6D, 0x03, 0xF0,
		  0x38, 0x03, 0x28, 0x2B, 0x6C, 0xD8, 0x01, 0xA2, 0x52, 0xF8, 0x23, 0xF0, 0x91, 0x3B, 0x00, 0x08,
		  0xC1, 0x3B, 0x00, 0x08, 0xC1, 0x3B, 0x00, 0x08, 0xC1, 0x3B, 0x00, 0x08, 0xC1, 0x3B, 0x00, 0x08,
		  0xC1, 0x3B, 0x00, 0x08, 0xC1, 0x3B, 0x00, 0x08, 0xC1, 0x3B, 0x00, 0x08, 0x99, 0x3B, 0x00, 0x08,
		  0xC1, 0x3B, 0x00, 0x08, 0xC1, 0x3B, 0x00, 0x08, 0xC1, 0x3B, 0x00, 0x08, 0xC1, 0x3B, 0x00, 0x08,
		  0xC1, 0x3B, 0x00, 0x08, 0xC1, 0x3B, 0x00, 0x08, 0xC1, 0x3B, 0x00, 0x08, 0xA1, 0x3B, 0x00, 0x08,
		  0xC1, 0x3B, 0x00, 0x08, 0xC1, 0x3B, 0x00, 0x08, 0xC1, 0x3B, 0x00, 0x08, 0xC1, 0x3B, 0x00, 0x08,
		  0xC1, 0x3B, 0x00, 0x08, 0xC1, 0x3B, 0x00, 0x08, 0xC1, 0x3B, 0x00, 0x08, 0xA9, 0x3B, 0x00, 0x08,
		  0xC1, 0x3B, 0x00, 0x08, 0xC1, 0x3B, 0x00, 0x08, 0xC1, 0x3B, 0x00, 0x08, 0xC1, 0x3B, 0x00, 0x08,
		  0xC1, 0x3B, 0x00, 0x08, 0xC1, 0x3B, 0x00, 0x08, 0xC1, 0x3B, 0x00, 0x08, 0xB1, 0x3B, 0x00, 0x08,
		  0xC1, 0x3B, 0x00, 0x08, 0xC1, 0x3B, 0x00, 0x08, 0xC1, 0x3B, 0x00, 0x08, 0xC1, 0x3B, 0x00, 0x08,
		  0xC1, 0x3B, 0x00, 0x08, 0xC1, 0x3B, 0x00, 0x08, 0xC1, 0x3B, 0x00, 0x08, 0xB9, 0x3B, 0x00, 0x08,
		  0x01, 0x23, 0x87, 0xF8, 0x33, 0x30, 0x26, 0xE3, 0x04, 0x23, 0x87, 0xF8, 0x33, 0x30, 0x22, 0xE3,
		  0x08, 0x23, 0x87, 0xF8, 0x33, 0x30, 0x1E, 0xE3, 0x10, 0x23, 0x87, 0xF8, 0x33, 0x30, 0x1A, 0xE3,
		  0x20, 0x23, 0x87, 0xF8, 0x33, 0x30, 0x16, 0xE3, 0x40, 0x23, 0x87, 0xF8, 0x33, 0x30, 0x12, 0xE3,
		  0x80, 0x23, 0x87, 0xF8, 0x33, 0x30, 0x0E, 0xE3, 0x7B, 0x68, 0x1B, 0x68, 0x6B, 0x4A, 0x93, 0x42,
		  0x30, 0xD1, 0x69, 0x4B, 0x5B, 0x6D, 0x03, 0xF0, 0x07, 0x03, 0x05, 0x2B, 0x26, 0xD8, 0x01, 0xA2,
		  0x52, 0xF8, 0x23, 0xF0, 0xFD, 0x3B, 0x00, 0x08, 0x05, 0x3C, 0x00, 0x08, 0x0D, 0x3C, 0x00, 0x08,
		  0x15, 0x3C, 0x00, 0x08, 0x1D, 0x3C, 0x00, 0x08, 0x25, 0x3C, 0x00, 0x08, 0x00, 0x23, 0x87, 0xF8,
		  0x33, 0x30, 0xF0, 0xE2, 0x04, 0x23, 0x87, 0xF8, 0x33, 0x30, 0xEC, 0xE2, 0x08, 0x23, 0x87, 0xF8,
		  0x33, 0x30, 0xE8, 0xE2, 0x10, 0x23, 0x87, 0xF8, 0x33, 0x30, 0xE4, 0xE2, 0x20, 0x23, 0x87, 0xF8,
		  0x33, 0x30, 0xE0, 0xE2, 0x40, 0x23, 0x87, 0xF8, 0x33, 0x30, 0xDC, 0xE2, 0x80, 0x23, 0x87, 0xF8,
		  0x33, 0x30, 0xD8, 0xE2, 0x7B, 0x68, 0x1B, 0x68, 0x51, 0x4A, 0x93, 0x42, 0x30, 0xD1, 0x4E, 0x4B,
		  0x5B, 0x6D, 0x03, 0xF0, 0x07, 0x03, 0x05, 0x2B, 0x26, 0xD8, 0x01, 0xA2, 0x52, 0xF8, 0x23, 0xF0,
		  0x69, 0x3C, 0x00, 0x08, 0x71, 0x3C, 0x00, 0x08, 0x79, 0x3C, 0x00, 0x08, 0x81, 0x3C, 0x00, 0x08,
		  0x89, 0x3C, 0x00, 0x08, 0x91, 0x3C, 0x00, 0x08, 0x00, 0x23, 0x87, 0xF8, 0x33, 0x30, 0xBA, 0xE2,
		  0x04, 0x23, 0x87, 0xF8, 0x33, 0x30, 0xB6, 0xE2, 0x08, 0x23, 0x87, 0xF8, 0x33, 0x30, 0xB2, 0xE2,
		  0x10, 0x23, 0x87, 0xF8, 0x33, 0x30, 0xAE, 0xE2, 0x20, 0x23, 0x87, 0xF8, 0x33, 0x30, 0xAA, 0xE2,
		  0x40, 0x23, 0x87, 0xF8, 0x33, 0x30, 0xA6, 0xE2, 0x80, 0x23, 0x87, 0xF8, 0x33, 0x30, 0xA2, 0xE2,
		  0x7B, 0x68, 0x1B, 0x68, 0x37, 0x4A, 0x93, 0x42, 0x30, 0xD1, 0x33, 0x4B, 0x5B, 0x6D, 0x03, 0xF0,
		  0x07, 0x03, 0x05, 0x2B, 0x26, 0xD8, 0x01, 0xA2, 0x52, 0xF8, 0x23, 0xF0, 0xD5, 0x3C, 0x00, 0x08,
		  0xDD, 0x3C, 0x00, 0x08, 0xE5, 0x3C, 0x00, 0x08, 0xED, 0x3C, 0x00, 0x08, 0xF5, 0x3C, 0x00, 0x08,
		  0xFD, 0x3C, 0x00, 0x08, 0x00, 0x23, 0x87, 0xF8, 0x33, 0x30, 0x84, 0xE2, 0x04, 0x23, 0x87, 0xF8,
		  0x33, 0x30, 0x80, 0xE2, 0x08, 0x23, 0x87, 0xF8, 0x33, 0x30, 0x7C, 0xE2, 0x10, 0x23, 0x87, 0xF8,
		  0x33, 0x30, 0x78, 0xE2, 0x20, 0x23, 0x87, 0xF8, 0x33, 0x30, 0x74, 0xE2, 0x40, 0x23, 0x87, 0xF8,
		  0x33, 0x30, 0x70, 0xE2, 0x80, 0x23, 0x87, 0xF8, 0x33, 0x30, 0x6C, 0xE2, 0x7B, 0x68, 0x1B, 0x68,
		  0x1D, 0x4A, 0x93, 0x42, 0x42, 0xD1, 0x18, 0x4B, 0x5B, 0x6D, 0x03, 0xF0, 0x07, 0x03, 0x05, 0x2B,
		  0x38, 0xD8, 0x01, 0xA2, 0x52, 0xF8, 0x23, 0xF0, 0x41, 0x3D, 0x00, 0x08, 0x49, 0x3D, 0x00, 0x08,
		  0x51, 0x3D, 0x00, 0x08, 0x59, 0x3D, 0x00, 0x08, 0x61, 0x3D, 0x00, 0x08, 0x8D, 0x3D, 0x00, 0x08,
		  0x00, 0x23, 0x87, 0xF8, 0x33, 0x30, 0x4E, 0xE2, 0x04, 0x23, 0x87, 0xF8, 0x33, 0x30, 0x4A, 0xE2,
		  0x08, 0x23, 0x87, 0xF8, 0x33, 0x30, 0x46, 0xE2, 0x10, 0x23, 0x87, 0xF8, 0x33, 0x30, 0x42, 0xE2,
		  0x20, 0x23, 0x87, 0xF8, 0x33, 0x30, 0x3E, 0xE2, 0xF3, 0x69, 0xFF, 0xCF, 0x00, 0x0C, 0x00, 0x58,
		  0xFF, 0xF4, 0xFF, 0x11, 0x00, 0x10, 0x01, 0x40, 0x00, 0x44, 0x02, 0x58, 0x00, 0x44, 0x00, 0x40,
		  0x00, 0x48, 0x00, 0x40, 0x00, 0x4C, 0x00, 0x40, 0x00, 0x50, 0x00, 0x40, 0x40, 0x23, 0x87, 0xF8,
		  0x33, 0x30, 0x28, 0xE2, 0x80, 0x23, 0x87, 0xF8, 0x33, 0x30, 0x24, 0xE2, 0x7B, 0x68, 0x1B, 0x68,
		  0xB1, 0x4A, 0x93, 0x42, 0x76, 0xD1, 0xB1, 0x4B, 0x5B, 0x6D, 0x03, 0xF0, 0x38, 0x03, 0x28, 0x2B,
		  0x6C, 0xD8, 0x01, 0xA2, 0x52, 0xF8, 0x23, 0xF0, 0x5D, 0x3E, 0x00, 0x08, 0x8D, 0x3E, 0x00, 0x08,
		  0x8D, 0x3E, 0x00, 0x08, 0x8D, 0x3E, 0x00, 0x08, 0x8D, 0x3E, 0x00, 0x08, 0x8D, 0x3E, 0x00, 0x08,
		  0x8D, 0x3E, 0x00, 0x08, 0x8D, 0x3E, 0x00, 0x08, 0x65, 0x3E, 0x00, 0x08, 0x8D, 0x3E, 0x00, 0x08,
		  0x8D, 0x3E, 0x00, 0x08, 0x8D, 0x3E, 0x00, 0x08, 0x8D, 0x3E, 0x00, 0x08, 0x8D, 0x3E, 0x00, 0x08,
		  0x8D, 0x3E, 0x00, 0x08, 0x8D, 0x3E, 0x00, 0x08, 0x6D, 0x3E, 0x00, 0x08, 0x8D, 0x3E, 0x00, 0x08,
		  0x8D, 0x3E, 0x00, 0x08, 0x8D, 0x3E, 0x00, 0x08, 0x8D, 0x3E, 0x00, 0x08, 0x8D, 0x3E, 0x00, 0x08,
		  0x8D, 0x3E, 0x00, 0x08, 0x8D, 0x3E, 0x00, 0x08, 0x75, 0x3E, 0x00, 0x08, 0x8D, 0x3E, 0x00, 0x08,
		  0x8D, 0x3E, 0x00, 0x08, 0x8D, 0x3E, 0x00, 0x08, 0x8D, 0x3E, 0x00, 0x08, 0x8D, 0x3E, 0x00, 0x08,
		  0x8D, 0x3E, 0x00, 0x08, 0x8D, 0x3E, 0x00, 0x08, 0x7D, 0x3E, 0x00, 0x08, 0x8D, 0x3E, 0x00, 0x08,
		  0x8D, 0x3E, 0x00, 0x08, 0x8D, 0x3E, 0x00, 0x08, 0x8D, 0x3E, 0x00, 0x08, 0x8D, 0x3E, 0x00, 0x08,
		  0x8D, 0x3E, 0x00, 0x08, 0x8D, 0x3E, 0x00, 0x08, 0x85, 0x3E, 0x00, 0x08, 0x01, 0x23, 0x87, 0xF8,
		  0x33, 0x30, 0xC0, 0xE1, 0x04, 0x23, 0x87, 0xF8, 0x33, 0x30, 0xBC, 0xE1, 0x08, 0x23, 0x87, 0xF8,
		  0x33, 0x30, 0xB8, 0xE1, 0x10, 0x23, 0x87, 0xF8, 0x33, 0x30, 0xB4, 0xE1, 0x20, 0x23, 0x87, 0xF8,
		  0x33, 0x30, 0xB0, 0xE1, 0x40, 0x23, 0x87, 0xF8, 0x33, 0x30, 0xAC, 0xE1, 0x80, 0x23, 0x87, 0xF8,
		  0x33, 0x30, 0xA8, 0xE1, 0x7B, 0x68, 0x1B, 0x68, 0x75, 0x4A, 0x93, 0x42, 0x30, 0xD1, 0x73, 0x4B,
		  0x5B, 0x6D, 0x03, 0xF0, 0x07, 0x03, 0x05, 0x2B, 0x26, 0xD8, 0x01, 0xA2, 0x52, 0xF8, 0x23, 0xF0,
		  0xC9, 0x3E, 0x00, 0x08, 0xD1, 0x3E, 0x00, 0x08, 0xD9, 0x3E, 0x00, 0x08, 0xE1, 0x3E, 0x00, 0x08,
		  0xE9, 0x3E, 0x00, 0x08, 0xF1, 0x3E, 0x00, 0x08, 0x00, 0x23, 0x87, 0xF8, 0x33, 0x30, 0x8A, 0xE1,
		  0x04, 0x23, 0x87, 0xF8, 0x33, 0x30, 0x86, 0xE1, 0x08, 0x23, 0x87, 0xF8, 0x33, 0x30, 0x82, 0xE1,
		  0x10, 0x23, 0x87, 0xF8, 0x33, 0x30, 0x7E, 0xE1, 0x20, 0x23, 0x87, 0xF8, 0x33, 0x30, 0x7A, 0xE1,
		  0x40, 0x23, 0x87, 0xF8, 0x33, 0x30, 0x76, 0xE1, 0x80, 0x23, 0x87, 0xF8, 0x33, 0x30, 0x72, 0xE1,
		  0x7B, 0x68, 0x1B, 0x68, 0x5B, 0x4A, 0x93, 0x42, 0x30, 0xD1, 0x58, 0x4B, 0x5B, 0x6D, 0x03, 0xF0,
		  0x07, 0x03, 0x05, 0x2B, 0x26, 0xD8, 0x01, 0xA2, 0x52, 0xF8, 0x23, 0xF0, 0x35, 0x3F, 0x00, 0x08,
		  0x3D, 0x3F, 0x00, 0x08, 0x45, 0x3F, 0x00, 0x08, 0x4D, 0x3F, 0x00, 0x08, 0x55, 0x3F, 0x00, 0x08,
		  0x5D, 0x3F, 0x00, 0x08, 0x00, 0x23, 0x87, 0xF8, 0x33, 0x30, 0x54, 0xE1, 0x04, 0x23, 0x87, 0xF8,
		  0x33, 0x30, 0x50, 0xE1, 0x08, 0x23, 0x87, 0xF8, 0x33, 0x30, 0x4C, 0xE1, 0x10, 0x23, 0x87, 0xF8,
		  0x33, 0x30, 0x48, 0xE1, 0x20, 0x23, 0x87, 0xF8, 0x33, 0x30, 0x44, 0xE1, 0x40, 0x23, 0x87, 0xF8,
		  0x33, 0x30, 0x40, 0xE1, 0x80, 0x23, 0x87, 0xF8, 0x33, 0x30, 0x3C, 0xE1, 0x7B, 0x68, 0x1B, 0x68,
		  0x41, 0x4A, 0x93, 0x42, 0x40, 0xF0, 0x82, 0x80, 0x3C, 0x4B, 0x5B, 0x6D, 0x03, 0xF0, 0x38, 0x03,
		  0x28, 0x2B, 0x6D, 0xD8, 0x01, 0xA2, 0x52, 0xF8, 0x23, 0xF0, 0x00, 0xBF, 0x31, 0x40, 0x00, 0x08,
		  0x61, 0x40, 0x00, 0x08, 0x61, 0x40, 0x00, 0x08, 0x61, 0x40, 0x00, 0x08, 0x61, 0x40, 0x00, 0x08,
		  0x61, 0x40, 0x00, 0x08, 0x61, 0x40, 0x00, 0x08, 0x61, 0x40, 0x00, 0x08, 0x39, 0x40, 0x00, 0x08,
		  0x61, 0x40, 0x00, 0x08, 0x61, 0x40, 0x00, 0x08, 0x61, 0x40, 0x00, 0x08, 0x61, 0x40, 0x00, 0x08,
		  0x61, 0x40, 0x00, 0x08, 0x61, 0x40, 0x00, 0x08, 0x61, 0x40, 0x00, 0x08, 0x41, 0x40, 0x00, 0x08,
		  0x61, 0x40, 0x00, 0x08, 0x61, 0x40, 0x00, 0x08, 0x61, 0x40, 0x00, 0x08, 0x61, 0x40, 0x00, 0x08,
		  0x61, 0x40, 0x00, 0x08, 0x61, 0x40, 0x00, 0x08, 0x61, 0x40, 0x00, 0x08, 0x49, 0x40, 0x00, 0x08,
		  0x61, 0x40, 0x00, 0x08, 0x61, 0x40, 0x00, 0x08, 0x61, 0x40, 0x00, 0x08, 0x61, 0x40, 0x00, 0x08,
		  0x61, 0x40, 0x00, 0x08, 0x61, 0x40, 0x00, 0x08, 0x61, 0x40, 0x00, 0x08, 0x51, 0x40, 0x00, 0x08,
		  0x61, 0x40, 0x00, 0x08, 0x61, 0x40, 0x00, 0x08, 0x61, 0x40, 0x00, 0x08, 0x61, 0x40, 0x00, 0x08,
		  0x61, 0x40, 0x00, 0x08, 0x61, 0x40, 0x00, 0x08, 0x61, 0x40, 0x00, 0x08, 0x59, 0x40, 0x00, 0x08,
		  0x01, 0x23, 0x87, 0xF8, 0x33, 0x30, 0xD6, 0xE0, 0x04, 0x23, 0x87, 0xF8, 0x33, 0x30, 0xD2, 0xE0,
		  0x08, 0x23, 0x87, 0xF8, 0x33, 0x30, 0xCE, 0xE0, 0x10, 0x23, 0x87, 0xF8, 0x33, 0x30, 0xCA, 0xE0,
		  0x20, 0x23, 0x87, 0xF8, 0x33, 0x30, 0xC6, 0xE0, 0x40, 0x23, 0x87, 0xF8, 0x33, 0x30, 0xC2, 0xE0,
		  0x80, 0x23, 0x87, 0xF8, 0x33, 0x30, 0xBE, 0xE0, 0x00, 0x14, 0x01, 0x40, 0x00, 0x44, 0x02, 0x58,
		  0x00, 0x78, 0x00, 0x40, 0x00, 0x7C, 0x00, 0x40, 0x00, 0x18, 0x01, 0x40, 0x7B, 0x68, 0x1B, 0x68,
		  0xAD, 0x4A, 0x93, 0x42, 0x76, 0xD1, 0xAD, 0x4B, 0x5B, 0x6D, 0x03, 0xF0, 0x38, 0x03, 0x28, 0x2B,
		  0x6C, 0xD8, 0x01, 0xA2, 0x52, 0xF8, 0x23, 0xF0, 0x3D, 0x41, 0x00, 0x08, 0x6D, 0x41, 0x00, 0x08,
		  0x6D, 0x41, 0x00, 0x08, 0x6D, 0x41, 0x00, 0x08, 0x6D, 0x41, 0x00, 0x08, 0x6D, 0x41, 0x00, 0x08,
		  0x6D, 0x41, 0x00, 0x08, 0x6D, 0x41, 0x00, 0x08, 0x45, 0x41, 0x00, 0x08, 0x6D, 0x41, 0x00, 0x08,
		  0x6D, 0x41, 0x00, 0x08, 0x6D, 0x41, 0x00, 0x08, 0x6D, 0x41, 0x00, 0x08, 0x6D, 0x41, 0x00, 0x08,
		  0x6D, 0x41, 0x00, 0x08, 0x6D, 0x41, 0x00, 0x08, 0x4D, 0x41, 0x00, 0x08, 0x6D, 0x41, 0x00, 0x08,
		  0x6D, 0x41, 0x00, 0x08, 0x6D, 0x41, 0x00, 0x08, 0x6D, 0x41, 0x00, 0x08, 0x6D, 0x41, 0x00, 0x08,
		  0x6D, 0x41, 0x00, 0x08, 0x6D, 0x41, 0x00, 0x08, 0x55, 0x41, 0x00, 0x08, 0x6D, 0x41, 0x00, 0x08,
		  0x6D, 0x41, 0x00, 0x08, 0x6D, 0x41, 0x00, 0x08, 0x6D, 0x41, 0x00, 0x08, 0x6D, 0x41, 0x00, 0x08,
		  0x6D, 0x41, 0x00, 0x08, 0x6D, 0x41, 0x00, 0x08, 0x5D, 0x41, 0x00, 0x08, 0x6D, 0x41, 0x00, 0x08,
		  0x6D, 0x41, 0x00, 0x08, 0x6D, 0x41, 0x00, 0x08, 0x6D, 0x41, 0x00, 0x08, 0x6D, 0x41, 0x00, 0x08,
		  0x6D, 0x41, 0x00, 0x08, 0x6D, 0x41, 0x00, 0x08, 0x65, 0x41, 0x00, 0x08, 0x01, 0x23, 0x87, 0xF8,
		  0x33, 0x30, 0x50, 0xE0, 0x04, 0x23, 0x87, 0xF8, 0x33, 0x30, 0x4C, 0xE0, 0x08, 0x23, 0x87, 0xF8,
		  0x33, 0x30, 0x48, 0xE0, 0x10, 0x23, 0x87, 0xF8, 0x33, 0x30, 0x44, 0xE0, 0x20, 0x23, 0x87, 0xF8,
		  0x33, 0x30, 0x40, 0xE0, 0x40, 0x23, 0x87, 0xF8, 0x33, 0x30, 0x3C, 0xE0, 0x80, 0x23, 0x87, 0xF8,
		  0x33, 0x30, 0x38, 0xE0, 0x7B, 0x68, 0x1B, 0x68, 0x71, 0x4A, 0x93, 0x42, 0x30, 0xD1, 0x6F, 0x4B,
		  0x9B, 0x6D, 0x03, 0xF0, 0x07, 0x03, 0x05, 0x2B, 0x26, 0xD8, 0x01, 0xA2, 0x52, 0xF8, 0x23, 0xF0,
		  0xA9, 0x41, 0x00, 0x08, 0xB1, 0x41, 0x00, 0x08, 0xB9, 0x41, 0x00, 0x08, 0xC1, 0x41, 0x00, 0x08,
		  0xC9, 0x41, 0x00, 0x08, 0xD1, 0x41, 0x00, 0x08, 0x02, 0x23, 0x87, 0xF8, 0x33, 0x30, 0x1A, 0xE0,
		  0x04, 0x23, 0x87, 0xF8, 0x33, 0x30, 0x16, 0xE0, 0x08, 0x23, 0x87, 0xF8, 0x33, 0x30, 0x12, 0xE0,
		  0x10, 0x23, 0x87, 0xF8, 0x33, 0x30, 0x0E, 0xE0, 0x20, 0x23, 0x87, 0xF8, 0x33, 0x30, 0x0A, 0xE0,
		  0x40, 0x23, 0x87, 0xF8, 0x33, 0x30, 0x06, 0xE0, 0x80, 0x23, 0x87, 0xF8, 0x33, 0x30, 0x02, 0xE0,
		  0x80, 0x23, 0x87, 0xF8, 0x33, 0x30, 0x7B, 0x68, 0x1B, 0x68, 0x55, 0x4A, 0x93, 0x42, 0x40, 0xF0,
		  0xF0, 0x80, 0x97, 0xF8, 0x33, 0x30, 0x20, 0x2B, 0x46, 0xDC, 0x02, 0x2B, 0x75, 0xDB, 0x02, 0x3B,
		  0x1E, 0x2B, 0x72, 0xD8, 0x01, 0xA2, 0x52, 0xF8, 0x23, 0xF0, 0x00, 0xBF, 0x8F, 0x42, 0x00, 0x08,
		  0xEB, 0x42, 0x00, 0x08, 0x97, 0x42, 0x00, 0x08, 0xEB, 0x42, 0x00, 0x08, 0xEB, 0x42, 0x00, 0x08,
		  0xEB, 0x42, 0x00, 0x08, 0xA7, 0x42, 0x00, 0x08, 0xEB, 0x42, 0x00, 0x08, 0xEB, 0x42, 0x00, 0x08,
		  0xEB, 0x42, 0x00, 0x08, 0xEB, 0x42, 0x00, 0x08, 0xEB, 0x42, 0x00, 0x08, 0xEB, 0x42, 0x00, 0x08,
		  0xEB, 0x42, 0x00, 0x08, 0xB7, 0x42, 0x00, 0x08, 0xEB, 0x42, 0x00, 0x08, 0xEB, 0x42, 0x00, 0x08,
		  0xEB, 0x42, 0x00, 0x08, 0xEB, 0x42, 0x00, 0x08, 0xEB, 0x42, 0x00, 0x08, 0xEB, 0x42, 0x00, 0x08,
		  0xEB, 0x42, 0x00, 0x08, 0xEB, 0x42, 0x00, 0x08, 0xEB, 0x42, 0x00, 0x08, 0xEB, 0x42, 0x00, 0x08,
		  0xEB, 0x42, 0x00, 0x08, 0xEB, 0x42, 0x00, 0x08, 0xEB, 0x42, 0x00, 0x08, 0xEB, 0x42, 0x00, 0x08,
		  0xEB, 0x42, 0x00, 0x08, 0xDD, 0x42, 0x00, 0x08, 0x40, 0x2B, 0x2A, 0xD0, 0x2D, 0xE0, 0xFE, 0xF7,
		  0x63, 0xFF, 0xF8, 0x62, 0x2F, 0xE0, 0x07, 0xF1, 0x14, 0x03, 0x18, 0x46, 0xFE, 0xF7, 0x72, 0xFF,
		  0xBB, 0x69, 0xFB, 0x62, 0x27, 0xE0, 0x07, 0xF1, 0x08, 0x03, 0x18, 0x46, 0xFF, 0xF7, 0xBE, 0xF8,
		  0xFB, 0x68, 0xFB, 0x62, 0x1F, 0xE0, 0x21, 0x4B, 0x1B, 0x68, 0x03, 0xF0, 0x20, 0x03, 0x00, 0x2B,
		  0x09, 0xD0, 0x1E, 0x4B, 0x1B, 0x68, 0xDB, 0x08, 0x03, 0xF0, 0x03, 0x03, 0x1D, 0x4A, 0x22, 0xFA,
		  0x03, 0xF3, 0xFB, 0x62, 0x0F, 0xE0, 0x1B, 0x4B, 0xFB, 0x62, 0x0C, 0xE0, 0x1A, 0x4B, 0xFB, 0x62,
		  0x09, 0xE0, 0x4F, 0xF4, 0x00, 0x43, 0xFB, 0x62, 0x05, 0xE0, 0x00, 0x23, 0xFB, 0x62, 0x01, 0x23,
		  0x87, 0xF8, 0x32, 0x30, 0x00, 0xBF, 0xFB, 0x6A, 0x00, 0x2B, 0x00, 0xF0, 0xE6, 0x81, 0x7B, 0x68,
		  0x5B, 0x6A, 0x12, 0x4A, 0x32, 0xF8, 0x13, 0x30, 0x1A, 0x46, 0xFB, 0x6A, 0xB3, 0xFB, 0xF2, 0xF3,
		  0x3B, 0x62, 0x7B, 0x68, 0x5A, 0x68, 0x13, 0x46, 0x5B, 0x00, 0x13, 0x44, 0x3A, 0x6A, 0x9A, 0x42,
		  0x05, 0xD3, 0x7B, 0x68, 0x5B, 0x68, 0x1B, 0x03, 0x3A, 0x6A, 0x9A, 0x42, 0x10, 0xD9, 0x01, 0x23,
		  0x87, 0xF8, 0x32, 0x30, 0xC9, 0xE1, 0x00, 0xBF, 0x00, 0x1C, 0x01, 0x40, 0x00, 0x44, 0x02, 0x58,
		  0x00, 0x0C, 0x00, 0x58, 0x00, 0x90, 0xD0, 0x03, 0x00, 0x09, 0x3D, 0x00, 0xE8, 0x4C, 0x00, 0x08,
		  0xFB, 0x6A, 0x18, 0x46, 0x4F, 0xF0, 0x00, 0x01, 0x7B, 0x68, 0x5B, 0x6A, 0xC1, 0x4A, 0x32, 0xF8,
		  0x13, 0x30, 0x9A, 0xB2, 0x4F, 0xF0, 0x00, 0x03, 0xFB, 0xF7, 0xC0, 0xFF, 0x02, 0x46, 0x0B, 0x46,
		  0x10, 0x46, 0x19, 0x46, 0x4F, 0xF0, 0x00, 0x02, 0x4F, 0xF0, 0x00, 0x03, 0x0B, 0x02, 0x43, 0xEA,
		  0x10, 0x63, 0x02, 0x02, 0x79, 0x68, 0x49, 0x68, 0x49, 0x08, 0x08, 0x46, 0x4F, 0xF0, 0x00, 0x01,
		  0x14, 0x18, 0x43, 0xEB, 0x01, 0x05, 0x7B, 0x68, 0x5B, 0x68, 0x1A, 0x46, 0x4F, 0xF0, 0x00, 0x03,
		  0x20, 0x46, 0x29, 0x46, 0xFB, 0xF7, 0xA2, 0xFF, 0x02, 0x46, 0x0B, 0x46, 0x13, 0x46, 0xBB, 0x62,
		  0xBB, 0x6A, 0xB3, 0xF5, 0x40, 0x7F, 0x08, 0xD3, 0xBB, 0x6A, 0xB3, 0xF5, 0x80, 0x1F, 0x04, 0xD2,
		  0x7B, 0x68, 0x1B, 0x68, 0xBA, 0x6A, 0xDA, 0x60, 0x7F, 0xE1, 0x01, 0x23, 0x87, 0xF8, 0x32, 0x30,
		  0x7B, 0xE1, 0x7B, 0x68, 0xDB, 0x69, 0xB3, 0xF5, 0x00, 0x4F, 0x40, 0xF0, 0xBD, 0x80, 0x97, 0xF8,
		  0x33, 0x30, 0x20, 0x2B, 0x48, 0xDC, 0x00, 0x2B, 0x7B, 0xDB, 0x20, 0x2B, 0x79, 0xD8, 0x01, 0xA2,
		  0x52, 0xF8, 0x23, 0xF0, 0x7F, 0x44, 0x00, 0x08, 0x87, 0x44, 0x00, 0x08, 0xE3, 0x44, 0x00, 0x08,
		  0xE3, 0x44, 0x00, 0x08, 0x8F, 0x44, 0x00, 0x08, 0xE3, 0x44, 0x00, 0x08, 0xE3, 0x44, 0x00, 0x08,
		  0xE3, 0x44, 0x00, 0x08, 0x9F, 0x44, 0x00, 0x08, 0xE3, 0x44, 0x00, 0x08, 0xE3, 0x44, 0x00, 0x08,
		  0xE3, 0x44, 0x00, 0x08, 0xE3, 0x44, 0x00, 0x08, 0xE3, 0x44, 0x00, 0x08, 0xE3, 0x44, 0x00, 0x08,
		  0xE3, 0x44, 0x00, 0x08, 0xAF, 0x44, 0x00, 0x08, 0xE3, 0x44, 0x00, 0x08, 0xE3, 0x44, 0x00, 0x08,
		  0xE3, 0x44, 0x00, 0x08, 0xE3, 0x44, 0x00, 0x08, 0xE3, 0x44, 0x00, 0x08, 0xE3, 0x44, 0x00, 0x08,
		  0xE3, 0x44, 0x00, 0x08, 0xE3, 0x44, 0x00, 0x08, 0xE3, 0x44, 0x00, 0x08, 0xE3, 0x44, 0x00, 0x08,
		  0xE3, 0x44, 0x00, 0x08, 0xE3, 0x44, 0x00, 0x08, 0xE3, 0x44, 0x00, 0x08, 0xE3, 0x44, 0x00, 0x08,
		  0xE3, 0x44, 0x00, 0x08, 0xD5, 0x44, 0x00, 0x08, 0x40, 0x2B, 0x2E, 0xD0, 0x31, 0xE0, 0xFD, 0xF7,
		  0x33, 0xFF, 0xF8, 0x62, 0x33, 0xE0, 0xFD, 0xF7, 0x45, 0xFF, 0xF8, 0x62, 0x2F, 0xE0, 0x07, 0xF1,
		  0x14, 0x03, 0x18, 0x46, 0xFE, 0xF7, 0x76, 0xFE, 0xBB, 0x69, 0xFB, 0x62, 0x27, 0xE0, 0x07, 0xF1,
		  0x08, 0x03, 0x18, 0x46, 0xFE, 0xF7, 0xC2, 0xFF, 0xFB, 0x68, 0xFB, 0x62, 0x1F, 0xE0, 0x6E, 0x4B,
		  0x1B, 0x68, 0x03, 0xF0, 0x20, 0x03, 0x00, 0x2B, 0x09, 0xD0, 0x6B, 0x4B, 0x1B, 0x68, 0xDB, 0x08,
		  0x03, 0xF0, 0x03, 0x03, 0x69, 0x4A, 0x22, 0xFA, 0x03, 0xF3, 0xFB, 0x62, 0x0F, 0xE0, 0x67, 0x4B,
		  0xFB, 0x62, 0x0C, 0xE0, 0x66, 0x4B, 0xFB, 0x62, 0x09, 0xE0, 0x4F, 0xF4, 0x00, 0x43, 0xFB, 0x62,
		  0x05, 0xE0, 0x00, 0x23, 0xFB, 0x62, 0x01, 0x23, 0x87, 0xF8, 0x32, 0x30, 0x00, 0xBF, 0xFB, 0x6A,
		  0x00, 0x2B, 0x00, 0xF0, 0xEA, 0x80, 0x7B, 0x68, 0x5B, 0x6A, 0x5A, 0x4A, 0x32, 0xF8, 0x13, 0x30,
		  0x1A, 0x46, 0xFB, 0x6A, 0xB3, 0xFB, 0xF2, 0xF3, 0x5A, 0x00, 0x7B, 0x68, 0x5B, 0x68, 0x5B, 0x08,
		  0x1A, 0x44, 0x7B, 0x68, 0x5B, 0x68, 0xB2, 0xFB, 0xF3, 0xF3, 0xBB, 0x62, 0xBB, 0x6A, 0x0F, 0x2B,
		  0x16, 0xD9, 0xBB, 0x6A, 0xB3, 0xF5, 0x80, 0x3F, 0x12, 0xD2, 0xBB, 0x6A, 0x9B, 0xB2, 0x23, 0xF0,
		  0x0F, 0x03, 0xFB, 0x84, 0xBB, 0x6A, 0x5B, 0x08, 0x9B, 0xB2, 0x03, 0xF0, 0x07, 0x03, 0x9A, 0xB2,
		  0xFB, 0x8C, 0x13, 0x43, 0xFB, 0x84, 0x7B, 0x68, 0x1B, 0x68, 0xFA, 0x8C, 0xDA, 0x60, 0xBC, 0xE0,
		  0x01, 0x23, 0x87, 0xF8, 0x32, 0x30, 0xB8, 0xE0, 0x97, 0xF8, 0x33, 0x30, 0x20, 0x2B, 0x4B, 0xDC,
		  0x00, 0x2B, 0xC0, 0xF2, 0x87, 0x80, 0x20, 0x2B, 0x00, 0xF2, 0x84, 0x80, 0x01, 0xA2, 0x52, 0xF8,
		  0x23, 0xF0, 0x00, 0xBF, 0xFF, 0x45, 0x00, 0x08, 0x07, 0x46, 0x00, 0x08, 0x75, 0x46, 0x00, 0x08,
		  0x75, 0x46, 0x00, 0x08, 0x0F, 0x46, 0x00, 0x08, 0x75, 0x46, 0x00, 0x08, 0x75, 0x46, 0x00, 0x08,
		  0x75, 0x46, 0x00, 0x08, 0x1F, 0x46, 0x00, 0x08, 0x75, 0x46, 0x00, 0x08, 0x75, 0x46, 0x00, 0x08,
		  0x75, 0x46, 0x00, 0x08, 0x75, 0x46, 0x00, 0x08, 0x75, 0x46, 0x00, 0x08, 0x75, 0x46, 0x00, 0x08,
		  0x75, 0x46, 0x00, 0x08, 0x2F, 0x46, 0x00, 0x08, 0x75, 0x46, 0x00, 0x08, 0x75, 0x46, 0x00, 0x08,
		  0x75, 0x46, 0x00, 0x08, 0x75, 0x46, 0x00, 0x08, 0x75, 0x46, 0x00, 0x08, 0x75, 0x46, 0x00, 0x08,
		  0x75, 0x46, 0x00, 0x08, 0x75, 0x46, 0x00, 0x08, 0x75, 0x46, 0x00, 0x08, 0x75, 0x46, 0x00, 0x08,
		  0x75, 0x46, 0x00, 0x08, 0x75, 0x46, 0x00, 0x08, 0x75, 0x46, 0x00, 0x08, 0x75, 0x46, 0x00, 0x08,
		  0x75, 0x46, 0x00, 0x08, 0x55, 0x46, 0x00, 0x08, 0x40, 0x2B, 0x2E, 0xD0, 0x3A, 0xE0, 0xFD, 0xF7,
		  0x73, 0xFE, 0xF8, 0x62, 0x3C, 0xE0, 0xFD, 0xF7, 0x85, 0xFE, 0xF8, 0x62, 0x38, 0xE0, 0x07, 0xF1,
		  0x14, 0x03, 0x18, 0x46, 0xFE, 0xF7, 0xB6, 0xFD, 0xBB, 0x69, 0xFB, 0x62, 0x30, 0xE0, 0x07, 0xF1,
		  0x08, 0x03, 0x18, 0x46, 0xFE, 0xF7, 0x02, 0xFF, 0xFB, 0x68, 0xFB, 0x62, 0x28, 0xE0, 0x0E, 0x4B,
		  0x1B, 0x68, 0x03, 0xF0, 0x20, 0x03, 0x00, 0x2B, 0x09, 0xD0, 0x0B, 0x4B, 0x1B, 0x68, 0xDB, 0x08,
		  0x03, 0xF0, 0x03, 0x03, 0x09, 0x4A, 0x22, 0xFA, 0x03, 0xF3, 0xFB, 0x62, 0x18, 0xE0, 0x07, 0x4B,
		  0xFB, 0x62, 0x15, 0xE0, 0x06, 0x4B, 0xFB, 0x62, 0x12, 0xE0, 0x4F, 0xF4, 0x00, 0x43, 0xFB, 0x62,
		  0x0E, 0xE0, 0x00, 0xBF, 0xE8, 0x4C, 0x00, 0x08, 0x00, 0x44, 0x02, 0x58, 0x00, 0x90, 0xD0, 0x03,
		  0x00, 0x09, 0x3D, 0x00, 0x00, 0x23, 0xFB, 0x62, 0x01, 0x23, 0x87, 0xF8, 0x32, 0x30, 0x00, 0xBF,
		  0xFB, 0x6A, 0x00, 0x2B, 0x21, 0xD0, 0x7B, 0x68, 0x5B, 0x6A, 0x1A, 0x4A, 0x32, 0xF8, 0x13, 0x30,
		  0x1A, 0x46, 0xFB, 0x6A, 0xB3, 0xFB, 0xF2, 0xF2, 0x7B, 0x68, 0x5B, 0x68, 0x5B, 0x08, 0x1A, 0x44,
		  0x7B, 0x68, 0x5B, 0x68, 0xB2, 0xFB, 0xF3, 0xF3, 0xBB, 0x62, 0xBB, 0x6A, 0x0F, 0x2B, 0x09, 0xD9,
		  0xBB, 0x6A, 0xB3, 0xF5, 0x80, 0x3F, 0x05, 0xD2, 0xBB, 0x6A, 0x9A, 0xB2, 0x7B, 0x68, 0x1B, 0x68,
		  0xDA, 0x60, 0x02, 0xE0, 0x01, 0x23, 0x87, 0xF8, 0x32, 0x30, 0x7B, 0x68, 0x01, 0x22, 0xA3, 0xF8,
		  0x6A, 0x20, 0x7B, 0x68, 0x01, 0x22, 0xA3, 0xF8, 0x68, 0x20, 0x7B, 0x68, 0x00, 0x22, 0x1A, 0x67,
		  0x7B, 0x68, 0x00, 0x22, 0x5A, 0x67, 0x97, 0xF8, 0x32, 0x30, 0x18, 0x46, 0x38, 0x37, 0xBD, 0x46,
		  0xB0, 0xBD, 0x00, 0xBF, 0xE8, 0x4C, 0x00, 0x08, 0x80, 0xB4, 0x83, 0xB0, 0x00, 0xAF, 0x78, 0x60,
		  0x7B, 0x68, 0x9B, 0x6A, 0x03, 0xF0, 0x01, 0x03, 0x00, 0x2B, 0x0A, 0xD0, 0x7B, 0x68, 0x1B, 0x68,
		  0x5B, 0x68, 0x23, 0xF4, 0x00, 0x31, 0x7B, 0x68, 0xDA, 0x6A, 0x7B, 0x68, 0x1B, 0x68, 0x0A, 0x43,
		  0x5A, 0x60, 0x7B, 0x68, 0x9B, 0x6A, 0x03, 0xF0, 0x02, 0x03, 0x00, 0x2B, 0x0A, 0xD0, 0x7B, 0x68,
		  0x1B, 0x68, 0x5B, 0x68, 0x23, 0xF4, 0x80, 0x31, 0x7B, 0x68, 0x1A, 0x6B, 0x7B, 0x68, 0x1B, 0x68,
		  0x0A, 0x43, 0x5A, 0x60, 0x7B, 0x68, 0x9B, 0x6A, 0x03, 0xF0, 0x04, 0x03, 0x00, 0x2B, 0x0A, 0xD0,
		  0x7B, 0x68, 0x1B, 0x68, 0x5B, 0x68, 0x23, 0xF4, 0x80, 0x21, 0x7B, 0x68, 0x5A, 0x6B, 0x7B, 0x68,
		  0x1B, 0x68, 0x0A, 0x43, 0x5A, 0x60, 0x7B, 0x68, 0x9B, 0x6A, 0x03, 0xF0, 0x08, 0x03, 0x00, 0x2B,
		  0x0A, 0xD0, 0x7B, 0x68, 0x1B, 0x68, 0x5B, 0x68, 0x23, 0xF4, 0x00, 0x41, 0x7B, 0x68, 0x9A, 0x6B,
		  0x7B, 0x68, 0x1B, 0x68, 0x0A, 0x43, 0x5A, 0x60, 0x7B, 0x68, 0x9B, 0x6A, 0x03, 0xF0, 0x10, 0x03,
		  0x00, 0x2B, 0x0A, 0xD0, 0x7B, 0x68, 0x1B, 0x68, 0x9B, 0x68, 0x23, 0xF4, 0x80, 0x51, 0x7B, 0x68,
		  0xDA, 0x6B, 0x7B, 0x68, 0x1B, 0x68, 0x0A, 0x43, 0x9A, 0x60, 0x7B, 0x68, 0x9B, 0x6A, 0x03, 0xF0,
		  0x20, 0x03, 0x00, 0x2B, 0x0A, 0xD0, 0x7B, 0x68, 0x1B, 0x68, 0x9B, 0x68, 0x23, 0xF4, 0x00, 0x51,
		  0x7B, 0x68, 0x1A, 0x6C, 0x7B, 0x68, 0x1B, 0x68, 0x0A, 0x43, 0x9A, 0x60, 0x7B, 0x68, 0x9B, 0x6A,
		  0x03, 0xF0, 0x40, 0x03, 0x00, 0x2B, 0x1A, 0xD0, 0x7B, 0x68, 0x1B, 0x68, 0x5B, 0x68, 0x23, 0xF4,
		  0x80, 0x11, 0x7B, 0x68, 0x5A, 0x6C, 0x7B, 0x68, 0x1B, 0x68, 0x0A, 0x43, 0x5A, 0x60, 0x7B, 0x68,
		  0x5B, 0x6C, 0xB3, 0xF5, 0x80, 0x1F, 0x0A, 0xD1, 0x7B, 0x68, 0x1B, 0x68, 0x5B, 0x68, 0x23, 0xF4,
		  0xC0, 0x01, 0x7B, 0x68, 0x9A, 0x6C, 0x7B, 0x68, 0x1B, 0x68, 0x0A, 0x43, 0x5A, 0x60, 0x7B, 0x68,
		  0x9B, 0x6A, 0x03, 0xF0, 0x80, 0x03, 0x00, 0x2B, 0x0A, 0xD0, 0x7B, 0x68, 0x1B, 0x68, 0x5B, 0x68,
		  0x23, 0xF4, 0x00, 0x21, 0x7B, 0x68, 0xDA, 0x6C, 0x7B, 0x68, 0x1B, 0x68, 0x0A, 0x43, 0x5A, 0x60,
		  0x00, 0xBF, 0x0C, 0x37, 0xBD, 0x46, 0x5D, 0xF8, 0x04, 0x7B, 0x70, 0x47, 0x80, 0xB5, 0x86, 0xB0,
		  0x02, 0xAF, 0x78, 0x60, 0x7B, 0x68, 0x00, 0x22, 0xC3, 0xF8, 0x8C, 0x20, 0xFC, 0xF7, 0x96, 0xFA,
		  0xF8, 0x60, 0x7B, 0x68, 0x1B, 0x68, 0x1B, 0x68, 0x03, 0xF0, 0x08, 0x03, 0x08, 0x2B, 0x0E, 0xD1,
		  0x6F, 0xF0, 0x7E, 0x43, 0x00, 0x93, 0xFB, 0x68, 0x00, 0x22, 0x4F, 0xF4, 0x00, 0x11, 0x78, 0x68,
		  0x00, 0xF0, 0x2F, 0xF8, 0x03, 0x46, 0x00, 0x2B, 0x01, 0xD0, 0x03, 0x23, 0x25, 0xE0, 0x7B, 0x68,
		  0x1B, 0x68, 0x1B, 0x68, 0x03, 0xF0, 0x04, 0x03, 0x04, 0x2B, 0x0E, 0xD1, 0x6F, 0xF0, 0x7E, 0x43,
		  0x00, 0x93, 0xFB, 0x68, 0x00, 0x22, 0x4F, 0xF4, 0x80, 0x01, 0x78, 0x68, 0x00, 0xF0, 0x19, 0xF8,
		  0x03, 0x46, 0x00, 0x2B, 0x01, 0xD0, 0x03, 0x23, 0x0F, 0xE0, 0x7B, 0x68, 0x20, 0x22, 0xC3, 0xF8,
		  0x84, 0x20, 0x7B, 0x68, 0x20, 0x22, 0xC3, 0xF8, 0x88, 0x20, 0x7B, 0x68, 0x00, 0x22, 0xDA, 0x66,
		  0x7B, 0x68, 0x00, 0x22, 0x83, 0xF8, 0x80, 0x20, 0x00, 0x23, 0x18, 0x46, 0x10, 0x37, 0xBD, 0x46,
		  0x80, 0xBD, 0x80, 0xB5, 0x9C, 0xB0, 0x00, 0xAF, 0xF8, 0x60, 0xB9, 0x60, 0x3B, 0x60, 0x13, 0x46,
		  0xFB, 0x71, 0xA9, 0xE0, 0xBB, 0x6F, 0xB3, 0xF1, 0xFF, 0x3F, 0x00, 0xF0, 0xA5, 0x80, 0xFC, 0xF7,
		  0x45, 0xFA, 0x02, 0x46, 0x3B, 0x68, 0xD3, 0x1A, 0xBA, 0x6F, 0x9A, 0x42, 0x02, 0xD3, 0xBB, 0x6F,
		  0x00, 0x2B, 0x40, 0xD1, 0xFB, 0x68, 0x1B, 0x68, 0x3B, 0x65, 0x3B, 0x6D, 0x53, 0xE8, 0x00, 0x3F,
		  0xFB, 0x64, 0xFB, 0x6C, 0x23, 0xF4, 0xD0, 0x73, 0x7B, 0x66, 0xFB, 0x68, 0x1B, 0x68, 0x1A, 0x46,
		  0x7B, 0x6E, 0xFB, 0x65, 0xBA, 0x65, 0xB9, 0x6D, 0xFA, 0x6D, 0x41, 0xE8, 0x00, 0x23, 0x7B, 0x65,
		  0x7B, 0x6D, 0x00, 0x2B, 0xE6, 0xD1, 0xFB, 0x68, 0x1B, 0x68, 0x08, 0x33, 0xFB, 0x63, 0xFB, 0x6B,
		  0x53, 0xE8, 0x00, 0x3F, 0xBB, 0x63, 0xBB, 0x6B, 0x23, 0xF0, 0x01, 0x03, 0x3B, 0x66, 0xFB, 0x68,
		  0x1B, 0x68, 0x08, 0x33, 0x3A, 0x6E, 0xBA, 0x64, 0x7B, 0x64, 0x79, 0x6C, 0xBA, 0x6C, 0x41, 0xE8,
		  0x00, 0x23, 0x3B, 0x64, 0x3B, 0x6C, 0x00, 0x2B, 0xE5, 0xD1, 0xFB, 0x68, 0x20, 0x22, 0xC3, 0xF8,
		  0x84, 0x20, 0xFB, 0x68, 0x20, 0x22, 0xC3, 0xF8, 0x88, 0x20, 0xFB, 0x68, 0x00, 0x22, 0x83, 0xF8,
		  0x80, 0x20, 0x03, 0x23, 0x69, 0xE0, 0xFB, 0x68, 0x1B, 0x68, 0x1B, 0x68, 0x03, 0xF0, 0x04, 0x03,
		  0x00, 0x2B, 0x51, 0xD0, 0xFB, 0x68, 0x1B, 0x68, 0xDB, 0x69, 0x03, 0xF4, 0x00, 0x63, 0xB3, 0xF5,
		  0x00, 0x6F, 0x49, 0xD1, 0xFB, 0x68, 0x1B, 0x68, 0x4F, 0xF4, 0x00, 0x62, 0x1A, 0x62, 0xFB, 0x68,
		  0x1B, 0x68, 0xBB, 0x62, 0xBB, 0x6A, 0x53, 0xE8, 0x00, 0x3F, 0x7B, 0x62, 0x7B, 0x6A, 0x23, 0xF4,
		  0xD0, 0x73, 0xFB, 0x66, 0xFB, 0x68, 0x1B, 0x68, 0x1A, 0x46, 0xFB, 0x6E, 0x7B, 0x63, 0x3A, 0x63,
		  0x39, 0x6B, 0x7A, 0x6B, 0x41, 0xE8, 0x00, 0x23, 0xFB, 0x62, 0xFB, 0x6A, 0x00, 0x2B, 0xE6, 0xD1,
		  0xFB, 0x68, 0x1B, 0x68, 0x08, 0x33, 0x7B, 0x61, 0x7B, 0x69, 0x53, 0xE8, 0x00, 0x3F, 0x3B, 0x61,
		  0x3B, 0x69, 0x23, 0xF0, 0x01, 0x03, 0xBB, 0x66, 0xFB, 0x68, 0x1B, 0x68, 0x08, 0x33, 0xBA, 0x6E,
		  0x3A, 0x62, 0xFB, 0x61, 0xF9, 0x69, 0x3A, 0x6A, 0x41, 0xE8, 0x00, 0x23, 0xBB, 0x61, 0xBB, 0x69,
		  0x00, 0x2B, 0xE5, 0xD1, 0xFB, 0x68, 0x20, 0x22, 0xC3, 0xF8, 0x84, 0x20, 0xFB, 0x68, 0x20, 0x22,
		  0xC3, 0xF8, 0x88, 0x20, 0xFB, 0x68, 0x20, 0x22, 0xC3, 0xF8, 0x8C, 0x20, 0xFB, 0x68, 0x00, 0x22,
		  0x83, 0xF8, 0x80, 0x20, 0x03, 0x23, 0x10, 0xE0, 0xFB, 0x68, 0x1B, 0x68, 0xDA, 0x69, 0xBB, 0x68,
		  0x13, 0x40, 0xBA, 0x68, 0x9A, 0x42, 0x0C, 0xBF, 0x01, 0x23, 0x00, 0x23, 0xDB, 0xB2, 0x1A, 0x46,
		  0xFB, 0x79, 0x9A, 0x42, 0x3F, 0xF4, 0x46, 0xAF, 0x00, 0x23, 0x18, 0x46, 0x70, 0x37, 0xBD, 0x46,
		  0x80, 0xBD, 0x80, 0xB4, 0x85, 0xB0, 0x00, 0xAF, 0x78, 0x60, 0x7B, 0x68, 0x93, 0xF8, 0x80, 0x30,
		  0x01, 0x2B, 0x01, 0xD1, 0x02, 0x23, 0x27, 0xE0, 0x7B, 0x68, 0x01, 0x22, 0x83, 0xF8, 0x80, 0x20,
		  0x7B, 0x68, 0x24, 0x22, 0xC3, 0xF8, 0x84, 0x20, 0x7B, 0x68, 0x1B, 0x68, 0x1B, 0x68, 0xFB, 0x60,
		  0x7B, 0x68, 0x1B, 0x68, 0x1A, 0x68, 0x7B, 0x68, 0x1B, 0x68, 0x22, 0xF0, 0x01, 0x02, 0x1A, 0x60,
		  0xFB, 0x68, 0x23, 0xF0, 0x00, 0x53, 0xFB, 0x60, 0x7B, 0x68, 0x00, 0x22, 0x5A, 0x66, 0x7B, 0x68,
		  0x1B, 0x68, 0xFA, 0x68, 0x1A, 0x60, 0x7B, 0x68, 0x20, 0x22, 0xC3, 0xF8, 0x84, 0x20, 0x7B, 0x68,
		  0x00, 0x22, 0x83, 0xF8, 0x80, 0x20, 0x00, 0x23, 0x18, 0x46, 0x14, 0x37, 0xBD, 0x46, 0x5D, 0xF8,
		  0x04, 0x7B, 0x70, 0x47, 0x80, 0xB5, 0x84, 0xB0, 0x00, 0xAF, 0x78, 0x60, 0x39, 0x60, 0x7B, 0x68,
		  0x93, 0xF8, 0x80, 0x30, 0x01, 0x2B, 0x01, 0xD1, 0x02, 0x23, 0x2D, 0xE0, 0x7B, 0x68, 0x01, 0x22,
		  0x83, 0xF8, 0x80, 0x20, 0x7B, 0x68, 0x24, 0x22, 0xC3, 0xF8, 0x84, 0x20, 0x7B, 0x68, 0x1B, 0x68,
		  0x1B, 0x68, 0xFB, 0x60, 0x7B, 0x68, 0x1B, 0x68, 0x1A, 0x68, 0x7B, 0x68, 0x1B, 0x68, 0x22, 0xF0,
		  0x01, 0x02, 0x1A, 0x60, 0x7B, 0x68, 0x1B, 0x68, 0x9B, 0x68, 0x23, 0xF0, 0x60, 0x41, 0x7B, 0x68,
		  0x1B, 0x68, 0x3A, 0x68, 0x0A, 0x43, 0x9A, 0x60, 0x78, 0x68, 0x00, 0xF0, 0x4F, 0xF8, 0x7B, 0x68,
		  0x1B, 0x68, 0xFA, 0x68, 0x1A, 0x60, 0x7B, 0x68, 0x20, 0x22, 0xC3, 0xF8, 0x84, 0x20, 0x7B, 0x68,
		  0x00, 0x22, 0x83, 0xF8, 0x80, 0x20, 0x00, 0x23, 0x18, 0x46, 0x10, 0x37, 0xBD, 0x46, 0x80, 0xBD,
		  0x80, 0xB5, 0x84, 0xB0, 0x00, 0xAF, 0x78, 0x60, 0x39, 0x60, 0x7B, 0x68, 0x93, 0xF8, 0x80, 0x30,
		  0x01, 0x2B, 0x01, 0xD1, 0x02, 0x23, 0x2D, 0xE0, 0x7B, 0x68, 0x01, 0x22, 0x83, 0xF8, 0x80, 0x20,
		  0x7B, 0x68, 0x24, 0x22, 0xC3, 0xF8, 0x84, 0x20, 0x7B, 0x68, 0x1B, 0x68, 0x1B, 0x68, 0xFB, 0x60,
		  0x7B, 0x68, 0x1B, 0x68, 0x1A, 0x68, 0x7B, 0x68, 0x1B, 0x68, 0x22, 0xF0, 0x01, 0x02, 0x1A, 0x60,
		  0x7B, 0x68, 0x1B, 0x68, 0x9B, 0x68, 0x23, 0xF0, 0x60, 0x61, 0x7B, 0x68, 0x1B, 0x68, 0x3A, 0x68,
		  0x0A, 0x43, 0x9A, 0x60, 0x78, 0x68, 0x00, 0xF0, 0x11, 0xF8, 0x7B, 0x68, 0x1B, 0x68, 0xFA, 0x68,
		  0x1A, 0x60, 0x7B, 0x68, 0x20, 0x22, 0xC3, 0xF8, 0x84, 0x20, 0x7B, 0x68, 0x00, 0x22, 0x83, 0xF8,
		  0x80, 0x20, 0x00, 0x23, 0x18, 0x46, 0x10, 0x37, 0xBD, 0x46, 0x80, 0xBD, 0x80, 0xB4, 0x85, 0xB0,
		  0x00, 0xAF, 0x78, 0x60, 0x7B, 0x68, 0x5B, 0x6E, 0x00, 0x2B, 0x08, 0xD1, 0x7B, 0x68, 0x01, 0x22,
		  0xA3, 0xF8, 0x6A, 0x20, 0x7B, 0x68, 0x01, 0x22, 0xA3, 0xF8, 0x68, 0x20, 0x31, 0xE0, 0x10, 0x23,
		  0xFB, 0x73, 0x10, 0x23, 0xBB, 0x73, 0x7B, 0x68, 0x1B, 0x68, 0x9B, 0x68, 0x5B, 0x0E, 0xDB, 0xB2,
		  0x03, 0xF0, 0x07, 0x03, 0x7B, 0x73, 0x7B, 0x68, 0x1B, 0x68, 0x9B, 0x68, 0x5B, 0x0F, 0xDB, 0xB2,
		  0x03, 0xF0, 0x07, 0x03, 0x3B, 0x73, 0xBB, 0x7B, 0x3A, 0x7B, 0x11, 0x49, 0x8A, 0x5C, 0x02, 0xFB,
		  0x03, 0xF3, 0x3A, 0x7B, 0x0F, 0x49, 0x8A, 0x5C, 0x93, 0xFB, 0xF2, 0xF3, 0x9A, 0xB2, 0x7B, 0x68,
		  0xA3, 0xF8, 0x6A, 0x20, 0xFB, 0x7B, 0x7A, 0x7B, 0x09, 0x49, 0x8A, 0x5C, 0x02, 0xFB, 0x03, 0xF3,
		  0x7A, 0x7B, 0x08, 0x49, 0x8A, 0x5C, 0x93, 0xFB, 0xF2, 0xF3, 0x9A, 0xB2, 0x7B, 0x68, 0xA3, 0xF8,
		  0x68, 0x20, 0x00, 0xBF, 0x14, 0x37, 0xBD, 0x46, 0x5D, 0xF8, 0x04, 0x7B, 0x70, 0x47, 0x00, 0xBF,
		  0x00, 0x4D, 0x00, 0x08, 0x08, 0x4D, 0x00, 0x08, 0x70, 0xB5, 0x0D, 0x4D, 0x0D, 0x4C, 0x64, 0x1B,
		  0xA4, 0x10, 0x00, 0x26, 0xA6, 0x42, 0x09, 0xD1, 0x0B, 0x4D, 0x0C, 0x4C, 0x00, 0xF0, 0x20, 0xF8,
		  0x64, 0x1B, 0xA4, 0x10, 0x00, 0x26, 0xA6, 0x42, 0x05, 0xD1, 0x70, 0xBD, 0x55, 0xF8, 0x04, 0x3B,
		  0x98, 0x47, 0x01, 0x36, 0xEE, 0xE7, 0x55, 0xF8, 0x04, 0x3B, 0x98, 0x47, 0x01, 0x36, 0xF2, 0xE7,
		  0x18, 0x4D, 0x00, 0x08, 0x18, 0x4D, 0x00, 0x08, 0x18, 0x4D, 0x00, 0x08, 0x1C, 0x4D, 0x00, 0x08,
		  0x02, 0x44, 0x03, 0x46, 0x93, 0x42, 0x00, 0xD1, 0x70, 0x47, 0x03, 0xF8, 0x01, 0x1B, 0xF9, 0xE7,
		  0xF8, 0xB5, 0x00, 0xBF, 0xF8, 0xBC, 0x08, 0xBC, 0x9E, 0x46, 0x70, 0x47, 0xF8, 0xB5, 0x00, 0xBF,
		  0xF8, 0xBC, 0x08, 0xBC, 0x9E, 0x46, 0x70, 0x47, 0x00, 0x00, 0x00, 0x00, 0x01, 0x02, 0x03, 0x04,
		  0x01, 0x02, 0x03, 0x04, 0x06, 0x07, 0x08, 0x09, 0x01, 0x00, 0x02, 0x00, 0x04, 0x00, 0x06, 0x00,
		  0x08, 0x00, 0x0A, 0x00, 0x0C, 0x00, 0x10, 0x00, 0x20, 0x00, 0x40, 0x00, 0x80, 0x00, 0x00, 0x01,
		  0x01, 0x01, 0x01, 0x03, 0x07, 0x01, 0x00, 0x00, 0x08, 0x04, 0x02, 0x04, 0x08, 0x01, 0x01, 0x01,
		  0x0C, 0xB6, 0xFF, 0x7F, 0x01, 0x00, 0x00, 0x00, 0xD1, 0x02, 0x00, 0x08, 0xAD, 0x02, 0x00, 0x08,
		  0x00, 0x90, 0xD0, 0x03, 0x00, 0x90, 0xD0, 0x03, 0x10, 0x00, 0x00, 0x00, 0x01, 0x00, 0x00, 0x00
};
/* USER CODE END PV */

void SystemClock_Config(void);
static void MX_GPIO_Init(void);
static void MX_USART1_UART_Init(void);
static void MX_USART2_UART_Init(void);
/* USER CODE BEGIN PFP */
void target_reset(void);
static uint8_t xor_checksum(const uint8_t pData[], uint16_t len);
void enter_boot(void);
void exit_boot(void);
void BL_Invoke_UART(void);
void wait_for_ack_byte(UART_HandleTypeDef *huart1, uint8_t *recv);
void BL_Get_Cmd(uint8_t *pData);
uint8_t BL_GetVersion_Command(void);
void BL_WriteMemory_Command(uint32_t address, uint16_t nob, uint8_t *pData);
void BL_EraseMemory_Command(uint16_t nob, uint8_t code);
/* USER CODE END PFP */

int main(void)
{
  /* USER CODE BEGIN 1 */
  /*<! bootloader version command declarations >*/
  uint8_t version = 0x00;
  uint8_t aRxBuffer[256] = {0};

  /*<! erase memory command declarations >*/
  uint16_t how_much_sec = 0x00FF; //0xff for global
  uint8_t where_to_start = 0x00;

  /*<! bootloader write to flash command declarations >*/
//  uint16_t size_to_write = sizeof(bin_to_flash)/sizeof(bin_to_flash[0]);
//  int temp = 256;
//  uint32_t addr_to_write = 0x08000000;
//  uint16_t byte_to_write = 0x0100; //max 256 bytes can be written at a time
//  uint8_t addr_frame[5];
//  uint8_t n = byte_to_write - 0x0001;
//  uint16_t bytes_remains_to_w = size_to_write;
//  uint8_t checksum;
//  int where = 0;
  uint32_t write_to_flash_host = 0x08000000;
  uint16_t size_to_flash_host = sizeof(bin_to_flash)/sizeof(bin_to_flash[0]);

  /*<! bootloader read from flash command declarations >*/
  uint32_t read_addr = 0x08000000;
  uint8_t bytes_to_read = 0x44;

  /*<! bootloader go command declarations >*/
  uint8_t addr_frame_go[5];
  uint32_t addr_to_go = 0x08000000;
  /* USER CODE END 1 */

  /* MCU Configuration--------------------------------------------------------*/

  /* Reset of all peripherals, Initializes the Flash interface and the Systick. */
  HAL_Init();

  /* Configure the system clock */
  SystemClock_Config();

  /* Initialize all configured peripherals */
  MX_GPIO_Init();
  MX_USART1_UART_Init();
  MX_USART2_UART_Init();
  /* USER CODE BEGIN 2 */
  enter_boot();
  target_reset();

//  HAL_UART_Receive(&huart1, &receive_cmd_response_main, 1, 1000); //receive this one byte & ignore the same
  wait_for_ack_byte(&huart1, &receive_cmd_response_main); //receive this one byte & ignore the same
//  HAL_UART_Transmit(&huart2, &receive_cmd_response_main, 1, 1000);

  /* <!-- invoke bootloader UART > */
  BL_Invoke_UART();
//  HAL_UART_Transmit(&huart1, &invoke_uart, 1, 100);
////  HAL_UART_Receive(&huart1, &receive_cmd_response_main, 1, 1000); //receive ACK/NACK byte
//  wait_for_ack_byte(&huart1, &receive_cmd_response_main); //receive ACK/NACK byte
//  HAL_UART_Transmit(&huart2, &receive_cmd_response_main, 1, 100);
////  HAL_UART_Transmit(&huart2, &invoke_uart, 1, 1000);
////  HAL_UART_Transmit(&huart2, &receive_cmd_response_main, 1, 100);

  /* <!-- get command > */

  BL_Get_Cmd(aRxBuffer);
////  HAL_UART_Receive(&huart1, &receive_cmd_response_main, 1, 1000); //dummy read - 0x79
//  wait_for_ack_byte(&huart1, &receive_cmd_response_main);
//  HAL_UART_Transmit(&huart2, &receive_cmd_response_main, 1, 100);
//  HAL_UART_Receive(&huart1, &receive_cmd_response_main, 1, 1000); //length of data to receive - 0x0b
//  HAL_UART_Transmit(&huart2, &receive_cmd_response_main, 1, 100);
//  HAL_UART_Receive(&huart1, (uint8_t *)aRxBuffer, (uint16_t)(receive_cmd_response_main+1), 1000);
//  HAL_UART_Transmit(&huart2, (uint8_t *)aRxBuffer, (uint16_t)(receive_cmd_response_main+1), 1000);

  /* <!-- bootloader version command > */
  version = BL_GetVersion_Command();
  HAL_UART_Transmit(&huart2, &version, 1, 100);
//  HAL_UART_Transmit(&huart1, bl_ver, 2, 100);
//  HAL_UART_Receive(&huart1, &receive_cmd_response_main, 1, 1000);
////  HAL_UART_Transmit(&huart2, &receive_cmd_response_main, 1, 100);
//
//  HAL_UART_Receive(&huart1, &receive_cmd_response_main, 1, 1000);
////  HAL_UART_Transmit(&huart2, &receive_cmd_response_main, 1, 100);
//
//  HAL_UART_Receive(&huart1, &receive_cmd_response_main, 1, 1000);
//  HAL_UART_Transmit(&huart2, &receive_cmd_response_main, 1, 100);

  /* Check GetVersion is equal to GetCommand version */
  if (version != aRxBuffer[0])
  {
    Error_Handler();
  }

  /* <!-- get ID command > */
//  HAL_UART_Transmit(&huart1, get_id_cmd, 2, 100);
//  HAL_UART_Receive(&huart1, &receive_cmd_response_main, 1, 1000); //dummy read - 0x79
//  HAL_UART_Transmit(&huart2, &receive_cmd_response_main, 1, 100);
//  HAL_UART_Receive(&huart1, &receive_cmd_response_main, 1, 1000); //length of data to receive - 0x0b
//  HAL_UART_Transmit(&huart2, &receive_cmd_response_main, 1, 100);
//  HAL_UART_Receive(&huart1, (uint8_t *)aRxBuffer, (uint16_t)(receive_cmd_response_main+1), 1000);
//  HAL_UART_Transmit(&huart2, (uint8_t *)aRxBuffer, (uint16_t)(receive_cmd_response_main+1), 1000);
////  uint8_t id = ((uint16_t) aRxBuffer[0] << 8) | (aRxBuffer[1]);
////  HAL_UART_Transmit(&huart2, &id, (uint16_t)(1), 1000);

  /* <!-- clear device flash command > */
//  BL_EraseMemory_Command(how_much_sec, where_to_start);

  /* <!-- write to device RAM command > */
//  BL_WriteMemory_Command(write_to_flash_host, size_to_flash_host, &bin_to_flash[0]);

//  uint32_t addr_to_write = 0x08000000;
//  uint32_t dummy_data = 0xDEADBEEF;
//  uint8_t byte_to_write = 4;
//  uint8_t addr_frame[5];
//  uint8_t n = byte_to_write - 1;
//  uint8_t checksum = xor_checksum((uint8_t*)&dummy_data, byte_to_write) ^ n;
//
//  HAL_UART_Transmit(&huart1, write_memory_cmd, 2, 1000);
//  HAL_UART_Receive(&huart1, &receive_cmd_response_main, 1, 100); //receive the ACK/NACK byte
//  addr_frame[0] = ((uint8_t) (addr_to_write >> 24) & 0xFFU);
//  addr_frame[1] = ((uint8_t) (addr_to_write >> 16) & 0xFFU);
//  addr_frame[2] = ((uint8_t) (addr_to_write >> 8) & 0xFFU);
//  addr_frame[3] = ((uint8_t) addr_to_write & 0xFFU);
//  addr_frame[4] = xor_checksum(addr_frame, 4U);
//
//  HAL_UART_Transmit(&huart1, addr_frame, 5, 1000);
//  HAL_UART_Receive(&huart1, &receive_cmd_response_main, 1, 100); //receive the ACK/NACK byte
//
//  HAL_UART_Transmit(&huart1, &n, 1, 1000);
//  HAL_UART_Transmit(&huart1, (uint8_t *)&dummy_data, byte_to_write, 1000);
//  HAL_UART_Transmit(&huart1, &checksum, 1, 1000);
//
//  HAL_UART_Receive(&huart1, &receive_cmd_response_main, 1, 1000); //receive the ACK/NACK byte
//  HAL_UART_Transmit(&huart2, &receive_cmd_response_main, 1, 100);

  /* <!-- clear device RAM command - globally > */
//  uint8_t data_frame[3];
//  uint8_t global_erase = 0xFF;
//  uint8_t no_sec_erase = 0x01 - 1;
//  HAL_UART_Transmit(&huart1, clear_memory_cmd, 2, 1000);
//  HAL_UART_Receive(&huart1, &receive_cmd_response_main, 1, 1000); //receive the ACK/NACK byte
//  HAL_UART_Transmit(&huart2, &receive_cmd_response_main, 1, 100);
//
//  HAL_UART_Transmit(&huart1, &global_erase, 1, 1000); //send 0xff to request the global erase
//
//  data_frame[0] = global_erase; //0xFF - for global erase
//  data_frame[1] = 0x00; //0x00 - for global erase
//  data_frame[2] = data_frame[0] ^ data_frame[1];
//  HAL_UART_Transmit(&huart1, data_frame, 3, 1000);
//
//  HAL_UART_Receive(&huart1, &receive_cmd_response_main, 1, 1000); //receive the ACK/NACK byte
//  HAL_UART_Transmit(&huart2, &receive_cmd_response_main, 1, 100);

  /* <!-- read data from flash > */
  BL_ReadMemory_Command(read_addr, bytes_to_read, aRxBuffer);

//  uint8_t addr_frame[5];
//  uint32_t address = 0x08000000;
//  uint8_t nob_frame[2];
//  uint8_t nob = 4;
//
//  HAL_UART_Transmit(&huart1, read_memory_cmd, 2, 1000);
//  HAL_UART_Receive(&huart1, &receive_cmd_response_main, 1, 1000); //receive the ACK/NACK byte
//  HAL_UART_Transmit(&huart2, &receive_cmd_response_main, 1, 100);
//
//  addr_frame[0] = (uint8_t) ((address >> 24) & 0xFFU);
//  addr_frame[1] = (uint8_t) ((address >> 16) & 0xFFU);
//  addr_frame[2] = (uint8_t) ((address >> 8) & 0xFFU);
//  addr_frame[3] = (uint8_t) (address & 0xFFU);
//  addr_frame[4] = xor_checksum(addr_frame, 4U);
//
//  HAL_UART_Transmit(&huart1, addr_frame, 5, 1000);
//
//  HAL_UART_Receive(&huart1, &receive_cmd_response_main, 1, 1000); //receive the ACK/NACK byte
//  HAL_UART_Transmit(&huart2, &receive_cmd_response_main, 1, 100);
//
//  nob_frame[0] = (nob - 1U);
//  nob_frame[1] = (nob - 1U) ^ 0xFFU;
//
//  HAL_UART_Transmit(&huart1, nob_frame, 2, 1000);
//  HAL_UART_Receive(&huart1, &receive_cmd_response_main, 1, 1000); //receive the ACK/NACK byte
//  HAL_UART_Transmit(&huart2, &receive_cmd_response_main, 1, 100);
//
//  HAL_UART_Receive(&huart1, aRxBuffer, (uint16_t)nob, 1000);
//  HAL_UART_Transmit(&huart2, aRxBuffer, (uint16_t)nob, 1000);

  /* <!- write whole binary to the target device's flash - H7A3 > */

//  for(int i = 0; i<size_to_write; i+=byte_to_write){

//  while(bytes_remains_to_w != 0x0000){
////	uint32_t combined = (bin_to_flash[i+3] << 24) | (bin_to_flash[i+2] << 16) | ( bin_to_flash[i+1] << 8 ) | (bin_to_flash[i+0]);
//
//	HAL_UART_Transmit(&huart1, write_memory_cmd, 2, 1000);
//	HAL_UART_Receive(&huart1, &receive_cmd_response_main, 1, 100); //receive the ACK/NACK byte
//	HAL_UART_Transmit(&huart2, &receive_cmd_response_main, 1, 100);
//
//	addr_frame[0] = ((uint8_t) (addr_to_write >> 24) & 0xFFU);
//	addr_frame[1] = ((uint8_t) (addr_to_write >> 16) & 0xFFU);
//	addr_frame[2] = ((uint8_t) (addr_to_write >> 8) & 0xFFU);
//	addr_frame[3] = ((uint8_t) addr_to_write & 0xFFU);
//	addr_frame[4] = xor_checksum(addr_frame, 4U);
//
//	HAL_UART_Transmit(&huart1, addr_frame, 5, 1000);
//	HAL_UART_Receive(&huart1, &receive_cmd_response_main, 1, 100); //receive the ACK/NACK byte
//	HAL_UART_Transmit(&huart2, &receive_cmd_response_main, 1, 100);
//
//	if(bytes_remains_to_w < (byte_to_write)){
//		n = bytes_remains_to_w - 1;
//		HAL_UART_Transmit(&huart1, (uint8_t *)&n, 1, 1000);
//		checksum = xor_checksum(&bin_to_flash[where], bytes_remains_to_w) ^ n;
//		HAL_UART_Transmit(&huart1, &bin_to_flash[where], (uint16_t)bytes_remains_to_w, 1000);
//		bytes_remains_to_w = 0x0000;
//	} else{
//		HAL_UART_Transmit(&huart1, (uint8_t *)&n, 1, 1000);
//		checksum = xor_checksum(&bin_to_flash[where], (byte_to_write)) ^ n;
//		HAL_UART_Transmit(&huart1, &bin_to_flash[where], (byte_to_write), 1000);
//		if(receive_cmd_response_main == 0x79){
//			bytes_remains_to_w -= (byte_to_write); //subtract 4(byte_to_write) eachtime from the bytes_remain_to_w we write to the flash
//		}
//	}
//
//	HAL_UART_Transmit(&huart1, &checksum, 1, 1000);
//	HAL_UART_Transmit(&huart2, &receive_cmd_response_main, 1, 100);
//
//	HAL_UART_Receive(&huart1, &receive_cmd_response_main, 1, 1000); //receive the ACK/NACK byte
//	HAL_UART_Transmit(&huart2, &receive_cmd_response_main, 1, 100);
//	if(receive_cmd_response_main == 0x79)
//	{
//		addr_to_write += (uint32_t)(byte_to_write); //increment address by 4(byte_to_write) bytes once we transfer the 32bits of data
//		where += temp;
//	//	HAL_UART_Transmit(&huart2, (uint8_t *)&addr_to_write, 4, 100);
//	}
//  }
//
//  /* <!-- go command > */
//  HAL_UART_Transmit(&huart1, go_cmd, 2, 100);
//  HAL_UART_Receive(&huart1, &receive_cmd_response_main, 1, 1000);
//  HAL_UART_Transmit(&huart2, &receive_cmd_response_main, 1, 100);
//
//  addr_frame_go[0] = ((uint8_t) (addr_to_go >> 24) & 0xFFU);
//  addr_frame_go[1] = ((uint8_t) (addr_to_go >> 16) & 0xFFU);
//  addr_frame_go[2] = ((uint8_t) (addr_to_go >> 8) & 0xFFU);
//  addr_frame_go[3] = ((uint8_t) addr_to_go & 0xFFU);
//  addr_frame_go[4] = xor_checksum(addr_frame_go, 4U);
//  HAL_UART_Transmit(&huart1, addr_frame_go, 5, 1000);
//
//  HAL_UART_Receive(&huart1, &receive_cmd_response_main, 1, 1000); //receive the ACK/NACK byte
//  HAL_UART_Transmit(&huart2, &receive_cmd_response_main, 1, 100);

//  exit_boot();

  /* USER CODE END 2 */

  /* Infinite loop */
  while (1)
  {

    /* USER CODE BEGIN 3 */
//	  HAL_UART_Receive(&huart2, &data_to_receive, 50, 5000);
//	  HAL_UART_Transmit(&huart2, &data_to_receive, strlen(data_to_receive), 100);
//	  HAL_Delay(1000);
  }
  /* USER CODE END 3 */
}

void SystemClock_Config(void)
{
  RCC_OscInitTypeDef RCC_OscInitStruct = {0};
  RCC_ClkInitTypeDef RCC_ClkInitStruct = {0};

  /** Configure the main internal regulator output voltage
  */
  __HAL_RCC_PWR_CLK_ENABLE();
  __HAL_PWR_VOLTAGESCALING_CONFIG(PWR_REGULATOR_VOLTAGE_SCALE2);

  /** Initializes the RCC Oscillators according to the specified parameters
  * in the RCC_OscInitTypeDef structure.
  */
  RCC_OscInitStruct.OscillatorType = RCC_OSCILLATORTYPE_HSI;
  RCC_OscInitStruct.HSIState = RCC_HSI_ON;
  RCC_OscInitStruct.HSICalibrationValue = RCC_HSICALIBRATION_DEFAULT;
  RCC_OscInitStruct.PLL.PLLState = RCC_PLL_ON;
  RCC_OscInitStruct.PLL.PLLSource = RCC_PLLSOURCE_HSI;
  RCC_OscInitStruct.PLL.PLLM = 16;
  RCC_OscInitStruct.PLL.PLLN = 336;
  RCC_OscInitStruct.PLL.PLLP = RCC_PLLP_DIV4;
  RCC_OscInitStruct.PLL.PLLQ = 7;
  if (HAL_RCC_OscConfig(&RCC_OscInitStruct) != HAL_OK)
  {
    Error_Handler();
  }

  /** Initializes the CPU, AHB and APB buses clocks
  */
  RCC_ClkInitStruct.ClockType = RCC_CLOCKTYPE_HCLK|RCC_CLOCKTYPE_SYSCLK
                              |RCC_CLOCKTYPE_PCLK1|RCC_CLOCKTYPE_PCLK2;
  RCC_ClkInitStruct.SYSCLKSource = RCC_SYSCLKSOURCE_PLLCLK;
  RCC_ClkInitStruct.AHBCLKDivider = RCC_SYSCLK_DIV1;
  RCC_ClkInitStruct.APB1CLKDivider = RCC_HCLK_DIV2;
  RCC_ClkInitStruct.APB2CLKDivider = RCC_HCLK_DIV1;

  if (HAL_RCC_ClockConfig(&RCC_ClkInitStruct, FLASH_LATENCY_2) != HAL_OK)
  {
    Error_Handler();
  }
}

static void MX_USART1_UART_Init(void)
{

  huart1.Instance = USART1;
  huart1.Init.BaudRate = 115200;
  huart1.Init.WordLength = UART_WORDLENGTH_9B;
  huart1.Init.StopBits = UART_STOPBITS_1;
  huart1.Init.Parity = UART_PARITY_EVEN;
  huart1.Init.Mode = UART_MODE_TX_RX;
  huart1.Init.HwFlowCtl = UART_HWCONTROL_NONE;
  huart1.Init.OverSampling = UART_OVERSAMPLING_16;
  if (HAL_UART_Init(&huart1) != HAL_OK)
  {
    Error_Handler();
  }

}

static void MX_USART2_UART_Init(void)
{

  huart2.Instance = USART2;
  huart2.Init.BaudRate = 115200;
  huart2.Init.WordLength = UART_WORDLENGTH_8B;
  huart2.Init.StopBits = UART_STOPBITS_1;
  huart2.Init.Parity = UART_PARITY_NONE;
  huart2.Init.Mode = UART_MODE_TX_RX;
  huart2.Init.HwFlowCtl = UART_HWCONTROL_NONE;
  huart2.Init.OverSampling = UART_OVERSAMPLING_16;
  if (HAL_UART_Init(&huart2) != HAL_OK)
  {
    Error_Handler();
  }

}

static void MX_GPIO_Init(void)
{
  GPIO_InitTypeDef GPIO_InitStruct = {0};

  /* GPIO Ports Clock Enable */
  __HAL_RCC_GPIOC_CLK_ENABLE();
  __HAL_RCC_GPIOH_CLK_ENABLE();
  __HAL_RCC_GPIOA_CLK_ENABLE();
  __HAL_RCC_GPIOB_CLK_ENABLE();

  /*Configure GPIO pin Output Level */
  HAL_GPIO_WritePin(LD2_GPIO_Port, LD2_Pin, GPIO_PIN_RESET);

  /*Configure GPIO pin Output Level */
  HAL_GPIO_WritePin(GPIOC, GPIO_PIN_8|GPIO_PIN_9, GPIO_PIN_RESET);

  /*Configure GPIO pin : B1_Pin */
  GPIO_InitStruct.Pin = B1_Pin;
  GPIO_InitStruct.Mode = GPIO_MODE_IT_FALLING;
  GPIO_InitStruct.Pull = GPIO_NOPULL;
  HAL_GPIO_Init(B1_GPIO_Port, &GPIO_InitStruct);

  /*Configure GPIO pin : LD2_Pin */
  GPIO_InitStruct.Pin = LD2_Pin;
  GPIO_InitStruct.Mode = GPIO_MODE_OUTPUT_PP;
  GPIO_InitStruct.Pull = GPIO_NOPULL;
  GPIO_InitStruct.Speed = GPIO_SPEED_FREQ_LOW;
  HAL_GPIO_Init(LD2_GPIO_Port, &GPIO_InitStruct);

  /*Configure GPIO pins : PC8 PC9 */
  GPIO_InitStruct.Pin = GPIO_PIN_8|GPIO_PIN_9;
  GPIO_InitStruct.Mode = GPIO_MODE_OUTPUT_PP;
  GPIO_InitStruct.Pull = GPIO_NOPULL;
  GPIO_InitStruct.Speed = GPIO_SPEED_FREQ_LOW;
  HAL_GPIO_Init(GPIOC, &GPIO_InitStruct);

}

/* USER CODE BEGIN 4 */

void HAL_UART_RxCpltCallback(UART_HandleTypeDef *huart){
	HAL_UART_Receive_IT(&huart2, &it_response, 1);
}
/* USER CODE END 4 */

void Error_Handler(void)
{
  __disable_irq();
  while (1)
  {
  }
}
